AUTOSAR XML (schema 00051)
standard types defined: boolean, uint8, uint16, uint32, uint64, sint8, sint16, sint32
package /LionDriver  # Description of the existing LionDriver system in AUTOSAR terms, for OEM/Tier-1 integration. Neither the panda safety firmware (bare-metal STM32) nor openpilot (Linux processes) is an AUTOSAR stack. This file is not an AUTOSAR implementation and not a compliance claim; it carries no evidence credit.
package /LionDriver/ImplementationDataTypes
  impl type ByteBuffer: category=ARRAY  # Opaque bytes of variable length: a serialised cereal (Cap'n Proto) message, or the response of a control request. The bound is the 16-bit length field of a control request (WP-S-05 §4.2), used as an upper bound for the description only
    element byte: array-size=65535, array-size-semantics=VARIABLE-SIZE, implementation-data-type=uint8
  impl type CanPacket: category=ARRAY  # One CAN packet of the SPI stream (WP-S-05 §4.3): 6 header bytes and up to 64 payload bytes, with the 8-bit XOR checksum in byte 5
    element byte: array-size=70, array-size-semantics=VARIABLE-SIZE, implementation-data-type=uint8
package /LionDriver/Units
  unit km_per_h: display-name=km/h
  unit m_per_s2: display-name=m/s^2
  unit N: display-name=N
package /LionDriver/CompuMethods
  compu method WHEEL_SPEEDS_WHEEL_SPEED_FR: phys=raw*0.01-67.67; unit km/h  # phys = offset + factor × raw, from the DBC
  compu method WHEEL_SPEEDS_WHEEL_SPEED_FL: phys=raw*0.01-67.67; unit km/h  # phys = offset + factor × raw, from the DBC
  compu method WHEEL_SPEEDS_WHEEL_SPEED_RR: phys=raw*0.01-67.67; unit km/h  # phys = offset + factor × raw, from the DBC
  compu method WHEEL_SPEEDS_WHEEL_SPEED_RL: phys=raw*0.01-67.67; unit km/h  # phys = offset + factor × raw, from the DBC
  compu method SPEED_SPEED: phys=raw*0.01; unit km/h  # phys = offset + factor × raw, from the DBC
  compu method STEERING_LTA_ANGLE: phys=raw*0.5  # phys = offset + factor × raw, from the DBC
  compu method STEERING_LTA_STEER_ANGLE_CMD: phys=raw*0.0573  # phys = offset + factor × raw, from the DBC
  compu method PCM_CRUISE_ACCEL_NET: phys=raw/1024; unit m/s^2  # phys = offset + factor × raw, from the DBC
  compu method PCM_CRUISE_NEUTRAL_FORCE: phys=raw*2; unit N  # phys = offset + factor × raw, from the DBC
  compu method PCM_CRUISE_2_SET_SPEED: phys=raw; unit km/h  # phys = offset + factor × raw, from the DBC
  compu method STEER_TORQUE_SENSOR_STEER_ANGLE: phys=raw*0.0573  # phys = offset + factor × raw, from the DBC
  compu method PRE_COLLISION_FORCE: phys=raw*2; unit N  # phys = offset + factor × raw, from the DBC
  compu method ACC_CONTROL_ACCEL_CMD: phys=raw*0.001; unit m/s^2  # phys = offset + factor × raw, from the DBC
  compu method ACC_CONTROL_ACCEL_CMD_ALT: phys=raw*0.05; unit m/s^2  # phys = offset + factor × raw, from the DBC
  compu method PRE_COLLISION_2_DSS1GDRV: phys=raw*0.1; unit m/s^2  # phys = offset + factor × raw, from the DBC
package /LionDriver/PortInterfaces
  28 x sender receiver interface:
    If_WHEEL_SPEEDS  # The signals of CAN frame 0x0aa WHEEL_SPEEDS, one data element each (DBC opendbc_repo/opendbc/dbc/generator/toyota/_toyota_2017.dbc)
      8 x data:
        WHEEL_SPEED_FR_FAULT: type=boolean
        WHEEL_SPEED_FR: compu-method=WHEEL_SPEEDS_WHEEL_SPEED_FR, type=uint16
        WHEEL_SPEED_FL_FAULT: type=boolean
        WHEEL_SPEED_FL: compu-method=WHEEL_SPEEDS_WHEEL_SPEED_FL, type=uint16
        WHEEL_SPEED_RR_FAULT: type=boolean
        WHEEL_SPEED_RR: compu-method=WHEEL_SPEEDS_WHEEL_SPEED_RR, type=uint16
        WHEEL_SPEED_RL_FAULT: type=boolean
        WHEEL_SPEED_RL: compu-method=WHEEL_SPEEDS_WHEEL_SPEED_RL, type=uint16
    If_SPEED  # The signals of CAN frame 0x0b4 SPEED, one data element each (DBC opendbc_repo/opendbc/dbc/generator/toyota/_toyota_2017.dbc)
      data ENCODER: type=uint8
      data SPEED: compu-method=SPEED_SPEED, type=uint16
      data CHECKSUM: type=uint8
    If_STEERING_LTA  # The signals of CAN frame 0x191 STEERING_LTA, one data element each (DBC opendbc_repo/opendbc/dbc/generator/toyota/toyota_nodsu_pt.dbc)
      12 x data:
        CHECKSUM: type=uint8
        SETME_X3: type=uint8
        PERCENTAGE: type=uint8
        TORQUE_WIND_DOWN: type=uint8
        ANGLE: compu-method=STEERING_LTA_ANGLE, type=sint8
        STEER_ANGLE_CMD: compu-method=STEERING_LTA_STEER_ANGLE_CMD, type=sint16
        STEER_REQUEST_2: type=boolean
        LKA_ACTIVE: type=boolean
        CLEAR_HOLD_STEERING_ALERT: type=boolean
        COUNTER: type=uint8
        STEER_REQUEST: type=boolean
        SETME_X1: type=boolean
    If_PCM_CRUISE  # The signals of CAN frame 0x1d2 PCM_CRUISE, one data element each (DBC opendbc_repo/opendbc/dbc/generator/toyota/_toyota_adas_standard.dbc)
      8 x data:
        GAS_RELEASED: type=boolean
        CRUISE_ACTIVE: type=boolean
        ACC_BRAKING: type=boolean
        ACCEL_NET: compu-method=PCM_CRUISE_ACCEL_NET, type=sint16
        NEUTRAL_FORCE: compu-method=PCM_CRUISE_NEUTRAL_FORCE, type=sint16
        CRUISE_STATE: type=uint8
        CANCEL_REQ: type=boolean
        CHECKSUM: type=uint8
    If_PCM_CRUISE_2  # The signals of CAN frame 0x1d3 PCM_CRUISE_2, one data element each (DBC opendbc_repo/opendbc/dbc/generator/toyota/_toyota_2017.dbc)
      7 x data:
        BRAKE_PRESSED: type=boolean
        PCM_FOLLOW_DISTANCE: type=uint8
        LOW_SPEED_LOCKOUT: type=uint8
        MAIN_ON: type=boolean
        SET_SPEED: compu-method=PCM_CRUISE_2_SET_SPEED, type=uint8
        ACC_FAULTED: type=boolean
        CHECKSUM: type=uint8
    If_BRAKE_MODULE  # The signals of CAN frame 0x226 BRAKE_MODULE, one data element each (DBC opendbc_repo/opendbc/dbc/generator/toyota/toyota_nodsu_pt.dbc)
      data BRAKE_PRESSURE: type=uint16
      data BRAKE_POSITION: type=uint16
      data BRAKE_PRESSED: type=boolean
    If_STEER_TORQUE_SENSOR  # The signals of CAN frame 0x260 STEER_TORQUE_SENSOR, one data element each (DBC opendbc_repo/opendbc/dbc/generator/toyota/_toyota_2017.dbc)
      6 x data:
        STEER_TORQUE_EPS: type=sint16
        STEER_TORQUE_DRIVER: type=sint16
        STEER_ANGLE: compu-method=STEER_TORQUE_SENSOR_STEER_ANGLE, type=sint16
        STEER_ANGLE_INITIALIZING: type=boolean
        STEER_OVERRIDE: type=boolean
        CHECKSUM: type=uint8
    If_EPS_STATUS  # The signals of CAN frame 0x262 EPS_STATUS, one data element each (DBC opendbc_repo/opendbc/dbc/generator/toyota/toyota_nodsu_pt.dbc)
      5 x data:
        IPAS_STATE: type=uint8
        LKA_STATE: type=uint8
        LTA_STATE: type=uint8
        TYPE: type=boolean
        CHECKSUM: type=uint8
    If_PRE_COLLISION  # The signals of CAN frame 0x283 PRE_COLLISION, one data element each (DBC opendbc_repo/opendbc/dbc/generator/toyota/_toyota_adas_standard.dbc)
      9 x data:
        COUNTER: type=uint8
        SET_ME_X00: type=uint8
        FORCE: compu-method=PRE_COLLISION_FORCE, type=sint16
        SET_ME_X002: type=uint8
        BRAKE_STATUS: type=uint8
        STATE: type=uint8
        SET_ME_X003: type=boolean
        PRECOLLISION_ACTIVE: type=boolean
        CHECKSUM: type=uint8
    If_STEERING_LKA  # The signals of CAN frame 0x2e4 STEERING_LKA, one data element each (DBC opendbc_repo/opendbc/dbc/generator/toyota/_toyota_adas_standard.dbc)
      6 x data:
        LKA_STATE: type=uint8
        STEER_REQUEST: type=boolean
        COUNTER: type=uint8
        SET_ME_1: type=boolean
        STEER_TORQUE_CMD: type=sint16
        CHECKSUM: type=uint8
    If_ACC_CONTROL  # The signals of CAN frame 0x343 ACC_CONTROL, one data element each (DBC opendbc_repo/opendbc/dbc/generator/toyota/_toyota_2017.dbc)
      15 x data:
        ACCEL_CMD: compu-method=ACC_CONTROL_ACCEL_CMD, type=sint16
        ALLOW_LONG_PRESS: type=uint8
        ACC_MALFUNCTION: type=boolean
        RADAR_DIRTY: type=boolean
        DISTANCE: type=boolean
        MINI_CAR: type=boolean
        ACC_TYPE: type=uint8
        CANCEL_REQ: type=boolean
        ACC_CUT_IN: type=boolean
        LEAD_VEHICLE_STOPPED: type=boolean
        PERMIT_BRAKING: type=boolean
        RELEASE_STANDSTILL: type=boolean
        ITS_CONNECT_LEAD: type=uint8
        ACCEL_CMD_ALT: compu-method=ACC_CONTROL_ACCEL_CMD_ALT, type=sint8
        CHECKSUM: type=uint8
    If_PRE_COLLISION_2  # The signals of CAN frame 0x344 PRE_COLLISION_2, one data element each (DBC opendbc_repo/opendbc/dbc/generator/toyota/_toyota_adas_standard.dbc)
      7 x data:
        DSS1GDRV: compu-method=PRE_COLLISION_2_DSS1GDRV, type=sint16
        PCSALM: type=boolean
        IBTRGR: type=boolean
        PBATRGR: type=uint8
        PREFILL: type=boolean
        AVSTRGR: type=boolean
        CHECKSUM: type=uint8
    If_PCS_HUD  # The signals of CAN frame 0x411 PCS_HUD, one data element each (DBC opendbc_repo/opendbc/dbc/generator/toyota/_toyota_2017.dbc)
      11 x data:
        PCS_INDICATOR: type=uint8
        FCW: type=boolean
        SET_ME_X20: type=uint8
        PCS_DUST: type=boolean
        PCS_TEMP: type=boolean
        PCS_DUST2: type=boolean
        PCS_TEMP2: type=boolean
        SET_ME_X10: type=uint8
        PCS_OFF: type=boolean
        FRD_ADJ: type=uint8
        PCS_SENSITIVITY: type=uint8
    If_LKAS_HUD  # The signals of CAN frame 0x412 LKAS_HUD, one data element each (DBC opendbc_repo/opendbc/dbc/generator/toyota/_toyota_2017.dbc)
      25 x data:
        BARRIERS: type=uint8
        RIGHT_LINE: type=uint8
        LEFT_LINE: type=uint8
        LKAS_STATUS: type=uint8
        LDA_ALERT: type=uint8
        LDW_EXIST: type=boolean
        TWO_BEEPS: type=boolean
        ADJUSTING_CAMERA: type=boolean
        LDA_UNAVAILABLE_QUIET: type=boolean
        LDA_MALFUNCTION: type=boolean
        LDA_UNAVAILABLE: type=boolean
        LDA_SENSITIVITY: type=uint8
        LDA_SA_TOGGLE: type=uint8
        LDA_MESSAGES: type=uint8
        LDA_ON_MESSAGE: type=uint8
        REPEATED_BEEPS: type=boolean
        LANE_SWAY_TOGGLE: type=boolean
        LANE_SWAY_SENSITIVITY: type=uint8
        TAKE_CONTROL: type=boolean
        LDA_FRONT_CAMERA_BLOCKED: type=boolean
        LANE_SWAY_BUZZER: type=uint8
        LANE_SWAY_FLD: type=uint8
        LANE_SWAY_WARNING: type=uint8
        SET_ME_X01: type=boolean
        SET_ME_X02: type=uint8
    If_Cereal_can  # cereal service 'can' (msgq publish/subscribe on the SoC; Cap'n Proto schema in cereal/)
      data can: type=ByteBuffer
    If_Cereal_carControl  # cereal service 'carControl' (msgq publish/subscribe on the SoC; Cap'n Proto schema in cereal/)
      data carControl: type=ByteBuffer
    If_Cereal_carOutput  # cereal service 'carOutput' (msgq publish/subscribe on the SoC; Cap'n Proto schema in cereal/)
      data carOutput: type=ByteBuffer
    If_Cereal_carState  # cereal service 'carState' (msgq publish/subscribe on the SoC; Cap'n Proto schema in cereal/)
      data carState: type=ByteBuffer
    If_Cereal_deviceState  # cereal service 'deviceState' (msgq publish/subscribe on the SoC; Cap'n Proto schema in cereal/)
      data deviceState: type=ByteBuffer
    If_Cereal_driverMonitoringState  # cereal service 'driverMonitoringState' (msgq publish/subscribe on the SoC; Cap'n Proto schema in cereal/)
      data driverMonitoringState: type=ByteBuffer
    If_Cereal_extrinsicsCalibration_deviceMotion_vehicleParameters_lateralTorqueParameters_lateralDelay  # cereal service 'extrinsicsCalibration, deviceMotion, vehicleParameters, lateralTorqueParameters, lateralDelay' (msgq publish/subscribe on the SoC; Cap'n Proto schema in cereal/)
      data extrinsicsCalibration_deviceMotion_vehicleParameters_lateralTorqueParameters_lateralDelay: type=ByteBuffer
    If_Cereal_longitudinalPlan  # cereal service 'longitudinalPlan' (msgq publish/subscribe on the SoC; Cap'n Proto schema in cereal/)
      data longitudinalPlan: type=ByteBuffer
    If_Cereal_modelV2  # cereal service 'modelV2' (msgq publish/subscribe on the SoC; Cap'n Proto schema in cereal/)
      data modelV2: type=ByteBuffer
    If_Cereal_onroadEvents  # cereal service 'onroadEvents' (msgq publish/subscribe on the SoC; Cap'n Proto schema in cereal/)
      data onroadEvents: type=ByteBuffer
    If_Cereal_pandaStates  # cereal service 'pandaStates' (msgq publish/subscribe on the SoC; Cap'n Proto schema in cereal/)
      data pandaStates: type=ByteBuffer
    If_Cereal_radarState  # cereal service 'radarState' (msgq publish/subscribe on the SoC; Cap'n Proto schema in cereal/)
      data radarState: type=ByteBuffer
    If_Cereal_selfdriveState  # cereal service 'selfdriveState' (msgq publish/subscribe on the SoC; Cap'n Proto schema in cereal/)
      data selfdriveState: type=ByteBuffer
    If_Cereal_sendcan  # cereal service 'sendcan' (msgq publish/subscribe on the SoC; Cap'n Proto schema in cereal/)
      data sendcan: type=ByteBuffer
  client server interface If_PandaControl  # Control requests of SPI endpoint 0 (ControlPacket_t: request, param1, param2, length; handler comms_control_handler). One operation per request code of WP-S-05 §4.2
    36 x operation:
      Req_A8  # 0xa8 read microsecond timer | Effect on safety: none. Gating at the baseline: none. Required in a car mode: allow.
        arg param1: type=uint16, direction=IN
        arg param2: type=uint16, direction=IN
        arg response: type=ByteBuffer, direction=OUT
      Req_B0  # 0xb0 set IR power | Effect on safety: none (DM camera illumination: SOTIF). Gating at the baseline: none. Required in a car mode: allow.
        arg param1: type=uint16, direction=IN
        arg param2: type=uint16, direction=IN
        arg response: type=ByteBuffer, direction=OUT
      Req_B1  # 0xb1 fan power / rpm | Effect on safety: thermal. Gating at the baseline: none. Required in a car mode: allow.
        arg param1: type=uint16, direction=IN
        arg param2: type=uint16, direction=IN
        arg response: type=ByteBuffer, direction=OUT
      Req_B2  # 0xb2 fan power / rpm | Effect on safety: thermal. Gating at the baseline: none. Required in a car mode: allow.
        arg param1: type=uint16, direction=IN
        arg param2: type=uint16, direction=IN
        arg response: type=ByteBuffer, direction=OUT
      Req_B5  # 0xb5 deep sleep | Effect on safety: enters SILENT, power save. Gating at the baseline: ALLOW_DEBUG only (:92-98). Required in a car mode: absent.
        arg param1: type=uint16, direction=IN
        arg param2: type=uint16, direction=IN
        arg response: type=ByteBuffer, direction=OUT
      Req_B6  # 0xb6 read debug log | Effect on safety: none. Gating at the baseline: none. Required in a car mode: allow.
        arg param1: type=uint16, direction=IN
        arg param2: type=uint16, direction=IN
        arg response: type=ByteBuffer, direction=OUT
      Req_C0  # 0xc0 reset comms buffers | Effect on safety: may drop a partial CAN packet. Gating at the baseline: none. Required in a car mode: allow (logged).
        arg param1: type=uint16, direction=IN
        arg param2: type=uint16, direction=IN
        arg response: type=ByteBuffer, direction=OUT
      Req_C1  # 0xc1 read HW type, UID, serial, signature, version, packet versions | Effect on safety: none. Gating at the baseline: none. Required in a car mode: allow.
        arg param1: type=uint16, direction=IN
        arg param2: type=uint16, direction=IN
        arg response: type=ByteBuffer, direction=OUT
      Req_C3  # 0xc3 read HW type, UID, serial, signature, version, packet versions | Effect on safety: none. Gating at the baseline: none. Required in a car mode: allow.
        arg param1: type=uint16, direction=IN
        arg param2: type=uint16, direction=IN
        arg response: type=ByteBuffer, direction=OUT
      Req_D0  # 0xd0 read HW type, UID, serial, signature, version, packet versions | Effect on safety: none. Gating at the baseline: none. Required in a car mode: allow.
        arg param1: type=uint16, direction=IN
        arg param2: type=uint16, direction=IN
        arg response: type=ByteBuffer, direction=OUT
      Req_D3  # 0xd3 read HW type, UID, serial, signature, version, packet versions | Effect on safety: none. Gating at the baseline: none. Required in a car mode: allow.
        arg param1: type=uint16, direction=IN
        arg param2: type=uint16, direction=IN
        arg response: type=ByteBuffer, direction=OUT
      Req_D4  # 0xd4 read HW type, UID, serial, signature, version, packet versions | Effect on safety: none. Gating at the baseline: none. Required in a car mode: allow.
        arg param1: type=uint16, direction=IN
        arg param2: type=uint16, direction=IN
        arg response: type=ByteBuffer, direction=OUT
      Req_D6  # 0xd6 read HW type, UID, serial, signature, version, packet versions | Effect on safety: none. Gating at the baseline: none. Required in a car mode: allow.
        arg param1: type=uint16, direction=IN
        arg param2: type=uint16, direction=IN
        arg response: type=ByteBuffer, direction=OUT
      Req_DD  # 0xdd read HW type, UID, serial, signature, version, packet versions | Effect on safety: none. Gating at the baseline: none. Required in a car mode: allow.
        arg param1: type=uint16, direction=IN
        arg param2: type=uint16, direction=IN
        arg response: type=ByteBuffer, direction=OUT
      Req_C2  # 0xc2 CAN health | Effect on safety: none. Gating at the baseline: bounds-checked (:117). Required in a car mode: allow.
        arg param1: type=uint16, direction=IN
        arg param2: type=uint16, direction=IN
        arg response: type=ByteBuffer, direction=OUT
      Req_C4  # 0xc4 interrupt call rate | Effect on safety: none. Gating at the baseline: bounds-checked (:135). Required in a car mode: allow.
        arg param1: type=uint16, direction=IN
        arg param2: type=uint16, direction=IN
        arg response: type=ByteBuffer, direction=OUT
      Req_C5  # 0xc5 drive relay / ignition relay | Effect on safety: can release or engage relay at any time. Gating at the baseline: none (:144-147). Required in a car mode: reject.
        arg param1: type=uint16, direction=IN
        arg param2: type=uint16, direction=IN
        arg response: type=ByteBuffer, direction=OUT
      Req_C6  # 0xc6 read SoC GPIO | Effect on safety: none. Gating at the baseline: none. Required in a car mode: allow.
        arg param1: type=uint16, direction=IN
        arg param2: type=uint16, direction=IN
        arg response: type=ByteBuffer, direction=OUT
      Req_D1  # 0xd1 bootloader (param 0) / softloader (param 1) | Effect on safety: firmware replacement. Gating at the baseline: param 0 ALLOW_DEBUG; param 1 none (:164-185). Required in a car mode: reject param 1 in car mode.
        arg param1: type=uint16, direction=IN
        arg param2: type=uint16, direction=IN
        arg response: type=ByteBuffer, direction=OUT
      Req_D2  # 0xd2 health packet | Effect on safety: none (diagnostic input to SoC). Gating at the baseline: none. Required in a car mode: allow.
        arg param1: type=uint16, direction=IN
        arg param2: type=uint16, direction=IN
        arg response: type=ByteBuffer, direction=OUT
      Req_D8  # 0xd8 MCU reset | Effect on safety: → SS-S after reset. Gating at the baseline: none. Required in a car mode: allow (reset is safe if TSR-502 holds).
        arg param1: type=uint16, direction=IN
        arg param2: type=uint16, direction=IN
        arg response: type=ByteBuffer, direction=OUT
      Req_DB  # 0xdb OBD CAN multiplexing | Effect on safety: changes CAN pin routing. Gating at the baseline: none (:219-221). Required in a car mode: reject.
        arg param1: type=uint16, direction=IN
        arg param2: type=uint16, direction=IN
        arg response: type=ByteBuffer, direction=OUT
      Req_DC  # 0xdc set safety mode and parameter | Effect on safety: configures the envelope. Gating at the baseline: none (:222-225). Required in a car mode: only reference modes; de-escalation only once TOYOTA active.
        arg param1: type=uint16, direction=IN
        arg param2: type=uint16, direction=IN
        arg response: type=ByteBuffer, direction=OUT
      Req_DE  # 0xde CAN bit rate | Effect on safety: can disable a bus. Gating at the baseline: speed whitelist only (:233-240). Required in a car mode: reject.
        arg param1: type=uint16, direction=IN
        arg param2: type=uint16, direction=IN
        arg response: type=ByteBuffer, direction=OUT
      Req_DF  # 0xdf alternative experience | Effect on safety: changes safety behaviour flags. Gating at the baseline: only outside car modes (:241-247). Required in a car mode: keep; release value must be 0.
        arg param1: type=uint16, direction=IN
        arg param2: type=uint16, direction=IN
        arg response: type=ByteBuffer, direction=OUT
      Req_E5  # 0xe5 CAN loopback | Effect on safety: breaks bus communication. Gating at the baseline: none (:248-252). Required in a car mode: reject.
        arg param1: type=uint16, direction=IN
        arg param2: type=uint16, direction=IN
        arg response: type=ByteBuffer, direction=OUT
      Req_E6  # 0xe6 clock-source timer parameters | Effect on safety: timing. Gating at the baseline: none (:253-256). Required in a car mode: reject.
        arg param1: type=uint16, direction=IN
        arg param2: type=uint16, direction=IN
        arg response: type=ByteBuffer, direction=OUT
      Req_E7  # 0xe7 power save | Effect on safety: disables transceivers and CAN IRQs. Gating at the baseline: none (:257-260). Required in a car mode: reject while authority possible.
        arg param1: type=uint16, direction=IN
        arg param2: type=uint16, direction=IN
        arg response: type=ByteBuffer, direction=OUT
      Req_E8  # 0xe8 CAN-FD auto switching | Effect on safety: CAN config; param1 not bounds-checked (:261-264). Gating at the baseline: none. Required in a car mode: reject; bounds-check.
        arg param1: type=uint16, direction=IN
        arg param2: type=uint16, direction=IN
        arg response: type=ByteBuffer, direction=OUT
      Req_F1  # 0xf1 clear CAN queues | Effect on safety: can drop queued actuation/forwarded frames. Gating at the baseline: bus index checked (:265-276). Required in a car mode: reject in car mode.
        arg param1: type=uint16, direction=IN
        arg param2: type=uint16, direction=IN
        arg response: type=ByteBuffer, direction=OUT
      Req_F3  # 0xf3 heartbeat, param1 = engaged | Effect on safety: resets heartbeat counter, sets heartbeat_engaged. Gating at the baseline: none (:277-285). Required in a car mode: carry control-loop evidence.
        arg param1: type=uint16, direction=IN
        arg param2: type=uint16, direction=IN
        arg response: type=ByteBuffer, direction=OUT
      Req_F6  # 0xf6 siren enable | Effect on safety: warning. Gating at the baseline: none. Required in a car mode: allow.
        arg param1: type=uint16, direction=IN
        arg param2: type=uint16, direction=IN
        arg response: type=ByteBuffer, direction=OUT
      Req_F8  # 0xf8 disable heartbeat checks | Effect on safety: removes SoC supervision. Gating at the baseline: refused in car modes (:290-295). Required in a car mode: keep.
        arg param1: type=uint16, direction=IN
        arg param2: type=uint16, direction=IN
        arg response: type=ByteBuffer, direction=OUT
      Req_F9  # 0xf9 CAN-FD data rate / non-ISO | Effect on safety: CAN config. Gating at the baseline: bus index checked. Required in a car mode: reject.
        arg param1: type=uint16, direction=IN
        arg param2: type=uint16, direction=IN
        arg response: type=ByteBuffer, direction=OUT
      Req_FC  # 0xfc CAN-FD data rate / non-ISO | Effect on safety: CAN config. Gating at the baseline: bus index checked. Required in a car mode: reject.
        arg param1: type=uint16, direction=IN
        arg param2: type=uint16, direction=IN
        arg response: type=ByteBuffer, direction=OUT
      Req_FB  # 0xfb deep sleep (host panda.cc) | Effect on safety: —. Gating at the baseline: not handled in application (falls to default). Required in a car mode: —.
        arg param1: type=uint16, direction=IN
        arg param2: type=uint16, direction=IN
        arg response: type=ByteBuffer, direction=OUT
  sender receiver interface If_CanPacketsToMcu  # SoC → MCU, SPI endpoint 3: CAN frames to transmit; each passes the TX hook (WP-S-05 §4.3)
    data packet: type=CanPacket
  sender receiver interface If_CanPacketsToSoc  # MCU → SoC, SPI endpoint 1/0x81: received CAN frames and rejected TX frames returned with rejected = 1 (WP-S-05 §4.3)
    data packet: type=CanPacket
  client server interface If_SafetyHooks  # The safety hooks of opendbc's safety layer (opendbc/safety/safety.h), called by the panda firmware; a C function-pointer table, described here as a client-server interface
    operation RxHook  # safety_rx_hook: every received frame; RX checks (checksum, counter, timeout) and the state the envelope keeps
      arg packet: type=CanPacket, direction=IN
      arg valid: type=boolean, direction=OUT
    operation TxHook  # safety_tx_hook: every frame the SoC asks to send; allow-list, envelope limits, rate checks
      arg packet: type=CanPacket, direction=INOUT
      arg allowed: type=boolean, direction=OUT
    operation FwdHook  # safety_fwd_hook: bus-to-bus forwarding decision (bus 2 → 0 and 0 → 2); a TX message on bus 0 with check_relay is never forwarded from the camera
      arg bus: type=uint8, direction=IN
      arg address: type=uint32, direction=IN
      arg destination: type=sint32, direction=OUT
package /LionDriver/SwComponentTypes
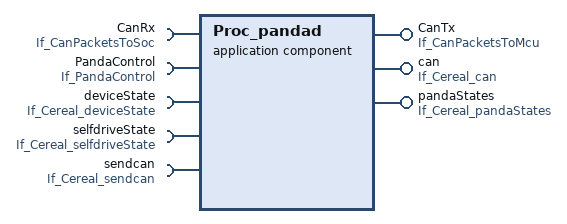
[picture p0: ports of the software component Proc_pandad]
  application sw component type Proc_pandad  # host.pandad | Firmware check and flash, SPI link, CAN in and out, heartbeat, safety-mode set. A Linux process of openpilot, not an AUTOSAR SWC.
    require port CanRx: required-interface=If_CanPacketsToSoc  # SPI endpoint 1
    provide port CanTx: provided-interface=If_CanPacketsToMcu  # SPI endpoint 3
    require port PandaControl: required-interface=If_PandaControl  # SPI endpoint 0
    provide port can: provided-interface=If_Cereal_can  # cereal 'can' at 100 Hz (WP-S-03 §9)
    require port deviceState: required-interface=If_Cereal_deviceState  # cereal 'deviceState' at 2 Hz (WP-S-03 §9)
    provide port pandaStates: provided-interface=If_Cereal_pandaStates  # cereal 'pandaStates' at 10 Hz (WP-S-03 §9)
    require port selfdriveState: required-interface=If_Cereal_selfdriveState  # cereal 'selfdriveState' at 100 Hz (WP-S-03 §9)
    require port sendcan: required-interface=If_Cereal_sendcan  # cereal 'sendcan' at 100 Hz (WP-S-03 §9)
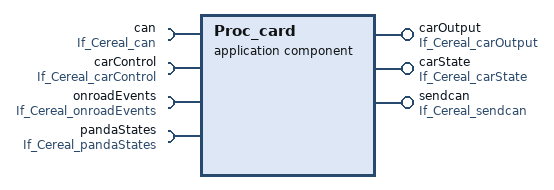
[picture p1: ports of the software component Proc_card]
  application sw component type Proc_card  # host.card | CAN parse to carState; carControl to sendcan; CarParams and fingerprint. A Linux process of openpilot, not an AUTOSAR SWC.
    require port can: required-interface=If_Cereal_can  # cereal 'can' at 100 Hz (WP-S-03 §9)
    require port carControl: required-interface=If_Cereal_carControl  # cereal 'carControl' at 100 Hz (WP-S-03 §9)
    provide port carOutput: provided-interface=If_Cereal_carOutput  # cereal 'carOutput' at 100 Hz (WP-S-03 §9)
    provide port carState: provided-interface=If_Cereal_carState  # cereal 'carState' at 100 Hz (WP-S-03 §9)
    require port onroadEvents: required-interface=If_Cereal_onroadEvents  # cereal 'onroadEvents' at 1 Hz (WP-S-03 §9)
    require port pandaStates: required-interface=If_Cereal_pandaStates  # cereal 'pandaStates' at 10 Hz (WP-S-03 §9)
    provide port sendcan: provided-interface=If_Cereal_sendcan  # cereal 'sendcan' at 100 Hz (WP-S-03 §9)
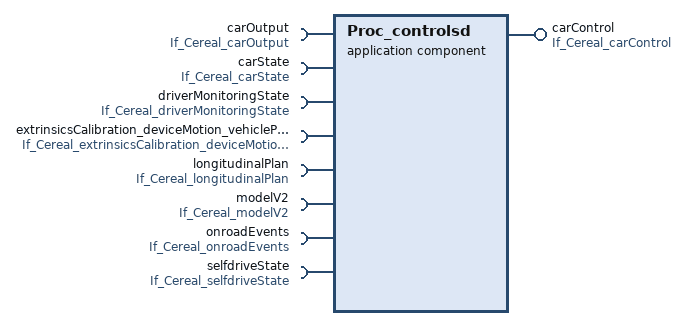
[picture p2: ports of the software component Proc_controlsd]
  application sw component type Proc_controlsd  # host.controlsd | Lateral and longitudinal control law. A Linux process of openpilot, not an AUTOSAR SWC.
    provide port carControl: provided-interface=If_Cereal_carControl  # cereal 'carControl' at 100 Hz (WP-S-03 §9)
    8 x require port:
      carOutput: required-interface=If_Cereal_carOutput  # cereal 'carOutput' at 100 Hz (WP-S-03 §9)
      carState: required-interface=If_Cereal_carState  # cereal 'carState' at 100 Hz (WP-S-03 §9)
      driverMonitoringState: required-interface=If_Cereal_driverMonitoringState  # cereal 'driverMonitoringState' at 20 Hz (WP-S-03 §9)
      extrinsicsCalibration_deviceMotion_vehicleParameters_lateralTorqueParameters_lateralDelay: required-interface=If_Cereal_extrinsicsCalibration_deviceMotion_vehicleParameters_lateralTorqueParameters_lateralDelay  # cereal 'extrinsicsCalibration, deviceMotion, vehicleParameters, lateralTorqueParameters, lateralDelay' at 20 Hz (WP-S-03 §9)
      longitudinalPlan: required-interface=If_Cereal_longitudinalPlan  # cereal 'longitudinalPlan' at 20 Hz (WP-S-03 §9)
      modelV2: required-interface=If_Cereal_modelV2  # cereal 'modelV2' at 20 Hz (WP-S-03 §9)
      onroadEvents: required-interface=If_Cereal_onroadEvents  # cereal 'onroadEvents' at 1 Hz (WP-S-03 §9)
      selfdriveState: required-interface=If_Cereal_selfdriveState  # cereal 'selfdriveState' at 100 Hz (WP-S-03 §9)
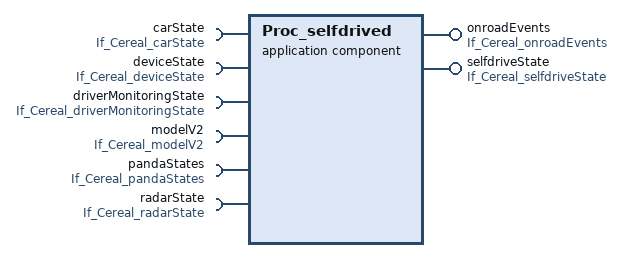
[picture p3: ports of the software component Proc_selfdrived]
  application sw component type Proc_selfdrived  # host.selfdrived | Engagement state machine, event classification, alerts. A Linux process of openpilot, not an AUTOSAR SWC.
    4 x require port:
      carState: required-interface=If_Cereal_carState  # cereal 'carState' at 100 Hz (WP-S-03 §9)
      deviceState: required-interface=If_Cereal_deviceState  # cereal 'deviceState' at 2 Hz (WP-S-03 §9)
      driverMonitoringState: required-interface=If_Cereal_driverMonitoringState  # cereal 'driverMonitoringState' at 20 Hz (WP-S-03 §9)
      modelV2: required-interface=If_Cereal_modelV2  # cereal 'modelV2' at 20 Hz (WP-S-03 §9)
    provide port onroadEvents: provided-interface=If_Cereal_onroadEvents  # cereal 'onroadEvents' at 1 Hz (WP-S-03 §9)
    require port pandaStates: required-interface=If_Cereal_pandaStates  # cereal 'pandaStates' at 10 Hz (WP-S-03 §9)
    require port radarState: required-interface=If_Cereal_radarState  # cereal 'radarState' at 20 Hz (WP-S-03 §9)
    provide port selfdriveState: provided-interface=If_Cereal_selfdriveState  # cereal 'selfdriveState' at 100 Hz (WP-S-03 §9)
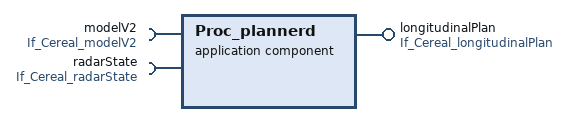
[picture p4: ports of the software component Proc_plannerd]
  application sw component type Proc_plannerd  # host.plannerd | Longitudinal plan. A Linux process of openpilot, not an AUTOSAR SWC.
    provide port longitudinalPlan: provided-interface=If_Cereal_longitudinalPlan  # cereal 'longitudinalPlan' at 20 Hz (WP-S-03 §9)
    require port modelV2: required-interface=If_Cereal_modelV2  # cereal 'modelV2' at 20 Hz (WP-S-03 §9)
    require port radarState: required-interface=If_Cereal_radarState  # cereal 'radarState' at 20 Hz (WP-S-03 §9)
  application sw component type Proc_radard  # host.radard | Lead fusion. A Linux process of openpilot, not an AUTOSAR SWC.
    provide port radarState: provided-interface=If_Cereal_radarState  # cereal 'radarState' at 20 Hz (WP-S-03 §9)
  application sw component type Proc_modeld  # host.modeld | Runs the driving model (E-02). A Linux process of openpilot, not an AUTOSAR SWC. Runs the ML model of E-02 (allocated to this process in the SysML model); E-02 is not a separate SWC.
    provide port modelV2: provided-interface=If_Cereal_modelV2  # cereal 'modelV2' at 20 Hz (WP-S-03 §9)
  application sw component type Proc_dm  # host.dm | Driver monitoring: dmonitoringmodeld runs the DM model (E-02), dmonitoringd applies the policy. A Linux process of openpilot, not an AUTOSAR SWC. Runs the ML model of E-02 (allocated to this process in the SysML model); E-02 is not a separate SWC.
    provide port driverMonitoringState: provided-interface=If_Cereal_driverMonitoringState  # cereal 'driverMonitoringState' at 20 Hz (WP-S-03 §9)
  application sw component type Proc_hmi  # host.hmi | ui and soundd: display and audible alerts. A Linux process of openpilot, not an AUTOSAR SWC.
  application sw component type Proc_manager  # host.manager | Process start and stop by run condition. A Linux process of openpilot, not an AUTOSAR SWC.
  application sw component type Proc_cereal  # host.cereal | Publish and subscribe, alive, valid and frequency checks. No authentication (GAP-20). A Linux process of openpilot, not an AUTOSAR SWC.
  application sw component type Proc_estimators  # estimators | locationd, calibrationd, paramsd, torqued, lagd, sensord, camerad: pose, calibration, vehicle parameters and sensors. A Linux process of openpilot, not an AUTOSAR SWC.
    provide port extrinsicsCalibration_deviceMotion_vehicleParameters_lateralTorqueParameters_lateralDelay: provided-interface=If_Cereal_extrinsicsCalibration_deviceMotion_vehicleParameters_lateralTorqueParameters_lateralDelay  # cereal 'extrinsicsCalibration, deviceMotion, vehicleParameters, lateralTorqueParameters, lateralDelay' at 20 Hz (WP-S-03 §9)
  application sw component type Proc_hardwared  # hardwared | Thermal and power management; deviceState.started gates onroad processes. A Linux process of openpilot, not an AUTOSAR SWC.
    provide port deviceState: provided-interface=If_Cereal_deviceState  # cereal 'deviceState' at 2 Hz (WP-S-03 §9)
  application sw component type Proc_remoteAndLogging  # remoteAndLogging | loggerd, uploader, athenad, updated, webrtcd and the other non-driving processes (F-09). Interference sources for FFI. A Linux process of openpilot, not an AUTOSAR SWC.
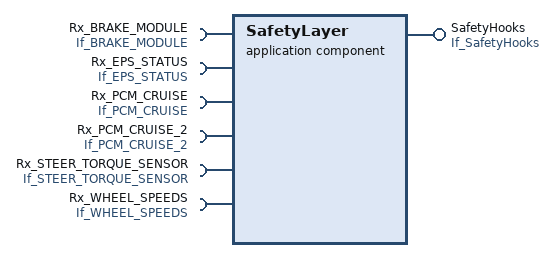
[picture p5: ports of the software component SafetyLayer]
  application sw component type SafetyLayer  # E-03a Safety layer | opendbc safety core + Toyota mode, compiled into the panda firmware Bare-metal C in the panda firmware, not an AUTOSAR SWC. Units: panda.safety.core, panda.safety.core.rx_engagement, panda.safety.core.tx_rate_check, panda.safety.lateral, panda.safety.longitudinal, panda.safety.helpers, panda.safety.toyota, panda.safety.toyota.eps_fault, panda.safety.toyota.ref_rx_set, panda.safety.toyota.cruise_main, panda.safety.toyota.tx_budgets, panda.safety.defaults, panda.safety.ignition, panda.safety.other_modes
    6 x require port:
      Rx_BRAKE_MODULE: required-interface=If_BRAKE_MODULE  # bus 0, RX check and envelope inputs
      Rx_EPS_STATUS: required-interface=If_EPS_STATUS  # bus 0, RX check and envelope inputs
      Rx_PCM_CRUISE: required-interface=If_PCM_CRUISE  # bus 0, RX check and envelope inputs
      Rx_PCM_CRUISE_2: required-interface=If_PCM_CRUISE_2  # bus 0, RX check and envelope inputs
      Rx_STEER_TORQUE_SENSOR: required-interface=If_STEER_TORQUE_SENSOR  # bus 0, RX check and envelope inputs
      Rx_WHEEL_SPEEDS: required-interface=If_WHEEL_SPEEDS  # bus 0, RX check and envelope inputs
    provide port SafetyHooks: provided-interface=If_SafetyHooks
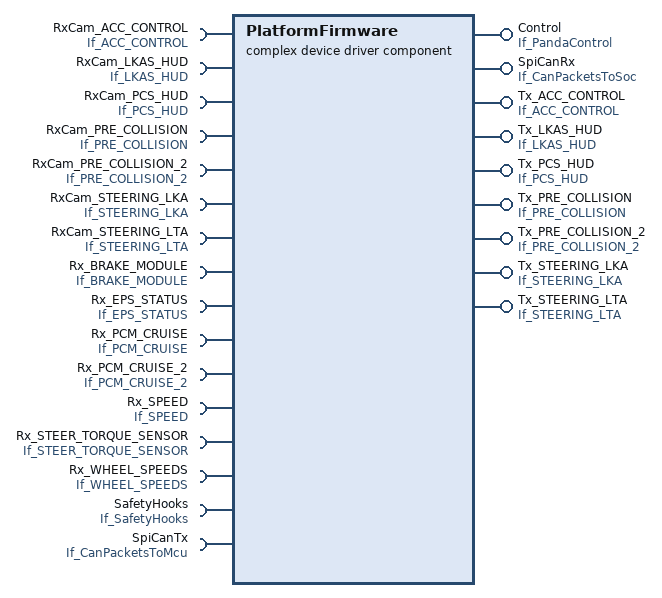
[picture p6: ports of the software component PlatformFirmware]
  complex device driver sw component type PlatformFirmware  # E-03b Panda platform firmware | main loop, tick handler, CAN/SPI drivers, comms handlers, harness/relay driver, fault handling, bootstub Bare-metal C (panda board firmware), described as a complex device driver because it owns the SPI, FDCAN, GPIO and audio hardware directly. Units: panda.main, panda.main.safety_task, panda.drivers.heartbeat_monitor, panda.drivers.heartbeat_siren, panda.drivers.eps_fault_siren, panda.drivers.hw_watchdog, panda.drivers.irq_priorities, panda.reference_lock, panda.comms, panda.drivers.spi, panda.drivers.usb, panda.drivers.fdcan, panda.drivers.harness, panda.sys.faults, panda.sys.power_saving, panda.drivers.siren, panda.platform, panda.bootstub
    provide port Control: provided-interface=If_PandaControl  # SPI endpoint 0 (comms_control_handler)
    15 x require port:
      RxCam_ACC_CONTROL: required-interface=If_ACC_CONTROL  # bus 2 (camera side); blocked: the item sends its own on bus 0
      RxCam_LKAS_HUD: required-interface=If_LKAS_HUD  # bus 2 (camera side); blocked: the item sends its own on bus 0
      RxCam_PCS_HUD: required-interface=If_PCS_HUD  # bus 2 (camera side); forwarded unchanged to bus 0
      RxCam_PRE_COLLISION: required-interface=If_PRE_COLLISION  # bus 2 (camera side); forwarded unchanged to bus 0
      RxCam_PRE_COLLISION_2: required-interface=If_PRE_COLLISION_2  # bus 2 (camera side); forwarded unchanged to bus 0
      RxCam_STEERING_LKA: required-interface=If_STEERING_LKA  # bus 2 (camera side); blocked: the item sends its own on bus 0
      RxCam_STEERING_LTA: required-interface=If_STEERING_LTA  # bus 2 (camera side); blocked: the item sends its own on bus 0
      Rx_BRAKE_MODULE: required-interface=If_BRAKE_MODULE  # bus 0, queued to the SoC
      Rx_EPS_STATUS: required-interface=If_EPS_STATUS  # bus 0, queued to the SoC
      Rx_PCM_CRUISE: required-interface=If_PCM_CRUISE  # bus 0, queued to the SoC
      Rx_PCM_CRUISE_2: required-interface=If_PCM_CRUISE_2  # bus 0, queued to the SoC
      Rx_SPEED: required-interface=If_SPEED  # bus 0, queued to the SoC
      Rx_STEER_TORQUE_SENSOR: required-interface=If_STEER_TORQUE_SENSOR  # bus 0, queued to the SoC
      Rx_WHEEL_SPEEDS: required-interface=If_WHEEL_SPEEDS  # bus 0, queued to the SoC
      SafetyHooks: required-interface=If_SafetyHooks
    provide port SpiCanRx: provided-interface=If_CanPacketsToSoc  # SPI endpoint 1
    require port SpiCanTx: required-interface=If_CanPacketsToMcu  # SPI endpoint 3
    7 x provide port:
      Tx_ACC_CONTROL: provided-interface=If_ACC_CONTROL  # bus 0
      Tx_LKAS_HUD: provided-interface=If_LKAS_HUD  # bus 0
      Tx_PCS_HUD: provided-interface=If_PCS_HUD  # bus 0
      Tx_PRE_COLLISION: provided-interface=If_PRE_COLLISION  # bus 0
      Tx_PRE_COLLISION_2: provided-interface=If_PRE_COLLISION_2  # bus 0
      Tx_STEERING_LKA: provided-interface=If_STEERING_LKA  # bus 0
      Tx_STEERING_LTA: provided-interface=If_STEERING_LTA  # bus 0
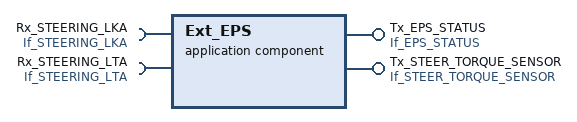
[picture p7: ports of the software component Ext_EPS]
  application sw component type Ext_EPS  # EXT-EPS (vehicle ECU) | Vehicle ECU at the item boundary, outside the item: Receives LKA torque requests; reports driver torque, EPS torque and LKA state. Only its CAN interface to the item is described.
    require port Rx_STEERING_LKA: required-interface=If_STEERING_LKA
    require port Rx_STEERING_LTA: required-interface=If_STEERING_LTA
    provide port Tx_EPS_STATUS: provided-interface=If_EPS_STATUS
    provide port Tx_STEER_TORQUE_SENSOR: provided-interface=If_STEER_TORQUE_SENSOR
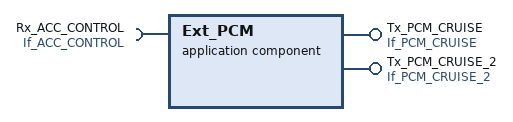
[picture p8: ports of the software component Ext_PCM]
  application sw component type Ext_PCM  # EXT-PCM (vehicle ECU) | Vehicle ECU at the item boundary, outside the item: Engine and powertrain ECU: ACC acceleration, permit-braking, cruise state. Only its CAN interface to the item is described.
    require port Rx_ACC_CONTROL: required-interface=If_ACC_CONTROL
    provide port Tx_PCM_CRUISE: provided-interface=If_PCM_CRUISE
    provide port Tx_PCM_CRUISE_2: provided-interface=If_PCM_CRUISE_2
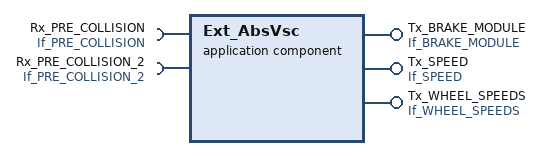
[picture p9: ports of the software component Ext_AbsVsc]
  application sw component type Ext_AbsVsc  # absVsc (vehicle ECU) | Vehicle ECU at the item boundary, outside the item: Brake actuator: wheel speeds and brake-pedal state. Only its CAN interface to the item is described.
    require port Rx_PRE_COLLISION: required-interface=If_PRE_COLLISION
    require port Rx_PRE_COLLISION_2: required-interface=If_PRE_COLLISION_2
    provide port Tx_BRAKE_MODULE: provided-interface=If_BRAKE_MODULE
    provide port Tx_SPEED: provided-interface=If_SPEED
    provide port Tx_WHEEL_SPEEDS: provided-interface=If_WHEEL_SPEEDS
  application sw component type Ext_Cluster  # EXT-CLU (vehicle ECU) | Vehicle ECU at the item boundary, outside the item: Instrument cluster and cruise stalk: cruise main, set, resume, cancel; LKA HUD. Only its CAN interface to the item is described.
    require port Rx_LKAS_HUD: required-interface=If_LKAS_HUD
    require port Rx_PCS_HUD: required-interface=If_PCS_HUD
  application sw component type Ext_ForwardCamera  # forwardCamera (vehicle ECU) | Vehicle ECU at the item boundary, outside the item: Toyota forward camera: LKA and ACC outputs intercepted, PCS outputs forwarded. Only its CAN interface to the item is described.
    7 x provide port:
      Tx_ACC_CONTROL: provided-interface=If_ACC_CONTROL
      Tx_LKAS_HUD: provided-interface=If_LKAS_HUD
      Tx_PCS_HUD: provided-interface=If_PCS_HUD
      Tx_PRE_COLLISION: provided-interface=If_PRE_COLLISION
      Tx_PRE_COLLISION_2: provided-interface=If_PRE_COLLISION_2
      Tx_STEERING_LKA: provided-interface=If_STEERING_LKA
      Tx_STEERING_LTA: provided-interface=If_STEERING_LTA
  composition sw component type SocSoftware  # E-01 SoC software | openpilot processes on AGNOS Linux (Qualcomm SoC); §8 openpilot processes on Linux; none of them is an AUTOSAR SWC.
    require port CanRx: required-interface=If_CanPacketsToSoc
    provide port CanTx: provided-interface=If_CanPacketsToMcu
    require port PandaControl: required-interface=If_PandaControl
    14 x component:
      Proc_pandad: type=Proc_pandad
      Proc_card: type=Proc_card
      Proc_controlsd: type=Proc_controlsd
      Proc_selfdrived: type=Proc_selfdrived
      Proc_plannerd: type=Proc_plannerd
      Proc_radard: type=Proc_radard
      Proc_modeld: type=Proc_modeld
      Proc_dm: type=Proc_dm
      Proc_hmi: type=Proc_hmi
      Proc_manager: type=Proc_manager
      Proc_cereal: type=Proc_cereal
      Proc_estimators: type=Proc_estimators
      Proc_hardwared: type=Proc_hardwared
      Proc_remoteAndLogging: type=Proc_remoteAndLogging
    connect Proc_pandad.can -> Proc_card.can
    connect Proc_controlsd.carControl -> Proc_card.carControl
    connect Proc_card.carOutput -> Proc_controlsd.carOutput
    connect Proc_card.carState -> Proc_controlsd.carState
    connect Proc_card.carState -> Proc_selfdrived.carState
    connect Proc_hardwared.deviceState -> Proc_pandad.deviceState
    connect Proc_hardwared.deviceState -> Proc_selfdrived.deviceState
    connect Proc_dm.driverMonitoringState -> Proc_controlsd.driverMonitoringState
    connect Proc_dm.driverMonitoringState -> Proc_selfdrived.driverMonitoringState
    connect Proc_estimators.extrinsicsCalibration_deviceMotion_vehicleParameters_lateralTorqueParameters_lateralDelay -> Proc_controlsd.extrinsicsCalibration_deviceMotion_vehicleParameters_lateralTorqueParameters_lateralDelay
    connect Proc_plannerd.longitudinalPlan -> Proc_controlsd.longitudinalPlan
    connect Proc_modeld.modelV2 -> Proc_controlsd.modelV2
    connect Proc_modeld.modelV2 -> Proc_plannerd.modelV2
    connect Proc_modeld.modelV2 -> Proc_selfdrived.modelV2
    connect Proc_selfdrived.onroadEvents -> Proc_card.onroadEvents
    connect Proc_selfdrived.onroadEvents -> Proc_controlsd.onroadEvents
    connect Proc_pandad.pandaStates -> Proc_card.pandaStates
    connect Proc_pandad.pandaStates -> Proc_selfdrived.pandaStates
    connect Proc_radard.radarState -> Proc_plannerd.radarState
    connect Proc_radard.radarState -> Proc_selfdrived.radarState
    connect Proc_selfdrived.selfdriveState -> Proc_controlsd.selfdriveState
    connect Proc_selfdrived.selfdriveState -> Proc_pandad.selfdriveState
    connect Proc_card.sendcan -> Proc_pandad.sendcan
    delegate Proc_pandad.PandaControl <-> outer port SocSoftware/PandaControl
    delegate Proc_pandad.CanTx <-> outer port SocSoftware/CanTx
    delegate Proc_pandad.CanRx <-> outer port SocSoftware/CanRx
  composition sw component type SafetyMcuFirmware  # E-03 safety MCU firmware | The panda firmware on the STM32H7 safety MCU: bare metal, no AUTOSAR stack.
    provide port Control: provided-interface=If_PandaControl
    14 x require port:
      RxCam_ACC_CONTROL: required-interface=If_ACC_CONTROL
      RxCam_LKAS_HUD: required-interface=If_LKAS_HUD
      RxCam_PCS_HUD: required-interface=If_PCS_HUD
      RxCam_PRE_COLLISION: required-interface=If_PRE_COLLISION
      RxCam_PRE_COLLISION_2: required-interface=If_PRE_COLLISION_2
      RxCam_STEERING_LKA: required-interface=If_STEERING_LKA
      RxCam_STEERING_LTA: required-interface=If_STEERING_LTA
      Rx_BRAKE_MODULE: required-interface=If_BRAKE_MODULE
      Rx_EPS_STATUS: required-interface=If_EPS_STATUS
      Rx_PCM_CRUISE: required-interface=If_PCM_CRUISE
      Rx_PCM_CRUISE_2: required-interface=If_PCM_CRUISE_2
      Rx_SPEED: required-interface=If_SPEED
      Rx_STEER_TORQUE_SENSOR: required-interface=If_STEER_TORQUE_SENSOR
      Rx_WHEEL_SPEEDS: required-interface=If_WHEEL_SPEEDS
    provide port SpiCanRx: provided-interface=If_CanPacketsToSoc
    require port SpiCanTx: required-interface=If_CanPacketsToMcu
    7 x provide port:
      Tx_ACC_CONTROL: provided-interface=If_ACC_CONTROL
      Tx_LKAS_HUD: provided-interface=If_LKAS_HUD
      Tx_PCS_HUD: provided-interface=If_PCS_HUD
      Tx_PRE_COLLISION: provided-interface=If_PRE_COLLISION
      Tx_PRE_COLLISION_2: provided-interface=If_PRE_COLLISION_2
      Tx_STEERING_LKA: provided-interface=If_STEERING_LKA
      Tx_STEERING_LTA: provided-interface=If_STEERING_LTA
    component SafetyLayer: type=SafetyLayer
    component PlatformFirmware: type=PlatformFirmware
    connect SafetyLayer.SafetyHooks -> PlatformFirmware.SafetyHooks
    delegate PlatformFirmware.Control <-> outer port SafetyMcuFirmware/Control
    delegate PlatformFirmware.SpiCanTx <-> outer port SafetyMcuFirmware/SpiCanTx
    delegate PlatformFirmware.SpiCanRx <-> outer port SafetyMcuFirmware/SpiCanRx
    delegate SafetyLayer.Rx_WHEEL_SPEEDS <-> outer port SafetyMcuFirmware/Rx_WHEEL_SPEEDS
    delegate PlatformFirmware.Rx_WHEEL_SPEEDS <-> outer port SafetyMcuFirmware/Rx_WHEEL_SPEEDS
    delegate PlatformFirmware.Rx_SPEED <-> outer port SafetyMcuFirmware/Rx_SPEED
    delegate PlatformFirmware.Tx_STEERING_LTA <-> outer port SafetyMcuFirmware/Tx_STEERING_LTA
    delegate SafetyLayer.Rx_PCM_CRUISE <-> outer port SafetyMcuFirmware/Rx_PCM_CRUISE
    delegate PlatformFirmware.Rx_PCM_CRUISE <-> outer port SafetyMcuFirmware/Rx_PCM_CRUISE
    delegate SafetyLayer.Rx_PCM_CRUISE_2 <-> outer port SafetyMcuFirmware/Rx_PCM_CRUISE_2
    delegate PlatformFirmware.Rx_PCM_CRUISE_2 <-> outer port SafetyMcuFirmware/Rx_PCM_CRUISE_2
    delegate SafetyLayer.Rx_BRAKE_MODULE <-> outer port SafetyMcuFirmware/Rx_BRAKE_MODULE
    delegate PlatformFirmware.Rx_BRAKE_MODULE <-> outer port SafetyMcuFirmware/Rx_BRAKE_MODULE
    delegate SafetyLayer.Rx_STEER_TORQUE_SENSOR <-> outer port SafetyMcuFirmware/Rx_STEER_TORQUE_SENSOR
    delegate PlatformFirmware.Rx_STEER_TORQUE_SENSOR <-> outer port SafetyMcuFirmware/Rx_STEER_TORQUE_SENSOR
    delegate SafetyLayer.Rx_EPS_STATUS <-> outer port SafetyMcuFirmware/Rx_EPS_STATUS
    delegate PlatformFirmware.Rx_EPS_STATUS <-> outer port SafetyMcuFirmware/Rx_EPS_STATUS
    delegate PlatformFirmware.Tx_PRE_COLLISION <-> outer port SafetyMcuFirmware/Tx_PRE_COLLISION
    delegate PlatformFirmware.Tx_STEERING_LKA <-> outer port SafetyMcuFirmware/Tx_STEERING_LKA
    delegate PlatformFirmware.Tx_ACC_CONTROL <-> outer port SafetyMcuFirmware/Tx_ACC_CONTROL
    delegate PlatformFirmware.Tx_PRE_COLLISION_2 <-> outer port SafetyMcuFirmware/Tx_PRE_COLLISION_2
    delegate PlatformFirmware.Tx_PCS_HUD <-> outer port SafetyMcuFirmware/Tx_PCS_HUD
    delegate PlatformFirmware.Tx_LKAS_HUD <-> outer port SafetyMcuFirmware/Tx_LKAS_HUD
    delegate PlatformFirmware.RxCam_STEERING_LTA <-> outer port SafetyMcuFirmware/RxCam_STEERING_LTA
    delegate PlatformFirmware.RxCam_PRE_COLLISION <-> outer port SafetyMcuFirmware/RxCam_PRE_COLLISION
    delegate PlatformFirmware.RxCam_STEERING_LKA <-> outer port SafetyMcuFirmware/RxCam_STEERING_LKA
    delegate PlatformFirmware.RxCam_ACC_CONTROL <-> outer port SafetyMcuFirmware/RxCam_ACC_CONTROL
    delegate PlatformFirmware.RxCam_PRE_COLLISION_2 <-> outer port SafetyMcuFirmware/RxCam_PRE_COLLISION_2
    delegate PlatformFirmware.RxCam_PCS_HUD <-> outer port SafetyMcuFirmware/RxCam_PCS_HUD
    delegate PlatformFirmware.RxCam_LKAS_HUD <-> outer port SafetyMcuFirmware/RxCam_LKAS_HUD
  composition sw component type LdSda  # LD-SDA (the item) | LD-SDA, the item: openpilot on the SoC and the panda safety firmware. E-02 runs inside modeld and dm; E-04 hardware and E-05 harness are ECU-level and physical and appear as ECU instances and buses.
    14 x require port:
      RxCam_ACC_CONTROL: required-interface=If_ACC_CONTROL
      RxCam_LKAS_HUD: required-interface=If_LKAS_HUD
      RxCam_PCS_HUD: required-interface=If_PCS_HUD
      RxCam_PRE_COLLISION: required-interface=If_PRE_COLLISION
      RxCam_PRE_COLLISION_2: required-interface=If_PRE_COLLISION_2
      RxCam_STEERING_LKA: required-interface=If_STEERING_LKA
      RxCam_STEERING_LTA: required-interface=If_STEERING_LTA
      Rx_BRAKE_MODULE: required-interface=If_BRAKE_MODULE
      Rx_EPS_STATUS: required-interface=If_EPS_STATUS
      Rx_PCM_CRUISE: required-interface=If_PCM_CRUISE
      Rx_PCM_CRUISE_2: required-interface=If_PCM_CRUISE_2
      Rx_SPEED: required-interface=If_SPEED
      Rx_STEER_TORQUE_SENSOR: required-interface=If_STEER_TORQUE_SENSOR
      Rx_WHEEL_SPEEDS: required-interface=If_WHEEL_SPEEDS
    7 x provide port:
      Tx_ACC_CONTROL: provided-interface=If_ACC_CONTROL
      Tx_LKAS_HUD: provided-interface=If_LKAS_HUD
      Tx_PCS_HUD: provided-interface=If_PCS_HUD
      Tx_PRE_COLLISION: provided-interface=If_PRE_COLLISION
      Tx_PRE_COLLISION_2: provided-interface=If_PRE_COLLISION_2
      Tx_STEERING_LKA: provided-interface=If_STEERING_LKA
      Tx_STEERING_LTA: provided-interface=If_STEERING_LTA
    component SocSoftware: type=SocSoftware
    component SafetyMcuFirmware: type=SafetyMcuFirmware
    connect SafetyMcuFirmware.Control -> SocSoftware.PandaControl
    connect SocSoftware.CanTx -> SafetyMcuFirmware.SpiCanTx
    connect SafetyMcuFirmware.SpiCanRx -> SocSoftware.CanRx
    delegate SafetyMcuFirmware.Rx_WHEEL_SPEEDS <-> outer port LdSda/Rx_WHEEL_SPEEDS
    delegate SafetyMcuFirmware.Rx_SPEED <-> outer port LdSda/Rx_SPEED
    delegate SafetyMcuFirmware.Tx_STEERING_LTA <-> outer port LdSda/Tx_STEERING_LTA
    delegate SafetyMcuFirmware.Rx_PCM_CRUISE <-> outer port LdSda/Rx_PCM_CRUISE
    delegate SafetyMcuFirmware.Rx_PCM_CRUISE_2 <-> outer port LdSda/Rx_PCM_CRUISE_2
    delegate SafetyMcuFirmware.Rx_BRAKE_MODULE <-> outer port LdSda/Rx_BRAKE_MODULE
    delegate SafetyMcuFirmware.Rx_STEER_TORQUE_SENSOR <-> outer port LdSda/Rx_STEER_TORQUE_SENSOR
    delegate SafetyMcuFirmware.Rx_EPS_STATUS <-> outer port LdSda/Rx_EPS_STATUS
    delegate SafetyMcuFirmware.Tx_PRE_COLLISION <-> outer port LdSda/Tx_PRE_COLLISION
    delegate SafetyMcuFirmware.Tx_STEERING_LKA <-> outer port LdSda/Tx_STEERING_LKA
    delegate SafetyMcuFirmware.Tx_ACC_CONTROL <-> outer port LdSda/Tx_ACC_CONTROL
    delegate SafetyMcuFirmware.Tx_PRE_COLLISION_2 <-> outer port LdSda/Tx_PRE_COLLISION_2
    delegate SafetyMcuFirmware.Tx_PCS_HUD <-> outer port LdSda/Tx_PCS_HUD
    delegate SafetyMcuFirmware.Tx_LKAS_HUD <-> outer port LdSda/Tx_LKAS_HUD
    delegate SafetyMcuFirmware.RxCam_STEERING_LTA <-> outer port LdSda/RxCam_STEERING_LTA
    delegate SafetyMcuFirmware.RxCam_PRE_COLLISION <-> outer port LdSda/RxCam_PRE_COLLISION
    delegate SafetyMcuFirmware.RxCam_STEERING_LKA <-> outer port LdSda/RxCam_STEERING_LKA
    delegate SafetyMcuFirmware.RxCam_ACC_CONTROL <-> outer port LdSda/RxCam_ACC_CONTROL
    delegate SafetyMcuFirmware.RxCam_PRE_COLLISION_2 <-> outer port LdSda/RxCam_PRE_COLLISION_2
    delegate SafetyMcuFirmware.RxCam_PCS_HUD <-> outer port LdSda/RxCam_PCS_HUD
    delegate SafetyMcuFirmware.RxCam_LKAS_HUD <-> outer port LdSda/RxCam_LKAS_HUD
  composition sw component type VehicleContext  # LD-SDA in the reference vehicle | The item in the reference vehicle CFG-001 (Corolla E210 · ZRE212 · US, Toyota Safety Sense 2.0) with the ECUs it exchanges CAN frames with.
    6 x component:
      LdSda: type=LdSda
      Ext_EPS: type=Ext_EPS
      Ext_PCM: type=Ext_PCM
      Ext_AbsVsc: type=Ext_AbsVsc
      Ext_Cluster: type=Ext_Cluster
      Ext_ForwardCamera: type=Ext_ForwardCamera
    connect Ext_AbsVsc.Tx_WHEEL_SPEEDS -> LdSda.Rx_WHEEL_SPEEDS
    connect Ext_AbsVsc.Tx_SPEED -> LdSda.Rx_SPEED
    connect LdSda.Tx_STEERING_LTA -> Ext_EPS.Rx_STEERING_LTA
    connect Ext_PCM.Tx_PCM_CRUISE -> LdSda.Rx_PCM_CRUISE
    connect Ext_PCM.Tx_PCM_CRUISE_2 -> LdSda.Rx_PCM_CRUISE_2
    connect Ext_AbsVsc.Tx_BRAKE_MODULE -> LdSda.Rx_BRAKE_MODULE
    connect Ext_EPS.Tx_STEER_TORQUE_SENSOR -> LdSda.Rx_STEER_TORQUE_SENSOR
    connect Ext_EPS.Tx_EPS_STATUS -> LdSda.Rx_EPS_STATUS
    connect LdSda.Tx_PRE_COLLISION -> Ext_AbsVsc.Rx_PRE_COLLISION
    connect LdSda.Tx_STEERING_LKA -> Ext_EPS.Rx_STEERING_LKA
    connect LdSda.Tx_ACC_CONTROL -> Ext_PCM.Rx_ACC_CONTROL
    connect LdSda.Tx_PRE_COLLISION_2 -> Ext_AbsVsc.Rx_PRE_COLLISION_2
    connect LdSda.Tx_PCS_HUD -> Ext_Cluster.Rx_PCS_HUD
    connect LdSda.Tx_LKAS_HUD -> Ext_Cluster.Rx_LKAS_HUD
    connect Ext_ForwardCamera.Tx_STEERING_LTA -> LdSda.RxCam_STEERING_LTA
    connect Ext_ForwardCamera.Tx_PRE_COLLISION -> LdSda.RxCam_PRE_COLLISION
    connect Ext_ForwardCamera.Tx_STEERING_LKA -> LdSda.RxCam_STEERING_LKA
    connect Ext_ForwardCamera.Tx_ACC_CONTROL -> LdSda.RxCam_ACC_CONTROL
    connect Ext_ForwardCamera.Tx_PRE_COLLISION_2 -> LdSda.RxCam_PRE_COLLISION_2
    connect Ext_ForwardCamera.Tx_PCS_HUD -> LdSda.RxCam_PCS_HUD
    connect Ext_ForwardCamera.Tx_LKAS_HUD -> LdSda.RxCam_LKAS_HUD
package /LionDriver/Communication
  i signal group WHEEL_SPEEDS_Group: i-signal=[WHEEL_SPEEDS_WHEEL_SPEED_FR_FAULT, WHEEL_SPEEDS_WHEEL_SPEED_FR, WHEEL_SPEEDS_WHEEL_SPEED_FL_FAULT, WHEEL_SPEEDS_WHEEL_SPEED_FL, WHEEL_SPEEDS_WHEEL_SPEED_RR_FAULT, WHEEL_SPEEDS_WHEEL_SPEED_RR, WHEEL_SPEEDS_WHEEL_SPEED_RL_FAULT, WHEEL_SPEEDS_WHEEL_SPEED_RL], system-signal-group=WHEEL_SPEEDS_Group
  i signal group SPEED_Group: i-signal=[SPEED_ENCODER, SPEED_SPEED, SPEED_CHECKSUM], system-signal-group=SPEED_Group
  i signal group STEERING_LTA_Group: i-signal=[STEERING_LTA_CHECKSUM, STEERING_LTA_SETME_X3, STEERING_LTA_PERCENTAGE, STEERING_LTA_TORQUE_WIND_DOWN, STEERING_LTA_ANGLE, STEERING_LTA_STEER_ANGLE_CMD, STEERING_LTA_STEER_REQUEST_2, STEERING_LTA_LKA_ACTIVE, STEERING_LTA_CLEAR_HOLD_STEERING_ALERT, STEERING_LTA_COUNTER, STEERING_LTA_STEER_REQUEST, STEERING_LTA_SETME_X1], system-signal-group=STEERING_LTA_Group
  i signal group PCM_CRUISE_Group: i-signal=[PCM_CRUISE_GAS_RELEASED, PCM_CRUISE_CRUISE_ACTIVE, PCM_CRUISE_ACC_BRAKING, PCM_CRUISE_ACCEL_NET, PCM_CRUISE_NEUTRAL_FORCE, PCM_CRUISE_CRUISE_STATE, PCM_CRUISE_CANCEL_REQ, PCM_CRUISE_CHECKSUM], system-signal-group=PCM_CRUISE_Group
  i signal group PCM_CRUISE_2_Group: i-signal=[PCM_CRUISE_2_BRAKE_PRESSED, PCM_CRUISE_2_PCM_FOLLOW_DISTANCE, PCM_CRUISE_2_LOW_SPEED_LOCKOUT, PCM_CRUISE_2_MAIN_ON, PCM_CRUISE_2_SET_SPEED, PCM_CRUISE_2_ACC_FAULTED, PCM_CRUISE_2_CHECKSUM], system-signal-group=PCM_CRUISE_2_Group
  i signal group BRAKE_MODULE_Group: i-signal=[BRAKE_MODULE_BRAKE_PRESSURE, BRAKE_MODULE_BRAKE_POSITION, BRAKE_MODULE_BRAKE_PRESSED], system-signal-group=BRAKE_MODULE_Group
  i signal group STEER_TORQUE_SENSOR_Group: i-signal=[STEER_TORQUE_SENSOR_STEER_TORQUE_EPS, STEER_TORQUE_SENSOR_STEER_TORQUE_DRIVER, STEER_TORQUE_SENSOR_STEER_ANGLE, STEER_TORQUE_SENSOR_STEER_ANGLE_INITIALIZING, STEER_TORQUE_SENSOR_STEER_OVERRIDE, STEER_TORQUE_SENSOR_CHECKSUM], system-signal-group=STEER_TORQUE_SENSOR_Group
  i signal group EPS_STATUS_Group: i-signal=[EPS_STATUS_IPAS_STATE, EPS_STATUS_LKA_STATE, EPS_STATUS_LTA_STATE, EPS_STATUS_TYPE, EPS_STATUS_CHECKSUM], system-signal-group=EPS_STATUS_Group
  i signal group PRE_COLLISION_Group: i-signal=[PRE_COLLISION_COUNTER, PRE_COLLISION_SET_ME_X00, PRE_COLLISION_FORCE, PRE_COLLISION_SET_ME_X002, PRE_COLLISION_BRAKE_STATUS, PRE_COLLISION_STATE, PRE_COLLISION_SET_ME_X003, PRE_COLLISION_PRECOLLISION_ACTIVE, PRE_COLLISION_CHECKSUM], system-signal-group=PRE_COLLISION_Group
  i signal group STEERING_LKA_Group: i-signal=[STEERING_LKA_LKA_STATE, STEERING_LKA_STEER_REQUEST, STEERING_LKA_COUNTER, STEERING_LKA_SET_ME_1, STEERING_LKA_STEER_TORQUE_CMD, STEERING_LKA_CHECKSUM], system-signal-group=STEERING_LKA_Group
  i signal group ACC_CONTROL_Group: i-signal=[ACC_CONTROL_ACCEL_CMD, ACC_CONTROL_ALLOW_LONG_PRESS, ACC_CONTROL_ACC_MALFUNCTION, ACC_CONTROL_RADAR_DIRTY, ACC_CONTROL_DISTANCE, ACC_CONTROL_MINI_CAR, ACC_CONTROL_ACC_TYPE, ACC_CONTROL_CANCEL_REQ, ACC_CONTROL_ACC_CUT_IN, ACC_CONTROL_LEAD_VEHICLE_STOPPED, ACC_CONTROL_PERMIT_BRAKING, ACC_CONTROL_RELEASE_STANDSTILL, ACC_CONTROL_ITS_CONNECT_LEAD, ACC_CONTROL_ACCEL_CMD_ALT, ACC_CONTROL_CHECKSUM], system-signal-group=ACC_CONTROL_Group
  i signal group PRE_COLLISION_2_Group: i-signal=[PRE_COLLISION_2_DSS1GDRV, PRE_COLLISION_2_PCSALM, PRE_COLLISION_2_IBTRGR, PRE_COLLISION_2_PBATRGR, PRE_COLLISION_2_PREFILL, PRE_COLLISION_2_AVSTRGR, PRE_COLLISION_2_CHECKSUM], system-signal-group=PRE_COLLISION_2_Group
  i signal group PCS_HUD_Group: i-signal=[PCS_HUD_PCS_INDICATOR, PCS_HUD_FCW, PCS_HUD_SET_ME_X20, PCS_HUD_PCS_DUST, PCS_HUD_PCS_TEMP, PCS_HUD_PCS_DUST2, PCS_HUD_PCS_TEMP2, PCS_HUD_SET_ME_X10, PCS_HUD_PCS_OFF, PCS_HUD_FRD_ADJ, PCS_HUD_PCS_SENSITIVITY], system-signal-group=PCS_HUD_Group
  i signal group LKAS_HUD_Group: i-signal=[LKAS_HUD_BARRIERS, LKAS_HUD_RIGHT_LINE, LKAS_HUD_LEFT_LINE, LKAS_HUD_LKAS_STATUS, LKAS_HUD_LDA_ALERT, LKAS_HUD_LDW_EXIST, LKAS_HUD_TWO_BEEPS, LKAS_HUD_ADJUSTING_CAMERA, LKAS_HUD_LDA_UNAVAILABLE_QUIET, LKAS_HUD_LDA_MALFUNCTION, LKAS_HUD_LDA_UNAVAILABLE, LKAS_HUD_LDA_SENSITIVITY, LKAS_HUD_LDA_SA_TOGGLE, LKAS_HUD_LDA_MESSAGES, LKAS_HUD_LDA_ON_MESSAGE, LKAS_HUD_REPEATED_BEEPS, LKAS_HUD_LANE_SWAY_TOGGLE, LKAS_HUD_LANE_SWAY_SENSITIVITY, LKAS_HUD_TAKE_CONTROL, LKAS_HUD_LDA_FRONT_CAMERA_BLOCKED, LKAS_HUD_LANE_SWAY_BUZZER, LKAS_HUD_LANE_SWAY_FLD, LKAS_HUD_LANE_SWAY_WARNING, LKAS_HUD_SET_ME_X01, LKAS_HUD_SET_ME_X02], system-signal-group=LKAS_HUD_Group
  end to end protection set ReferenceCar_ChecksumCounter  # The checksum and counter protection of the reference car's frames, written in AUTOSAR's end-to-end vocabulary. None of it is an AUTOSAR E2E profile (category LIONDRIVER_TOYOTA_CHECKSUM8 is not a standard category). WP-S-05 §12.3: on the reference car end-to-end protection in the usual sense (checksum, counter and timeout together) exists only on the camera's PCS frames. For comparison, WP-S-05 §12.5: Volkswagen MQB uses CRC-8H2F with a data ID per counter value, the AUTOSAR E2E profile 2 pattern; no such vehicle is configured
    10 x end to end protection:
      SPEED: end-to-end-profile={category=LIONDRIVER_TOYOTA_CHECKSUM8, data-ids=180, data-length=64, crc-offset=56}, end-to-end-protection-i-signal-i-pdu{data-offset=0, i-signal-group=SPEED_Group, i-signal-i-pdu=SPEED_IPdu}  # Not an AUTOSAR E2E profile. Toyota 8-bit additive checksum: the low byte of the sum of the identifier bytes, the length and the data bytes (toyota.h toyota_compute_checksum), in the last byte; the identifier enters the sum like an AUTOSAR data ID. No counter. Checked by: not checked by the item.
      STEERING_LTA: end-to-end-profile={category=LIONDRIVER_TOYOTA_CHECKSUM8, data-ids=401, data-length=64, crc-offset=56, counter-offset=1}, end-to-end-protection-i-signal-i-pdu{data-offset=0, i-signal-group=STEERING_LTA_Group, i-signal-i-pdu=STEERING_LTA_IPdu}  # Not an AUTOSAR E2E profile. Toyota 8-bit additive checksum: the low byte of the sum of the identifier bytes, the length and the data bytes (toyota.h toyota_compute_checksum), in the last byte; the identifier enters the sum like an AUTOSAR data ID. 6-bit counter COUNTER. Checked by: written by openpilot on the SoC; not checked by the panda (WP-S-05 §12.3 H2); the EPS, assumed (WP-S-05 OI-9).
      PCM_CRUISE: end-to-end-profile={category=LIONDRIVER_TOYOTA_CHECKSUM8, data-ids=466, data-length=64, crc-offset=56}, end-to-end-protection-i-signal-i-pdu{data-offset=0, i-signal-group=PCM_CRUISE_Group, i-signal-i-pdu=PCM_CRUISE_IPdu}  # Not an AUTOSAR E2E profile. Toyota 8-bit additive checksum: the low byte of the sum of the identifier bytes, the length and the data bytes (toyota.h toyota_compute_checksum), in the last byte; the identifier enters the sum like an AUTOSAR data ID. No counter. Checked by: panda RX check. Reception supervised by the panda: absence for 5 periods of 33 Hz revokes authority (TSR-401).
      PCM_CRUISE_2: end-to-end-profile={category=LIONDRIVER_TOYOTA_CHECKSUM8, data-ids=467, data-length=64, crc-offset=56}, end-to-end-protection-i-signal-i-pdu{data-offset=0, i-signal-group=PCM_CRUISE_2_Group, i-signal-i-pdu=PCM_CRUISE_2_IPdu}  # Not an AUTOSAR E2E profile. Toyota 8-bit additive checksum: the low byte of the sum of the identifier bytes, the length and the data bytes (toyota.h toyota_compute_checksum), in the last byte; the identifier enters the sum like an AUTOSAR data ID. No counter. Checked by: panda RX check. Reception supervised by the panda: absence for 5 periods of 33 Hz revokes authority (TSR-401).
      STEER_TORQUE_SENSOR: end-to-end-profile={category=LIONDRIVER_TOYOTA_CHECKSUM8, data-ids=608, data-length=64, crc-offset=56}, end-to-end-protection-i-signal-i-pdu{data-offset=0, i-signal-group=STEER_TORQUE_SENSOR_Group, i-signal-i-pdu=STEER_TORQUE_SENSOR_IPdu}  # Not an AUTOSAR E2E profile. Toyota 8-bit additive checksum: the low byte of the sum of the identifier bytes, the length and the data bytes (toyota.h toyota_compute_checksum), in the last byte; the identifier enters the sum like an AUTOSAR data ID. No counter. Checked by: panda RX check. Reception supervised by the panda: absence for 5 periods of 50 Hz revokes authority (TSR-401).
      EPS_STATUS: end-to-end-profile={category=LIONDRIVER_TOYOTA_CHECKSUM8, data-ids=610, data-length=64, crc-offset=56}, end-to-end-protection-i-signal-i-pdu{data-offset=0, i-signal-group=EPS_STATUS_Group, i-signal-i-pdu=EPS_STATUS_IPdu}  # Not an AUTOSAR E2E profile. Toyota 8-bit additive checksum: the low byte of the sum of the identifier bytes, the length and the data bytes (toyota.h toyota_compute_checksum), in the last byte; the identifier enters the sum like an AUTOSAR data ID. No counter. Checked by: panda RX check. Reception supervised by the panda: absence for 5 periods of 25 Hz revokes authority (TSR-401).
      PRE_COLLISION: end-to-end-profile={category=LIONDRIVER_TOYOTA_CHECKSUM8, data-ids=643, data-length=56, crc-offset=48, counter-offset=0}, end-to-end-protection-i-signal-i-pdu{data-offset=0, i-signal-group=PRE_COLLISION_Group, i-signal-i-pdu=PRE_COLLISION_IPdu}  # Not an AUTOSAR E2E profile. Toyota 8-bit additive checksum: the low byte of the sum of the identifier bytes, the length and the data bytes (toyota.h toyota_compute_checksum), in the last byte; the identifier enters the sum like an AUTOSAR data ID. 8-bit counter _COUNTER. Checked by: forwarded byte for byte, checked by the receiving ECU (WP-S-05 §12.3 H4).
      STEERING_LKA: end-to-end-profile={category=LIONDRIVER_TOYOTA_CHECKSUM8, data-ids=740, data-length=40, crc-offset=32, counter-offset=1}, end-to-end-protection-i-signal-i-pdu{data-offset=0, i-signal-group=STEERING_LKA_Group, i-signal-i-pdu=STEERING_LKA_IPdu}  # Not an AUTOSAR E2E profile. Toyota 8-bit additive checksum: the low byte of the sum of the identifier bytes, the length and the data bytes (toyota.h toyota_compute_checksum), in the last byte; the identifier enters the sum like an AUTOSAR data ID. 6-bit counter COUNTER. Checked by: written by openpilot on the SoC; not checked by the panda (WP-S-05 §12.3 H2); the EPS, assumed (WP-S-05 OI-9).
      ACC_CONTROL: end-to-end-profile={category=LIONDRIVER_TOYOTA_CHECKSUM8, data-ids=835, data-length=64, crc-offset=56}, end-to-end-protection-i-signal-i-pdu{data-offset=0, i-signal-group=ACC_CONTROL_Group, i-signal-i-pdu=ACC_CONTROL_IPdu}  # Not an AUTOSAR E2E profile. Toyota 8-bit additive checksum: the low byte of the sum of the identifier bytes, the length and the data bytes (toyota.h toyota_compute_checksum), in the last byte; the identifier enters the sum like an AUTOSAR data ID. No counter. Checked by: written by openpilot on the SoC; not checked by the panda (WP-S-05 §12.3 H2).
      PRE_COLLISION_2: end-to-end-profile={category=LIONDRIVER_TOYOTA_CHECKSUM8, data-ids=836, data-length=64, crc-offset=56}, end-to-end-protection-i-signal-i-pdu{data-offset=0, i-signal-group=PRE_COLLISION_2_Group, i-signal-i-pdu=PRE_COLLISION_2_IPdu}  # Not an AUTOSAR E2E profile. Toyota 8-bit additive checksum: the low byte of the sum of the identifier bytes, the length and the data bytes (toyota.h toyota_compute_checksum), in the last byte; the identifier enters the sum like an AUTOSAR data ID. No counter. Checked by: forwarded byte for byte, checked by the receiving ECU (WP-S-05 §12.3 H4).
  can cluster VehicleCan_Bus0: baudrate=500000, protocol-name=CAN, protocol-version=ISO 11898-1 classical CAN  # Vehicle side of the harness (panda bus 0, FDCAN1 or FDCAN3 when flipped): actuation TX and the envelope's RX set (WP-S-05 §5). 500 kbit/s (WP-S-05 §3, §12.1)
    can physical channel Channel: comm-connectors=[Ext_AbsVsc/Bus0, Ext_Cluster/Bus0, Ext_EPS/Bus0, Ext_PCM/Bus0, LD_SafetyMcu/Bus0]
      frame WHEEL_SPEEDS: id 0xAA, from Ext_AbsVsc, to LD_SafetyMcu, frame-length=8, can-addressing-mode=STANDARD, can-fd-frame-support=false  # 0x0aa WHEEL_SPEEDS
        pdu WHEEL_SPEEDS_IPdu: length=8, transmission-mode-true-timing=cyclic-timing=time-period=0.012048, unused-bit-pattern=0
          signal WHEEL_SPEEDS_WHEEL_SPEED_FR_FAULT: start 7, 1 bit, big-endian, base-type=boolean, transfer-property=PENDING, to LD_SafetyMcu(timeout 0.060241 s)
          signal WHEEL_SPEEDS_WHEEL_SPEED_FR: start 8, 15 bit, big-endian, base-type=uint16, compu-method=WHEEL_SPEEDS_WHEEL_SPEED_FR, transfer-property=PENDING, to LD_SafetyMcu(timeout 0.060241 s)
          signal WHEEL_SPEEDS_WHEEL_SPEED_FL_FAULT: start 23, 1 bit, big-endian, base-type=boolean, transfer-property=PENDING, to LD_SafetyMcu(timeout 0.060241 s)
          signal WHEEL_SPEEDS_WHEEL_SPEED_FL: start 24, 15 bit, big-endian, base-type=uint16, compu-method=WHEEL_SPEEDS_WHEEL_SPEED_FL, transfer-property=PENDING, to LD_SafetyMcu(timeout 0.060241 s)
          signal WHEEL_SPEEDS_WHEEL_SPEED_RR_FAULT: start 39, 1 bit, big-endian, base-type=boolean, transfer-property=PENDING, to LD_SafetyMcu(timeout 0.060241 s)
          signal WHEEL_SPEEDS_WHEEL_SPEED_RR: start 40, 15 bit, big-endian, base-type=uint16, compu-method=WHEEL_SPEEDS_WHEEL_SPEED_RR, transfer-property=PENDING, to LD_SafetyMcu(timeout 0.060241 s)
          signal WHEEL_SPEEDS_WHEEL_SPEED_RL_FAULT: start 55, 1 bit, big-endian, base-type=boolean, transfer-property=PENDING, to LD_SafetyMcu(timeout 0.060241 s)
          signal WHEEL_SPEEDS_WHEEL_SPEED_RL: start 56, 15 bit, big-endian, base-type=uint16, compu-method=WHEEL_SPEEDS_WHEEL_SPEED_RL, transfer-property=PENDING, to LD_SafetyMcu(timeout 0.060241 s)
          mapping Group: i-signal-group=WHEEL_SPEEDS_Group
      frame SPEED: id 0xB4, from Ext_AbsVsc, to LD_SafetyMcu, frame-length=8, can-addressing-mode=STANDARD, can-fd-frame-support=false  # 0x0b4 SPEED
        pdu SPEED_IPdu: length=8, unused-bit-pattern=0
          signal SPEED_ENCODER: start 32, 8 bit, big-endian, base-type=uint8, transfer-property=PENDING, to LD_SafetyMcu
          signal SPEED_SPEED: start 48, 16 bit, big-endian, base-type=uint16, compu-method=SPEED_SPEED, transfer-property=PENDING, to LD_SafetyMcu
          signal SPEED_CHECKSUM: start 56, 8 bit, big-endian, base-type=uint8, transfer-property=PENDING, to LD_SafetyMcu
          mapping Group: i-signal-group=SPEED_Group
      frame STEERING_LTA: id 0x191, from LD_SafetyMcu, to Ext_EPS, frame-length=8, can-addressing-mode=STANDARD, can-fd-frame-support=false  # 0x191 STEERING_LTA
        pdu STEERING_LTA_IPdu: length=8, transmission-mode-true-timing=cyclic-timing=time-period=0.02, unused-bit-pattern=0
          signal STEERING_LTA_CHECKSUM: start 56, 8 bit, big-endian, base-type=uint8, transfer-property=PENDING, to Ext_EPS LD_SafetyMcu
          signal STEERING_LTA_SETME_X3: start 28, 2 bit, big-endian, base-type=uint8, transfer-property=PENDING, to Ext_EPS LD_SafetyMcu
          signal STEERING_LTA_PERCENTAGE: start 32, 8 bit, big-endian, base-type=uint8, transfer-property=PENDING, to Ext_EPS LD_SafetyMcu
          signal STEERING_LTA_TORQUE_WIND_DOWN: start 40, 8 bit, big-endian, base-type=uint8, transfer-property=PENDING, to Ext_EPS LD_SafetyMcu
          signal STEERING_LTA_ANGLE: start 48, 8 bit, big-endian, base-type=sint8, compu-method=STEERING_LTA_ANGLE, transfer-property=PENDING, to Ext_EPS LD_SafetyMcu
          signal STEERING_LTA_STEER_ANGLE_CMD: start 16, 16 bit, big-endian, base-type=sint16, compu-method=STEERING_LTA_STEER_ANGLE_CMD, transfer-property=PENDING, to Ext_EPS LD_SafetyMcu
          signal STEERING_LTA_STEER_REQUEST_2: start 25, 1 bit, big-endian, base-type=boolean, transfer-property=PENDING, to Ext_EPS LD_SafetyMcu
          signal STEERING_LTA_LKA_ACTIVE: start 26, 1 bit, big-endian, base-type=boolean, transfer-property=PENDING, to Ext_EPS LD_SafetyMcu
          signal STEERING_LTA_CLEAR_HOLD_STEERING_ALERT: start 30, 1 bit, big-endian, base-type=boolean, transfer-property=PENDING, to Ext_EPS LD_SafetyMcu
          signal STEERING_LTA_COUNTER: start 1, 6 bit, big-endian, base-type=uint8, transfer-property=PENDING, to Ext_EPS LD_SafetyMcu
          signal STEERING_LTA_STEER_REQUEST: start 0, 1 bit, big-endian, base-type=boolean, transfer-property=PENDING, to Ext_EPS LD_SafetyMcu
          signal STEERING_LTA_SETME_X1: start 7, 1 bit, big-endian, base-type=boolean, transfer-property=PENDING, to Ext_EPS LD_SafetyMcu
          mapping Group: i-signal-group=STEERING_LTA_Group
      frame PCM_CRUISE: id 0x1D2, from Ext_PCM, to LD_SafetyMcu, frame-length=8, can-addressing-mode=STANDARD, can-fd-frame-support=false  # 0x1d2 PCM_CRUISE
        pdu PCM_CRUISE_IPdu: length=8, transmission-mode-true-timing=cyclic-timing=time-period=0.030303, unused-bit-pattern=0
          signal PCM_CRUISE_GAS_RELEASED: start 4, 1 bit, big-endian, base-type=boolean, transfer-property=PENDING, to LD_SafetyMcu(timeout 0.151515 s)
          signal PCM_CRUISE_CRUISE_ACTIVE: start 5, 1 bit, big-endian, base-type=boolean, transfer-property=PENDING, to LD_SafetyMcu(timeout 0.151515 s)
          signal PCM_CRUISE_ACC_BRAKING: start 12, 1 bit, big-endian, base-type=boolean, transfer-property=PENDING, to LD_SafetyMcu(timeout 0.151515 s)
          signal PCM_CRUISE_ACCEL_NET: start 24, 16 bit, big-endian, base-type=sint16, compu-method=PCM_CRUISE_ACCEL_NET, transfer-property=PENDING, to LD_SafetyMcu(timeout 0.151515 s)
          signal PCM_CRUISE_NEUTRAL_FORCE: start 40, 16 bit, big-endian, base-type=sint16, compu-method=PCM_CRUISE_NEUTRAL_FORCE, transfer-property=PENDING, to LD_SafetyMcu(timeout 0.151515 s)
          signal PCM_CRUISE_CRUISE_STATE: start 52, 4 bit, big-endian, base-type=uint8, transfer-property=PENDING, to LD_SafetyMcu(timeout 0.151515 s)
          signal PCM_CRUISE_CANCEL_REQ: start 49, 1 bit, little-endian, base-type=boolean, transfer-property=PENDING, to LD_SafetyMcu(timeout 0.151515 s)
          signal PCM_CRUISE_CHECKSUM: start 56, 8 bit, big-endian, base-type=uint8, transfer-property=PENDING, to LD_SafetyMcu(timeout 0.151515 s)
          mapping Group: i-signal-group=PCM_CRUISE_Group
      frame PCM_CRUISE_2: id 0x1D3, from Ext_PCM, to LD_SafetyMcu, frame-length=8, can-addressing-mode=STANDARD, can-fd-frame-support=false  # 0x1d3 PCM_CRUISE_2
        pdu PCM_CRUISE_2_IPdu: length=8, transmission-mode-true-timing=cyclic-timing=time-period=0.030303, unused-bit-pattern=0
          signal PCM_CRUISE_2_BRAKE_PRESSED: start 3, 1 bit, big-endian, base-type=boolean, transfer-property=PENDING, to LD_SafetyMcu(timeout 0.151515 s)
          signal PCM_CRUISE_2_PCM_FOLLOW_DISTANCE: start 11, 2 bit, big-endian, base-type=uint8, transfer-property=PENDING, to LD_SafetyMcu(timeout 0.151515 s)
          signal PCM_CRUISE_2_LOW_SPEED_LOCKOUT: start 13, 2 bit, big-endian, base-type=uint8, transfer-property=PENDING, to LD_SafetyMcu(timeout 0.151515 s)
          signal PCM_CRUISE_2_MAIN_ON: start 15, 1 bit, big-endian, base-type=boolean, transfer-property=PENDING, to LD_SafetyMcu(timeout 0.151515 s)
          signal PCM_CRUISE_2_SET_SPEED: start 16, 8 bit, big-endian, base-type=uint8, compu-method=PCM_CRUISE_2_SET_SPEED, transfer-property=PENDING, to LD_SafetyMcu(timeout 0.151515 s)
          signal PCM_CRUISE_2_ACC_FAULTED: start 47, 1 bit, big-endian, base-type=boolean, transfer-property=PENDING, to LD_SafetyMcu(timeout 0.151515 s)
          signal PCM_CRUISE_2_CHECKSUM: start 56, 8 bit, big-endian, base-type=uint8, transfer-property=PENDING, to LD_SafetyMcu(timeout 0.151515 s)
          mapping Group: i-signal-group=PCM_CRUISE_2_Group
      frame BRAKE_MODULE: id 0x226, from Ext_AbsVsc, to LD_SafetyMcu, frame-length=8, can-addressing-mode=STANDARD, can-fd-frame-support=false  # 0x226 BRAKE_MODULE
        pdu BRAKE_MODULE_IPdu: length=8, transmission-mode-true-timing=cyclic-timing=time-period=0.025, unused-bit-pattern=0
          signal BRAKE_MODULE_BRAKE_PRESSURE: start 8, 9 bit, big-endian, base-type=uint16, transfer-property=PENDING, to LD_SafetyMcu(timeout 0.125 s)
          signal BRAKE_MODULE_BRAKE_POSITION: start 24, 9 bit, big-endian, base-type=uint16, transfer-property=PENDING, to LD_SafetyMcu(timeout 0.125 s)
          signal BRAKE_MODULE_BRAKE_PRESSED: start 37, 1 bit, big-endian, base-type=boolean, transfer-property=PENDING, to LD_SafetyMcu(timeout 0.125 s)
          mapping Group: i-signal-group=BRAKE_MODULE_Group
      frame STEER_TORQUE_SENSOR: id 0x260, from Ext_EPS, to LD_SafetyMcu, frame-length=8, can-addressing-mode=STANDARD, can-fd-frame-support=false  # 0x260 STEER_TORQUE_SENSOR
        pdu STEER_TORQUE_SENSOR_IPdu: length=8, transmission-mode-true-timing=cyclic-timing=time-period=0.02, unused-bit-pattern=0
          signal STEER_TORQUE_SENSOR_STEER_TORQUE_EPS: start 48, 16 bit, big-endian, base-type=sint16, transfer-property=PENDING, to LD_SafetyMcu(timeout 0.1 s)
          signal STEER_TORQUE_SENSOR_STEER_TORQUE_DRIVER: start 16, 16 bit, big-endian, base-type=sint16, transfer-property=PENDING, to LD_SafetyMcu(timeout 0.1 s)
          signal STEER_TORQUE_SENSOR_STEER_ANGLE: start 32, 16 bit, big-endian, base-type=sint16, compu-method=STEER_TORQUE_SENSOR_STEER_ANGLE, transfer-property=PENDING, to LD_SafetyMcu(timeout 0.1 s)
          signal STEER_TORQUE_SENSOR_STEER_ANGLE_INITIALIZING: start 3, 1 bit, big-endian, base-type=boolean, transfer-property=PENDING, to LD_SafetyMcu(timeout 0.1 s)
          signal STEER_TORQUE_SENSOR_STEER_OVERRIDE: start 0, 1 bit, big-endian, base-type=boolean, transfer-property=PENDING, to LD_SafetyMcu(timeout 0.1 s)
          signal STEER_TORQUE_SENSOR_CHECKSUM: start 56, 8 bit, big-endian, base-type=uint8, transfer-property=PENDING, to LD_SafetyMcu(timeout 0.1 s)
          mapping Group: i-signal-group=STEER_TORQUE_SENSOR_Group
      frame EPS_STATUS: id 0x262, from Ext_EPS, to LD_SafetyMcu, frame-length=8, can-addressing-mode=STANDARD, can-fd-frame-support=false  # 0x262 EPS_STATUS
        pdu EPS_STATUS_IPdu: length=8, transmission-mode-true-timing=cyclic-timing=time-period=0.04, unused-bit-pattern=0
          signal EPS_STATUS_IPAS_STATE: start 0, 4 bit, big-endian, base-type=uint8, transfer-property=PENDING, to LD_SafetyMcu(timeout 0.2 s)
          signal EPS_STATUS_LKA_STATE: start 25, 7 bit, big-endian, base-type=uint8, transfer-property=PENDING, to LD_SafetyMcu(timeout 0.2 s)
          signal EPS_STATUS_LTA_STATE: start 11, 5 bit, big-endian, base-type=uint8, transfer-property=PENDING, to LD_SafetyMcu(timeout 0.2 s)
          signal EPS_STATUS_TYPE: start 24, 1 bit, big-endian, base-type=boolean, transfer-property=PENDING, to LD_SafetyMcu(timeout 0.2 s)
          signal EPS_STATUS_CHECKSUM: start 56, 8 bit, big-endian, base-type=uint8, transfer-property=PENDING, to LD_SafetyMcu(timeout 0.2 s)
          mapping Group: i-signal-group=EPS_STATUS_Group
      frame PRE_COLLISION: id 0x283, from LD_SafetyMcu, to Ext_AbsVsc, frame-length=7, can-addressing-mode=STANDARD, can-fd-frame-support=false  # 0x283 PRE_COLLISION
        pdu PRE_COLLISION_IPdu: length=7, unused-bit-pattern=0
          signal PRE_COLLISION_COUNTER: start 0, 8 bit, big-endian, base-type=uint8, transfer-property=PENDING, to Ext_AbsVsc LD_SafetyMcu
          signal PRE_COLLISION_SET_ME_X00: start 8, 8 bit, big-endian, base-type=uint8, transfer-property=PENDING, to Ext_AbsVsc LD_SafetyMcu
          signal PRE_COLLISION_FORCE: start 24, 16 bit, big-endian, base-type=sint16, compu-method=PRE_COLLISION_FORCE, transfer-property=PENDING, to Ext_AbsVsc LD_SafetyMcu
          signal PRE_COLLISION_SET_ME_X002: start 42, 8 bit, big-endian, base-type=uint8, transfer-property=PENDING, to Ext_AbsVsc LD_SafetyMcu
          signal PRE_COLLISION_BRAKE_STATUS: start 37, 3 bit, big-endian, base-type=uint8, transfer-property=PENDING, to Ext_AbsVsc LD_SafetyMcu
          signal PRE_COLLISION_STATE: start 34, 3 bit, big-endian, base-type=uint8, transfer-property=PENDING, to Ext_AbsVsc LD_SafetyMcu
          signal PRE_COLLISION_SET_ME_X003: start 40, 1 bit, big-endian, base-type=boolean, transfer-property=PENDING, to Ext_AbsVsc LD_SafetyMcu
          signal PRE_COLLISION_PRECOLLISION_ACTIVE: start 41, 1 bit, big-endian, base-type=boolean, transfer-property=PENDING, to Ext_AbsVsc LD_SafetyMcu
          signal PRE_COLLISION_CHECKSUM: start 48, 8 bit, big-endian, base-type=uint8, transfer-property=PENDING, to Ext_AbsVsc LD_SafetyMcu
          mapping Group: i-signal-group=PRE_COLLISION_Group
      frame STEERING_LKA: id 0x2E4, from LD_SafetyMcu, to Ext_EPS, frame-length=5, can-addressing-mode=STANDARD, can-fd-frame-support=false  # 0x2e4 STEERING_LKA
        pdu STEERING_LKA_IPdu: length=5, transmission-mode-true-timing=cyclic-timing=time-period=0.01, unused-bit-pattern=0
          signal STEERING_LKA_LKA_STATE: start 24, 8 bit, big-endian, base-type=uint8, transfer-property=PENDING, to Ext_EPS LD_SafetyMcu
          signal STEERING_LKA_STEER_REQUEST: start 0, 1 bit, big-endian, base-type=boolean, transfer-property=PENDING, to Ext_EPS LD_SafetyMcu
          signal STEERING_LKA_COUNTER: start 1, 6 bit, big-endian, base-type=uint8, transfer-property=PENDING, to Ext_EPS LD_SafetyMcu
          signal STEERING_LKA_SET_ME_1: start 7, 1 bit, big-endian, base-type=boolean, transfer-property=PENDING, to Ext_EPS LD_SafetyMcu
          signal STEERING_LKA_STEER_TORQUE_CMD: start 16, 16 bit, big-endian, base-type=sint16, transfer-property=PENDING, to Ext_EPS LD_SafetyMcu
          signal STEERING_LKA_CHECKSUM: start 32, 8 bit, big-endian, base-type=uint8, transfer-property=PENDING, to Ext_EPS LD_SafetyMcu
          mapping Group: i-signal-group=STEERING_LKA_Group
      frame ACC_CONTROL: id 0x343, from LD_SafetyMcu, to Ext_PCM, frame-length=8, can-addressing-mode=STANDARD, can-fd-frame-support=false  # 0x343 ACC_CONTROL
        pdu ACC_CONTROL_IPdu: length=8, transmission-mode-true-timing=cyclic-timing=time-period=0.030303, unused-bit-pattern=0
          signal ACC_CONTROL_ACCEL_CMD: start 8, 16 bit, big-endian, base-type=sint16, compu-method=ACC_CONTROL_ACCEL_CMD, transfer-property=PENDING, to Ext_PCM LD_SafetyMcu
          signal ACC_CONTROL_ALLOW_LONG_PRESS: start 16, 2 bit, big-endian, base-type=uint8, transfer-property=PENDING, to Ext_PCM LD_SafetyMcu
          signal ACC_CONTROL_ACC_MALFUNCTION: start 18, 1 bit, big-endian, base-type=boolean, transfer-property=PENDING, to Ext_PCM LD_SafetyMcu
          signal ACC_CONTROL_RADAR_DIRTY: start 19, 1 bit, big-endian, base-type=boolean, transfer-property=PENDING, to Ext_PCM LD_SafetyMcu
          signal ACC_CONTROL_DISTANCE: start 20, 1 bit, big-endian, base-type=boolean, transfer-property=PENDING, to Ext_PCM LD_SafetyMcu
          signal ACC_CONTROL_MINI_CAR: start 21, 1 bit, big-endian, base-type=boolean, transfer-property=PENDING, to Ext_PCM LD_SafetyMcu
          signal ACC_CONTROL_ACC_TYPE: start 22, 2 bit, big-endian, base-type=uint8, transfer-property=PENDING, to Ext_PCM LD_SafetyMcu
          signal ACC_CONTROL_CANCEL_REQ: start 24, 1 bit, big-endian, base-type=boolean, transfer-property=PENDING, to Ext_PCM LD_SafetyMcu
          signal ACC_CONTROL_ACC_CUT_IN: start 25, 1 bit, big-endian, base-type=boolean, transfer-property=PENDING, to Ext_PCM LD_SafetyMcu
          signal ACC_CONTROL_LEAD_VEHICLE_STOPPED: start 29, 1 bit, big-endian, base-type=boolean, transfer-property=PENDING, to Ext_PCM LD_SafetyMcu
          signal ACC_CONTROL_PERMIT_BRAKING: start 30, 1 bit, big-endian, base-type=boolean, transfer-property=PENDING, to Ext_PCM LD_SafetyMcu
          signal ACC_CONTROL_RELEASE_STANDSTILL: start 31, 1 bit, big-endian, base-type=boolean, transfer-property=PENDING, to Ext_PCM LD_SafetyMcu
          signal ACC_CONTROL_ITS_CONNECT_LEAD: start 32, 8 bit, big-endian, base-type=uint8, transfer-property=PENDING, to Ext_PCM LD_SafetyMcu
          signal ACC_CONTROL_ACCEL_CMD_ALT: start 40, 8 bit, big-endian, base-type=sint8, compu-method=ACC_CONTROL_ACCEL_CMD_ALT, transfer-property=PENDING, to Ext_PCM LD_SafetyMcu
          signal ACC_CONTROL_CHECKSUM: start 56, 8 bit, big-endian, base-type=uint8, transfer-property=PENDING, to Ext_PCM LD_SafetyMcu
          mapping Group: i-signal-group=ACC_CONTROL_Group
      frame PRE_COLLISION_2: id 0x344, from LD_SafetyMcu, to Ext_AbsVsc, frame-length=8, can-addressing-mode=STANDARD, can-fd-frame-support=false  # 0x344 PRE_COLLISION_2
        pdu PRE_COLLISION_2_IPdu: length=8, unused-bit-pattern=0
          signal PRE_COLLISION_2_DSS1GDRV: start 14, 10 bit, big-endian, base-type=sint16, compu-method=PRE_COLLISION_2_DSS1GDRV, transfer-property=PENDING, to Ext_AbsVsc LD_SafetyMcu
          signal PRE_COLLISION_2_PCSALM: start 17, 1 bit, big-endian, base-type=boolean, transfer-property=PENDING, to Ext_AbsVsc LD_SafetyMcu
          signal PRE_COLLISION_2_IBTRGR: start 27, 1 bit, big-endian, base-type=boolean, transfer-property=PENDING, to Ext_AbsVsc LD_SafetyMcu
          signal PRE_COLLISION_2_PBATRGR: start 29, 2 bit, big-endian, base-type=uint8, transfer-property=PENDING, to Ext_AbsVsc LD_SafetyMcu
          signal PRE_COLLISION_2_PREFILL: start 33, 1 bit, big-endian, base-type=boolean, transfer-property=PENDING, to Ext_AbsVsc LD_SafetyMcu
          signal PRE_COLLISION_2_AVSTRGR: start 36, 1 bit, big-endian, base-type=boolean, transfer-property=PENDING, to Ext_AbsVsc LD_SafetyMcu
          signal PRE_COLLISION_2_CHECKSUM: start 56, 8 bit, big-endian, base-type=uint8, transfer-property=PENDING, to Ext_AbsVsc LD_SafetyMcu
          mapping Group: i-signal-group=PRE_COLLISION_2_Group
      frame PCS_HUD: id 0x411, from LD_SafetyMcu, to Ext_Cluster, frame-length=8, can-addressing-mode=STANDARD, can-fd-frame-support=false  # 0x411 PCS_HUD
        pdu PCS_HUD_IPdu: length=8, unused-bit-pattern=0
          signal PCS_HUD_PCS_INDICATOR: start 6, 2 bit, big-endian, base-type=uint8, transfer-property=PENDING, to Ext_Cluster LD_SafetyMcu
          signal PCS_HUD_FCW: start 4, 1 bit, big-endian, base-type=boolean, transfer-property=PENDING, to Ext_Cluster LD_SafetyMcu
          signal PCS_HUD_SET_ME_X20: start 8, 8 bit, big-endian, base-type=uint8, transfer-property=PENDING, to Ext_Cluster LD_SafetyMcu
          signal PCS_HUD_PCS_DUST: start 34, 1 bit, big-endian, base-type=boolean, transfer-property=PENDING, to Ext_Cluster LD_SafetyMcu
          signal PCS_HUD_PCS_TEMP: start 35, 1 bit, big-endian, base-type=boolean, transfer-property=PENDING, to Ext_Cluster LD_SafetyMcu
          signal PCS_HUD_PCS_DUST2: start 41, 1 bit, big-endian, base-type=boolean, transfer-property=PENDING, to Ext_Cluster LD_SafetyMcu
          signal PCS_HUD_PCS_TEMP2: start 42, 1 bit, big-endian, base-type=boolean, transfer-property=PENDING, to Ext_Cluster LD_SafetyMcu
          signal PCS_HUD_SET_ME_X10: start 32, 8 bit, big-endian, base-type=uint8, transfer-property=PENDING, to Ext_Cluster LD_SafetyMcu
          signal PCS_HUD_PCS_OFF: start 40, 1 bit, big-endian, base-type=boolean, transfer-property=PENDING, to Ext_Cluster LD_SafetyMcu
          signal PCS_HUD_FRD_ADJ: start 51, 3 bit, big-endian, base-type=uint8, transfer-property=PENDING, to Ext_Cluster LD_SafetyMcu
          signal PCS_HUD_PCS_SENSITIVITY: start 48, 8 bit, big-endian, base-type=uint8, transfer-property=PENDING, to Ext_Cluster LD_SafetyMcu
          mapping Group: i-signal-group=PCS_HUD_Group
      frame LKAS_HUD: id 0x412, from LD_SafetyMcu, to Ext_Cluster, frame-length=8, can-addressing-mode=STANDARD, can-fd-frame-support=false  # 0x412 LKAS_HUD
        pdu LKAS_HUD_IPdu: length=8, transmission-mode-true-timing=cyclic-timing=time-period=0.2, unused-bit-pattern=0
          signal LKAS_HUD_BARRIERS: start 0, 2 bit, big-endian, base-type=uint8, transfer-property=PENDING, to Ext_Cluster LD_SafetyMcu
          signal LKAS_HUD_RIGHT_LINE: start 2, 2 bit, big-endian, base-type=uint8, transfer-property=PENDING, to Ext_Cluster LD_SafetyMcu
          signal LKAS_HUD_LEFT_LINE: start 4, 2 bit, big-endian, base-type=uint8, transfer-property=PENDING, to Ext_Cluster LD_SafetyMcu
          signal LKAS_HUD_LKAS_STATUS: start 6, 2 bit, big-endian, base-type=uint8, transfer-property=PENDING, to Ext_Cluster LD_SafetyMcu
          signal LKAS_HUD_LDA_ALERT: start 8, 2 bit, big-endian, base-type=uint8, transfer-property=PENDING, to Ext_Cluster LD_SafetyMcu
          signal LKAS_HUD_LDW_EXIST: start 10, 1 bit, big-endian, base-type=boolean, transfer-property=PENDING, to Ext_Cluster LD_SafetyMcu
          signal LKAS_HUD_TWO_BEEPS: start 12, 1 bit, big-endian, base-type=boolean, transfer-property=PENDING, to Ext_Cluster LD_SafetyMcu
          signal LKAS_HUD_ADJUSTING_CAMERA: start 13, 1 bit, big-endian, base-type=boolean, transfer-property=PENDING, to Ext_Cluster LD_SafetyMcu
          signal LKAS_HUD_LDA_UNAVAILABLE_QUIET: start 14, 1 bit, big-endian, base-type=boolean, transfer-property=PENDING, to Ext_Cluster LD_SafetyMcu
          signal LKAS_HUD_LDA_MALFUNCTION: start 15, 1 bit, big-endian, base-type=boolean, transfer-property=PENDING, to Ext_Cluster LD_SafetyMcu
          signal LKAS_HUD_LDA_UNAVAILABLE: start 16, 1 bit, big-endian, base-type=boolean, transfer-property=PENDING, to Ext_Cluster LD_SafetyMcu
          signal LKAS_HUD_LDA_SENSITIVITY: start 17, 2 bit, big-endian, base-type=uint8, transfer-property=PENDING, to Ext_Cluster LD_SafetyMcu
          signal LKAS_HUD_LDA_SA_TOGGLE: start 19, 2 bit, big-endian, base-type=uint8, transfer-property=PENDING, to Ext_Cluster LD_SafetyMcu
          signal LKAS_HUD_LDA_MESSAGES: start 21, 3 bit, big-endian, base-type=uint8, transfer-property=PENDING, to Ext_Cluster LD_SafetyMcu
          signal LKAS_HUD_LDA_ON_MESSAGE: start 30, 2 bit, big-endian, base-type=uint8, transfer-property=PENDING, to Ext_Cluster LD_SafetyMcu
          signal LKAS_HUD_REPEATED_BEEPS: start 32, 1 bit, big-endian, base-type=boolean, transfer-property=PENDING, to Ext_Cluster LD_SafetyMcu
          signal LKAS_HUD_LANE_SWAY_TOGGLE: start 43, 1 bit, big-endian, base-type=boolean, transfer-property=PENDING, to Ext_Cluster LD_SafetyMcu
          signal LKAS_HUD_LANE_SWAY_SENSITIVITY: start 44, 2 bit, big-endian, base-type=uint8, transfer-property=PENDING, to Ext_Cluster LD_SafetyMcu
          signal LKAS_HUD_TAKE_CONTROL: start 46, 1 bit, big-endian, base-type=boolean, transfer-property=PENDING, to Ext_Cluster LD_SafetyMcu
          signal LKAS_HUD_LDA_FRONT_CAMERA_BLOCKED: start 47, 1 bit, big-endian, base-type=boolean, transfer-property=PENDING, to Ext_Cluster LD_SafetyMcu
          signal LKAS_HUD_LANE_SWAY_BUZZER: start 49, 2 bit, big-endian, base-type=uint8, transfer-property=PENDING, to Ext_Cluster LD_SafetyMcu
          signal LKAS_HUD_LANE_SWAY_FLD: start 51, 3 bit, big-endian, base-type=uint8, transfer-property=PENDING, to Ext_Cluster LD_SafetyMcu
          signal LKAS_HUD_LANE_SWAY_WARNING: start 54, 2 bit, big-endian, base-type=uint8, transfer-property=PENDING, to Ext_Cluster LD_SafetyMcu
          signal LKAS_HUD_SET_ME_X01: start 42, 1 bit, big-endian, base-type=boolean, transfer-property=PENDING, to Ext_Cluster LD_SafetyMcu
          signal LKAS_HUD_SET_ME_X02: start 56, 8 bit, big-endian, base-type=uint8, transfer-property=PENDING, to Ext_Cluster LD_SafetyMcu
          mapping Group: i-signal-group=LKAS_HUD_Group
  can cluster CameraCan_Bus2: baudrate=500000, protocol-name=CAN, protocol-version=ISO 11898-1 classical CAN  # Camera side of the harness (panda bus 2): the forward camera's frames, forwarded to bus 0 except those the item replaces (WP-S-05 §5). 500 kbit/s (WP-S-05 §3, §12.1)
    can physical channel Channel: comm-connectors=[Ext_ForwardCamera/Bus2, LD_SafetyMcu/Bus2]
      frame STEERING_LTA: id 0x191, from Ext_ForwardCamera, to LD_SafetyMcu, frame-length=8, can-addressing-mode=STANDARD, can-fd-frame-support=false  # 0x191 STEERING_LTA
        carries pdu STEERING_LTA_IPdu: packing-byte-order=little-endian, start-position=0
      frame PRE_COLLISION: id 0x283, from Ext_ForwardCamera, to LD_SafetyMcu, frame-length=7, can-addressing-mode=STANDARD, can-fd-frame-support=false  # 0x283 PRE_COLLISION
        carries pdu PRE_COLLISION_IPdu: packing-byte-order=little-endian, start-position=0
      frame STEERING_LKA: id 0x2E4, from Ext_ForwardCamera, to LD_SafetyMcu, frame-length=5, can-addressing-mode=STANDARD, can-fd-frame-support=false  # 0x2e4 STEERING_LKA
        carries pdu STEERING_LKA_IPdu: packing-byte-order=little-endian, start-position=0
      frame ACC_CONTROL: id 0x343, from Ext_ForwardCamera, to LD_SafetyMcu, frame-length=8, can-addressing-mode=STANDARD, can-fd-frame-support=false  # 0x343 ACC_CONTROL
        carries pdu ACC_CONTROL_IPdu: packing-byte-order=little-endian, start-position=0
      frame PRE_COLLISION_2: id 0x344, from Ext_ForwardCamera, to LD_SafetyMcu, frame-length=8, can-addressing-mode=STANDARD, can-fd-frame-support=false  # 0x344 PRE_COLLISION_2
        carries pdu PRE_COLLISION_2_IPdu: packing-byte-order=little-endian, start-position=0
      frame PCS_HUD: id 0x411, from Ext_ForwardCamera, to LD_SafetyMcu, frame-length=8, can-addressing-mode=STANDARD, can-fd-frame-support=false  # 0x411 PCS_HUD
        carries pdu PCS_HUD_IPdu: packing-byte-order=little-endian, start-position=0
      frame LKAS_HUD: id 0x412, from Ext_ForwardCamera, to LD_SafetyMcu, frame-length=8, can-addressing-mode=STANDARD, can-fd-frame-support=false  # 0x412 LKAS_HUD
        carries pdu LKAS_HUD_IPdu: packing-byte-order=little-endian, start-position=0
  gateway Panda_CameraForwarding: ecu=LD_SafetyMcu  # safety_fwd_hook copies every camera-bus frame to bus 0 unchanged except the TX messages with check_relay, which the item replaces (0x191, 0x2e4, 0x343, 0x412). Only the described frames are listed; every other camera frame is forwarded the same way.
    i-pdu-mappings:
      source-i-pdu=Channel/PRE_COLLISION_IPdu, target-i-pdu=Channel/PRE_COLLISION_IPdu
      source-i-pdu=Channel/PRE_COLLISION_2_IPdu, target-i-pdu=Channel/PRE_COLLISION_2_IPdu
      source-i-pdu=Channel/PCS_HUD_IPdu, target-i-pdu=Channel/PCS_HUD_IPdu
package /LionDriver/EcuInstances
  7 x ecu instance:
    Ext_AbsVsc  # absVsc (vehicle ECU) | Vehicle ECU at the item boundary, outside the item: Brake actuator: wheel speeds and brake-pedal state. Only its CAN interface to the item is described.
      can communication connector Bus0
    Ext_Cluster  # EXT-CLU (vehicle ECU) | Vehicle ECU at the item boundary, outside the item: Instrument cluster and cruise stalk: cruise main, set, resume, cancel; LKA HUD. Only its CAN interface to the item is described.
      can communication connector Bus0
    Ext_EPS  # EXT-EPS (vehicle ECU) | Vehicle ECU at the item boundary, outside the item: Receives LKA torque requests; reports driver torque, EPS torque and LKA state. Only its CAN interface to the item is described.
      can communication connector Bus0
    Ext_ForwardCamera  # forwardCamera (vehicle ECU) | Vehicle ECU at the item boundary, outside the item: Toyota forward camera: LKA and ACC outputs intercepted, PCS outputs forwarded. Only its CAN interface to the item is described.
      can communication connector Bus2
    Ext_PCM  # EXT-PCM (vehicle ECU) | Vehicle ECU at the item boundary, outside the item: Engine and powertrain ECU: ACC acceleration, permit-braking, cruise state. Only its CAN interface to the item is described.
      can communication connector Bus0
    LD_SafetyMcu  # E-04a safety MCU (panda, STM32H7) | The safety MCU running the panda firmware (E-03), bare metal. Not an AUTOSAR ECU. Its CAN controllers sit behind the harness (E-05).
      can communication connector Bus0
      can communication connector Bus2
    LD_SoC  # E-04b comma device SoC | Qualcomm SoC running AGNOS Linux: the openpilot processes (E-01, E-02). Not an AUTOSAR ECU. Its link to the safety MCU is SPI (HSI-01), which AUTOSAR's system template has no bus type for; the link is described by the client-server and sender-receiver interfaces between the two compositions.
package /LionDriver/System
  system LionDriver_ReferenceCar: category=SYSTEM_DESCRIPTION, system-version=0.1.0;opendbc_f23b4fa1df4b  # LD-SDA on CFG-001 Corolla E210 · ZRE212 · US | Reference configuration CFG-001 (TOYOTA_COROLLA_TSS2, safety mode toyota, DBC toyota_nodsu_pt_generated). SYSTEM-VERSION is the description version and the opendbc commit.
    system mapping Mapping
      data-mappings:
        data-element=Ext_AbsVsc.VehicleContext.Rx_PRE_COLLISION.COUNTER, system-signal=PRE_COLLISION_COUNTER
        data-element=Ext_AbsVsc.VehicleContext.Rx_PRE_COLLISION.SET_ME_X00, system-signal=PRE_COLLISION_SET_ME_X00
        data-element=Ext_AbsVsc.VehicleContext.Rx_PRE_COLLISION.FORCE, system-signal=PRE_COLLISION_FORCE
        data-element=Ext_AbsVsc.VehicleContext.Rx_PRE_COLLISION.SET_ME_X002, system-signal=PRE_COLLISION_SET_ME_X002
        data-element=Ext_AbsVsc.VehicleContext.Rx_PRE_COLLISION.BRAKE_STATUS, system-signal=PRE_COLLISION_BRAKE_STATUS
        data-element=Ext_AbsVsc.VehicleContext.Rx_PRE_COLLISION.STATE, system-signal=PRE_COLLISION_STATE
        data-element=Ext_AbsVsc.VehicleContext.Rx_PRE_COLLISION.SET_ME_X003, system-signal=PRE_COLLISION_SET_ME_X003
        data-element=Ext_AbsVsc.VehicleContext.Rx_PRE_COLLISION.PRECOLLISION_ACTIVE, system-signal=PRE_COLLISION_PRECOLLISION_ACTIVE
        data-element=Ext_AbsVsc.VehicleContext.Rx_PRE_COLLISION.CHECKSUM, system-signal=PRE_COLLISION_CHECKSUM
        data-element=Ext_AbsVsc.VehicleContext.Rx_PRE_COLLISION_2.DSS1GDRV, system-signal=PRE_COLLISION_2_DSS1GDRV
        data-element=Ext_AbsVsc.VehicleContext.Rx_PRE_COLLISION_2.PCSALM, system-signal=PRE_COLLISION_2_PCSALM
        data-element=Ext_AbsVsc.VehicleContext.Rx_PRE_COLLISION_2.IBTRGR, system-signal=PRE_COLLISION_2_IBTRGR
        data-element=Ext_AbsVsc.VehicleContext.Rx_PRE_COLLISION_2.PBATRGR, system-signal=PRE_COLLISION_2_PBATRGR
        data-element=Ext_AbsVsc.VehicleContext.Rx_PRE_COLLISION_2.PREFILL, system-signal=PRE_COLLISION_2_PREFILL
        data-element=Ext_AbsVsc.VehicleContext.Rx_PRE_COLLISION_2.AVSTRGR, system-signal=PRE_COLLISION_2_AVSTRGR
        data-element=Ext_AbsVsc.VehicleContext.Rx_PRE_COLLISION_2.CHECKSUM, system-signal=PRE_COLLISION_2_CHECKSUM
        data-element=Ext_AbsVsc.VehicleContext.Tx_BRAKE_MODULE.BRAKE_PRESSURE, system-signal=BRAKE_MODULE_BRAKE_PRESSURE
        data-element=Ext_AbsVsc.VehicleContext.Tx_BRAKE_MODULE.BRAKE_POSITION, system-signal=BRAKE_MODULE_BRAKE_POSITION
        data-element=Ext_AbsVsc.VehicleContext.Tx_BRAKE_MODULE.BRAKE_PRESSED, system-signal=BRAKE_MODULE_BRAKE_PRESSED
        data-element=Ext_AbsVsc.VehicleContext.Tx_SPEED.ENCODER, system-signal=SPEED_ENCODER
        data-element=Ext_AbsVsc.VehicleContext.Tx_SPEED.SPEED, system-signal=SPEED_SPEED
        data-element=Ext_AbsVsc.VehicleContext.Tx_SPEED.CHECKSUM, system-signal=SPEED_CHECKSUM
        data-element=Ext_AbsVsc.VehicleContext.Tx_WHEEL_SPEEDS.WHEEL_SPEED_FR_FAULT, system-signal=WHEEL_SPEEDS_WHEEL_SPEED_FR_FAULT
        data-element=Ext_AbsVsc.VehicleContext.Tx_WHEEL_SPEEDS.WHEEL_SPEED_FR, system-signal=WHEEL_SPEEDS_WHEEL_SPEED_FR
        data-element=Ext_AbsVsc.VehicleContext.Tx_WHEEL_SPEEDS.WHEEL_SPEED_FL_FAULT, system-signal=WHEEL_SPEEDS_WHEEL_SPEED_FL_FAULT
        data-element=Ext_AbsVsc.VehicleContext.Tx_WHEEL_SPEEDS.WHEEL_SPEED_FL, system-signal=WHEEL_SPEEDS_WHEEL_SPEED_FL
        data-element=Ext_AbsVsc.VehicleContext.Tx_WHEEL_SPEEDS.WHEEL_SPEED_RR_FAULT, system-signal=WHEEL_SPEEDS_WHEEL_SPEED_RR_FAULT
        data-element=Ext_AbsVsc.VehicleContext.Tx_WHEEL_SPEEDS.WHEEL_SPEED_RR, system-signal=WHEEL_SPEEDS_WHEEL_SPEED_RR
        data-element=Ext_AbsVsc.VehicleContext.Tx_WHEEL_SPEEDS.WHEEL_SPEED_RL_FAULT, system-signal=WHEEL_SPEEDS_WHEEL_SPEED_RL_FAULT
        data-element=Ext_AbsVsc.VehicleContext.Tx_WHEEL_SPEEDS.WHEEL_SPEED_RL, system-signal=WHEEL_SPEEDS_WHEEL_SPEED_RL
        data-element=Ext_Cluster.VehicleContext.Rx_LKAS_HUD.BARRIERS, system-signal=LKAS_HUD_BARRIERS
        data-element=Ext_Cluster.VehicleContext.Rx_LKAS_HUD.RIGHT_LINE, system-signal=LKAS_HUD_RIGHT_LINE
        data-element=Ext_Cluster.VehicleContext.Rx_LKAS_HUD.LEFT_LINE, system-signal=LKAS_HUD_LEFT_LINE
        data-element=Ext_Cluster.VehicleContext.Rx_LKAS_HUD.LKAS_STATUS, system-signal=LKAS_HUD_LKAS_STATUS
        data-element=Ext_Cluster.VehicleContext.Rx_LKAS_HUD.LDA_ALERT, system-signal=LKAS_HUD_LDA_ALERT
        data-element=Ext_Cluster.VehicleContext.Rx_LKAS_HUD.LDW_EXIST, system-signal=LKAS_HUD_LDW_EXIST
        data-element=Ext_Cluster.VehicleContext.Rx_LKAS_HUD.TWO_BEEPS, system-signal=LKAS_HUD_TWO_BEEPS
        data-element=Ext_Cluster.VehicleContext.Rx_LKAS_HUD.ADJUSTING_CAMERA, system-signal=LKAS_HUD_ADJUSTING_CAMERA
        data-element=Ext_Cluster.VehicleContext.Rx_LKAS_HUD.LDA_UNAVAILABLE_QUIET, system-signal=LKAS_HUD_LDA_UNAVAILABLE_QUIET
        data-element=Ext_Cluster.VehicleContext.Rx_LKAS_HUD.LDA_MALFUNCTION, system-signal=LKAS_HUD_LDA_MALFUNCTION
        data-element=Ext_Cluster.VehicleContext.Rx_LKAS_HUD.LDA_UNAVAILABLE, system-signal=LKAS_HUD_LDA_UNAVAILABLE
        data-element=Ext_Cluster.VehicleContext.Rx_LKAS_HUD.LDA_SENSITIVITY, system-signal=LKAS_HUD_LDA_SENSITIVITY
        data-element=Ext_Cluster.VehicleContext.Rx_LKAS_HUD.LDA_SA_TOGGLE, system-signal=LKAS_HUD_LDA_SA_TOGGLE
        data-element=Ext_Cluster.VehicleContext.Rx_LKAS_HUD.LDA_MESSAGES, system-signal=LKAS_HUD_LDA_MESSAGES
        data-element=Ext_Cluster.VehicleContext.Rx_LKAS_HUD.LDA_ON_MESSAGE, system-signal=LKAS_HUD_LDA_ON_MESSAGE
        data-element=Ext_Cluster.VehicleContext.Rx_LKAS_HUD.REPEATED_BEEPS, system-signal=LKAS_HUD_REPEATED_BEEPS
        data-element=Ext_Cluster.VehicleContext.Rx_LKAS_HUD.LANE_SWAY_TOGGLE, system-signal=LKAS_HUD_LANE_SWAY_TOGGLE
        data-element=Ext_Cluster.VehicleContext.Rx_LKAS_HUD.LANE_SWAY_SENSITIVITY, system-signal=LKAS_HUD_LANE_SWAY_SENSITIVITY
        data-element=Ext_Cluster.VehicleContext.Rx_LKAS_HUD.TAKE_CONTROL, system-signal=LKAS_HUD_TAKE_CONTROL
        data-element=Ext_Cluster.VehicleContext.Rx_LKAS_HUD.LDA_FRONT_CAMERA_BLOCKED, system-signal=LKAS_HUD_LDA_FRONT_CAMERA_BLOCKED
        data-element=Ext_Cluster.VehicleContext.Rx_LKAS_HUD.LANE_SWAY_BUZZER, system-signal=LKAS_HUD_LANE_SWAY_BUZZER
        data-element=Ext_Cluster.VehicleContext.Rx_LKAS_HUD.LANE_SWAY_FLD, system-signal=LKAS_HUD_LANE_SWAY_FLD
        data-element=Ext_Cluster.VehicleContext.Rx_LKAS_HUD.LANE_SWAY_WARNING, system-signal=LKAS_HUD_LANE_SWAY_WARNING
        data-element=Ext_Cluster.VehicleContext.Rx_LKAS_HUD.SET_ME_X01, system-signal=LKAS_HUD_SET_ME_X01
        data-element=Ext_Cluster.VehicleContext.Rx_LKAS_HUD.SET_ME_X02, system-signal=LKAS_HUD_SET_ME_X02
        data-element=Ext_Cluster.VehicleContext.Rx_PCS_HUD.PCS_INDICATOR, system-signal=PCS_HUD_PCS_INDICATOR
        data-element=Ext_Cluster.VehicleContext.Rx_PCS_HUD.FCW, system-signal=PCS_HUD_FCW
        data-element=Ext_Cluster.VehicleContext.Rx_PCS_HUD.SET_ME_X20, system-signal=PCS_HUD_SET_ME_X20
        data-element=Ext_Cluster.VehicleContext.Rx_PCS_HUD.PCS_DUST, system-signal=PCS_HUD_PCS_DUST
        data-element=Ext_Cluster.VehicleContext.Rx_PCS_HUD.PCS_TEMP, system-signal=PCS_HUD_PCS_TEMP
        data-element=Ext_Cluster.VehicleContext.Rx_PCS_HUD.PCS_DUST2, system-signal=PCS_HUD_PCS_DUST2
        data-element=Ext_Cluster.VehicleContext.Rx_PCS_HUD.PCS_TEMP2, system-signal=PCS_HUD_PCS_TEMP2
        data-element=Ext_Cluster.VehicleContext.Rx_PCS_HUD.SET_ME_X10, system-signal=PCS_HUD_SET_ME_X10
        data-element=Ext_Cluster.VehicleContext.Rx_PCS_HUD.PCS_OFF, system-signal=PCS_HUD_PCS_OFF
        data-element=Ext_Cluster.VehicleContext.Rx_PCS_HUD.FRD_ADJ, system-signal=PCS_HUD_FRD_ADJ
        data-element=Ext_Cluster.VehicleContext.Rx_PCS_HUD.PCS_SENSITIVITY, system-signal=PCS_HUD_PCS_SENSITIVITY
        data-element=Ext_EPS.VehicleContext.Rx_STEERING_LKA.LKA_STATE, system-signal=STEERING_LKA_LKA_STATE
        data-element=Ext_EPS.VehicleContext.Rx_STEERING_LKA.STEER_REQUEST, system-signal=STEERING_LKA_STEER_REQUEST
        data-element=Ext_EPS.VehicleContext.Rx_STEERING_LKA.COUNTER, system-signal=STEERING_LKA_COUNTER
        data-element=Ext_EPS.VehicleContext.Rx_STEERING_LKA.SET_ME_1, system-signal=STEERING_LKA_SET_ME_1
        data-element=Ext_EPS.VehicleContext.Rx_STEERING_LKA.STEER_TORQUE_CMD, system-signal=STEERING_LKA_STEER_TORQUE_CMD
        data-element=Ext_EPS.VehicleContext.Rx_STEERING_LKA.CHECKSUM, system-signal=STEERING_LKA_CHECKSUM
        data-element=Ext_EPS.VehicleContext.Rx_STEERING_LTA.CHECKSUM, system-signal=STEERING_LTA_CHECKSUM
        data-element=Ext_EPS.VehicleContext.Rx_STEERING_LTA.SETME_X3, system-signal=STEERING_LTA_SETME_X3
        data-element=Ext_EPS.VehicleContext.Rx_STEERING_LTA.PERCENTAGE, system-signal=STEERING_LTA_PERCENTAGE
        data-element=Ext_EPS.VehicleContext.Rx_STEERING_LTA.TORQUE_WIND_DOWN, system-signal=STEERING_LTA_TORQUE_WIND_DOWN
        data-element=Ext_EPS.VehicleContext.Rx_STEERING_LTA.ANGLE, system-signal=STEERING_LTA_ANGLE
        data-element=Ext_EPS.VehicleContext.Rx_STEERING_LTA.STEER_ANGLE_CMD, system-signal=STEERING_LTA_STEER_ANGLE_CMD
        data-element=Ext_EPS.VehicleContext.Rx_STEERING_LTA.STEER_REQUEST_2, system-signal=STEERING_LTA_STEER_REQUEST_2
        data-element=Ext_EPS.VehicleContext.Rx_STEERING_LTA.LKA_ACTIVE, system-signal=STEERING_LTA_LKA_ACTIVE
        data-element=Ext_EPS.VehicleContext.Rx_STEERING_LTA.CLEAR_HOLD_STEERING_ALERT, system-signal=STEERING_LTA_CLEAR_HOLD_STEERING_ALERT
        data-element=Ext_EPS.VehicleContext.Rx_STEERING_LTA.COUNTER, system-signal=STEERING_LTA_COUNTER
        data-element=Ext_EPS.VehicleContext.Rx_STEERING_LTA.STEER_REQUEST, system-signal=STEERING_LTA_STEER_REQUEST
        data-element=Ext_EPS.VehicleContext.Rx_STEERING_LTA.SETME_X1, system-signal=STEERING_LTA_SETME_X1
        data-element=Ext_EPS.VehicleContext.Tx_EPS_STATUS.IPAS_STATE, system-signal=EPS_STATUS_IPAS_STATE
        data-element=Ext_EPS.VehicleContext.Tx_EPS_STATUS.LKA_STATE, system-signal=EPS_STATUS_LKA_STATE
        data-element=Ext_EPS.VehicleContext.Tx_EPS_STATUS.LTA_STATE, system-signal=EPS_STATUS_LTA_STATE
        data-element=Ext_EPS.VehicleContext.Tx_EPS_STATUS.TYPE, system-signal=EPS_STATUS_TYPE
        data-element=Ext_EPS.VehicleContext.Tx_EPS_STATUS.CHECKSUM, system-signal=EPS_STATUS_CHECKSUM
        data-element=Ext_EPS.VehicleContext.Tx_STEER_TORQUE_SENSOR.STEER_TORQUE_EPS, system-signal=STEER_TORQUE_SENSOR_STEER_TORQUE_EPS
        data-element=Ext_EPS.VehicleContext.Tx_STEER_TORQUE_SENSOR.STEER_TORQUE_DRIVER, system-signal=STEER_TORQUE_SENSOR_STEER_TORQUE_DRIVER
        data-element=Ext_EPS.VehicleContext.Tx_STEER_TORQUE_SENSOR.STEER_ANGLE, system-signal=STEER_TORQUE_SENSOR_STEER_ANGLE
        data-element=Ext_EPS.VehicleContext.Tx_STEER_TORQUE_SENSOR.STEER_ANGLE_INITIALIZING, system-signal=STEER_TORQUE_SENSOR_STEER_ANGLE_INITIALIZING
        data-element=Ext_EPS.VehicleContext.Tx_STEER_TORQUE_SENSOR.STEER_OVERRIDE, system-signal=STEER_TORQUE_SENSOR_STEER_OVERRIDE
        data-element=Ext_EPS.VehicleContext.Tx_STEER_TORQUE_SENSOR.CHECKSUM, system-signal=STEER_TORQUE_SENSOR_CHECKSUM
        data-element=Ext_ForwardCamera.VehicleContext.Tx_ACC_CONTROL.ACCEL_CMD, system-signal=ACC_CONTROL_ACCEL_CMD
        data-element=Ext_ForwardCamera.VehicleContext.Tx_ACC_CONTROL.ALLOW_LONG_PRESS, system-signal=ACC_CONTROL_ALLOW_LONG_PRESS
        data-element=Ext_ForwardCamera.VehicleContext.Tx_ACC_CONTROL.ACC_MALFUNCTION, system-signal=ACC_CONTROL_ACC_MALFUNCTION
        data-element=Ext_ForwardCamera.VehicleContext.Tx_ACC_CONTROL.RADAR_DIRTY, system-signal=ACC_CONTROL_RADAR_DIRTY
        data-element=Ext_ForwardCamera.VehicleContext.Tx_ACC_CONTROL.DISTANCE, system-signal=ACC_CONTROL_DISTANCE
        data-element=Ext_ForwardCamera.VehicleContext.Tx_ACC_CONTROL.MINI_CAR, system-signal=ACC_CONTROL_MINI_CAR
        data-element=Ext_ForwardCamera.VehicleContext.Tx_ACC_CONTROL.ACC_TYPE, system-signal=ACC_CONTROL_ACC_TYPE
        data-element=Ext_ForwardCamera.VehicleContext.Tx_ACC_CONTROL.CANCEL_REQ, system-signal=ACC_CONTROL_CANCEL_REQ
        data-element=Ext_ForwardCamera.VehicleContext.Tx_ACC_CONTROL.ACC_CUT_IN, system-signal=ACC_CONTROL_ACC_CUT_IN
        data-element=Ext_ForwardCamera.VehicleContext.Tx_ACC_CONTROL.LEAD_VEHICLE_STOPPED, system-signal=ACC_CONTROL_LEAD_VEHICLE_STOPPED
        data-element=Ext_ForwardCamera.VehicleContext.Tx_ACC_CONTROL.PERMIT_BRAKING, system-signal=ACC_CONTROL_PERMIT_BRAKING
        data-element=Ext_ForwardCamera.VehicleContext.Tx_ACC_CONTROL.RELEASE_STANDSTILL, system-signal=ACC_CONTROL_RELEASE_STANDSTILL
        data-element=Ext_ForwardCamera.VehicleContext.Tx_ACC_CONTROL.ITS_CONNECT_LEAD, system-signal=ACC_CONTROL_ITS_CONNECT_LEAD
        data-element=Ext_ForwardCamera.VehicleContext.Tx_ACC_CONTROL.ACCEL_CMD_ALT, system-signal=ACC_CONTROL_ACCEL_CMD_ALT
        data-element=Ext_ForwardCamera.VehicleContext.Tx_ACC_CONTROL.CHECKSUM, system-signal=ACC_CONTROL_CHECKSUM
        data-element=Ext_ForwardCamera.VehicleContext.Tx_LKAS_HUD.BARRIERS, system-signal=LKAS_HUD_BARRIERS
        data-element=Ext_ForwardCamera.VehicleContext.Tx_LKAS_HUD.RIGHT_LINE, system-signal=LKAS_HUD_RIGHT_LINE
        data-element=Ext_ForwardCamera.VehicleContext.Tx_LKAS_HUD.LEFT_LINE, system-signal=LKAS_HUD_LEFT_LINE
        data-element=Ext_ForwardCamera.VehicleContext.Tx_LKAS_HUD.LKAS_STATUS, system-signal=LKAS_HUD_LKAS_STATUS
        data-element=Ext_ForwardCamera.VehicleContext.Tx_LKAS_HUD.LDA_ALERT, system-signal=LKAS_HUD_LDA_ALERT
        data-element=Ext_ForwardCamera.VehicleContext.Tx_LKAS_HUD.LDW_EXIST, system-signal=LKAS_HUD_LDW_EXIST
        data-element=Ext_ForwardCamera.VehicleContext.Tx_LKAS_HUD.TWO_BEEPS, system-signal=LKAS_HUD_TWO_BEEPS
        data-element=Ext_ForwardCamera.VehicleContext.Tx_LKAS_HUD.ADJUSTING_CAMERA, system-signal=LKAS_HUD_ADJUSTING_CAMERA
        data-element=Ext_ForwardCamera.VehicleContext.Tx_LKAS_HUD.LDA_UNAVAILABLE_QUIET, system-signal=LKAS_HUD_LDA_UNAVAILABLE_QUIET
        data-element=Ext_ForwardCamera.VehicleContext.Tx_LKAS_HUD.LDA_MALFUNCTION, system-signal=LKAS_HUD_LDA_MALFUNCTION
        data-element=Ext_ForwardCamera.VehicleContext.Tx_LKAS_HUD.LDA_UNAVAILABLE, system-signal=LKAS_HUD_LDA_UNAVAILABLE
        data-element=Ext_ForwardCamera.VehicleContext.Tx_LKAS_HUD.LDA_SENSITIVITY, system-signal=LKAS_HUD_LDA_SENSITIVITY
        data-element=Ext_ForwardCamera.VehicleContext.Tx_LKAS_HUD.LDA_SA_TOGGLE, system-signal=LKAS_HUD_LDA_SA_TOGGLE
        data-element=Ext_ForwardCamera.VehicleContext.Tx_LKAS_HUD.LDA_MESSAGES, system-signal=LKAS_HUD_LDA_MESSAGES
        data-element=Ext_ForwardCamera.VehicleContext.Tx_LKAS_HUD.LDA_ON_MESSAGE, system-signal=LKAS_HUD_LDA_ON_MESSAGE
        data-element=Ext_ForwardCamera.VehicleContext.Tx_LKAS_HUD.REPEATED_BEEPS, system-signal=LKAS_HUD_REPEATED_BEEPS
        data-element=Ext_ForwardCamera.VehicleContext.Tx_LKAS_HUD.LANE_SWAY_TOGGLE, system-signal=LKAS_HUD_LANE_SWAY_TOGGLE
        data-element=Ext_ForwardCamera.VehicleContext.Tx_LKAS_HUD.LANE_SWAY_SENSITIVITY, system-signal=LKAS_HUD_LANE_SWAY_SENSITIVITY
        data-element=Ext_ForwardCamera.VehicleContext.Tx_LKAS_HUD.TAKE_CONTROL, system-signal=LKAS_HUD_TAKE_CONTROL
        data-element=Ext_ForwardCamera.VehicleContext.Tx_LKAS_HUD.LDA_FRONT_CAMERA_BLOCKED, system-signal=LKAS_HUD_LDA_FRONT_CAMERA_BLOCKED
        data-element=Ext_ForwardCamera.VehicleContext.Tx_LKAS_HUD.LANE_SWAY_BUZZER, system-signal=LKAS_HUD_LANE_SWAY_BUZZER
        data-element=Ext_ForwardCamera.VehicleContext.Tx_LKAS_HUD.LANE_SWAY_FLD, system-signal=LKAS_HUD_LANE_SWAY_FLD
        data-element=Ext_ForwardCamera.VehicleContext.Tx_LKAS_HUD.LANE_SWAY_WARNING, system-signal=LKAS_HUD_LANE_SWAY_WARNING
        data-element=Ext_ForwardCamera.VehicleContext.Tx_LKAS_HUD.SET_ME_X01, system-signal=LKAS_HUD_SET_ME_X01
        data-element=Ext_ForwardCamera.VehicleContext.Tx_LKAS_HUD.SET_ME_X02, system-signal=LKAS_HUD_SET_ME_X02
        data-element=Ext_ForwardCamera.VehicleContext.Tx_PCS_HUD.PCS_INDICATOR, system-signal=PCS_HUD_PCS_INDICATOR
        data-element=Ext_ForwardCamera.VehicleContext.Tx_PCS_HUD.FCW, system-signal=PCS_HUD_FCW
        data-element=Ext_ForwardCamera.VehicleContext.Tx_PCS_HUD.SET_ME_X20, system-signal=PCS_HUD_SET_ME_X20
        data-element=Ext_ForwardCamera.VehicleContext.Tx_PCS_HUD.PCS_DUST, system-signal=PCS_HUD_PCS_DUST
        data-element=Ext_ForwardCamera.VehicleContext.Tx_PCS_HUD.PCS_TEMP, system-signal=PCS_HUD_PCS_TEMP
        data-element=Ext_ForwardCamera.VehicleContext.Tx_PCS_HUD.PCS_DUST2, system-signal=PCS_HUD_PCS_DUST2
        data-element=Ext_ForwardCamera.VehicleContext.Tx_PCS_HUD.PCS_TEMP2, system-signal=PCS_HUD_PCS_TEMP2
        data-element=Ext_ForwardCamera.VehicleContext.Tx_PCS_HUD.SET_ME_X10, system-signal=PCS_HUD_SET_ME_X10
        data-element=Ext_ForwardCamera.VehicleContext.Tx_PCS_HUD.PCS_OFF, system-signal=PCS_HUD_PCS_OFF
        data-element=Ext_ForwardCamera.VehicleContext.Tx_PCS_HUD.FRD_ADJ, system-signal=PCS_HUD_FRD_ADJ
        data-element=Ext_ForwardCamera.VehicleContext.Tx_PCS_HUD.PCS_SENSITIVITY, system-signal=PCS_HUD_PCS_SENSITIVITY
        data-element=Ext_ForwardCamera.VehicleContext.Tx_PRE_COLLISION.COUNTER, system-signal=PRE_COLLISION_COUNTER
        data-element=Ext_ForwardCamera.VehicleContext.Tx_PRE_COLLISION.SET_ME_X00, system-signal=PRE_COLLISION_SET_ME_X00
        data-element=Ext_ForwardCamera.VehicleContext.Tx_PRE_COLLISION.FORCE, system-signal=PRE_COLLISION_FORCE
        data-element=Ext_ForwardCamera.VehicleContext.Tx_PRE_COLLISION.SET_ME_X002, system-signal=PRE_COLLISION_SET_ME_X002
        data-element=Ext_ForwardCamera.VehicleContext.Tx_PRE_COLLISION.BRAKE_STATUS, system-signal=PRE_COLLISION_BRAKE_STATUS
        data-element=Ext_ForwardCamera.VehicleContext.Tx_PRE_COLLISION.STATE, system-signal=PRE_COLLISION_STATE
        data-element=Ext_ForwardCamera.VehicleContext.Tx_PRE_COLLISION.SET_ME_X003, system-signal=PRE_COLLISION_SET_ME_X003
        data-element=Ext_ForwardCamera.VehicleContext.Tx_PRE_COLLISION.PRECOLLISION_ACTIVE, system-signal=PRE_COLLISION_PRECOLLISION_ACTIVE
        data-element=Ext_ForwardCamera.VehicleContext.Tx_PRE_COLLISION.CHECKSUM, system-signal=PRE_COLLISION_CHECKSUM
        data-element=Ext_ForwardCamera.VehicleContext.Tx_PRE_COLLISION_2.DSS1GDRV, system-signal=PRE_COLLISION_2_DSS1GDRV
        data-element=Ext_ForwardCamera.VehicleContext.Tx_PRE_COLLISION_2.PCSALM, system-signal=PRE_COLLISION_2_PCSALM
        data-element=Ext_ForwardCamera.VehicleContext.Tx_PRE_COLLISION_2.IBTRGR, system-signal=PRE_COLLISION_2_IBTRGR
        data-element=Ext_ForwardCamera.VehicleContext.Tx_PRE_COLLISION_2.PBATRGR, system-signal=PRE_COLLISION_2_PBATRGR
        data-element=Ext_ForwardCamera.VehicleContext.Tx_PRE_COLLISION_2.PREFILL, system-signal=PRE_COLLISION_2_PREFILL
        data-element=Ext_ForwardCamera.VehicleContext.Tx_PRE_COLLISION_2.AVSTRGR, system-signal=PRE_COLLISION_2_AVSTRGR
        data-element=Ext_ForwardCamera.VehicleContext.Tx_PRE_COLLISION_2.CHECKSUM, system-signal=PRE_COLLISION_2_CHECKSUM
        data-element=Ext_ForwardCamera.VehicleContext.Tx_STEERING_LKA.LKA_STATE, system-signal=STEERING_LKA_LKA_STATE
        data-element=Ext_ForwardCamera.VehicleContext.Tx_STEERING_LKA.STEER_REQUEST, system-signal=STEERING_LKA_STEER_REQUEST
        data-element=Ext_ForwardCamera.VehicleContext.Tx_STEERING_LKA.COUNTER, system-signal=STEERING_LKA_COUNTER
        data-element=Ext_ForwardCamera.VehicleContext.Tx_STEERING_LKA.SET_ME_1, system-signal=STEERING_LKA_SET_ME_1
        data-element=Ext_ForwardCamera.VehicleContext.Tx_STEERING_LKA.STEER_TORQUE_CMD, system-signal=STEERING_LKA_STEER_TORQUE_CMD
        data-element=Ext_ForwardCamera.VehicleContext.Tx_STEERING_LKA.CHECKSUM, system-signal=STEERING_LKA_CHECKSUM
        data-element=Ext_ForwardCamera.VehicleContext.Tx_STEERING_LTA.CHECKSUM, system-signal=STEERING_LTA_CHECKSUM
        data-element=Ext_ForwardCamera.VehicleContext.Tx_STEERING_LTA.SETME_X3, system-signal=STEERING_LTA_SETME_X3
        data-element=Ext_ForwardCamera.VehicleContext.Tx_STEERING_LTA.PERCENTAGE, system-signal=STEERING_LTA_PERCENTAGE
        data-element=Ext_ForwardCamera.VehicleContext.Tx_STEERING_LTA.TORQUE_WIND_DOWN, system-signal=STEERING_LTA_TORQUE_WIND_DOWN
        data-element=Ext_ForwardCamera.VehicleContext.Tx_STEERING_LTA.ANGLE, system-signal=STEERING_LTA_ANGLE
        data-element=Ext_ForwardCamera.VehicleContext.Tx_STEERING_LTA.STEER_ANGLE_CMD, system-signal=STEERING_LTA_STEER_ANGLE_CMD
        data-element=Ext_ForwardCamera.VehicleContext.Tx_STEERING_LTA.STEER_REQUEST_2, system-signal=STEERING_LTA_STEER_REQUEST_2
        data-element=Ext_ForwardCamera.VehicleContext.Tx_STEERING_LTA.LKA_ACTIVE, system-signal=STEERING_LTA_LKA_ACTIVE
        data-element=Ext_ForwardCamera.VehicleContext.Tx_STEERING_LTA.CLEAR_HOLD_STEERING_ALERT, system-signal=STEERING_LTA_CLEAR_HOLD_STEERING_ALERT
        data-element=Ext_ForwardCamera.VehicleContext.Tx_STEERING_LTA.COUNTER, system-signal=STEERING_LTA_COUNTER
        data-element=Ext_ForwardCamera.VehicleContext.Tx_STEERING_LTA.STEER_REQUEST, system-signal=STEERING_LTA_STEER_REQUEST
        data-element=Ext_ForwardCamera.VehicleContext.Tx_STEERING_LTA.SETME_X1, system-signal=STEERING_LTA_SETME_X1
        data-element=Ext_PCM.VehicleContext.Rx_ACC_CONTROL.ACCEL_CMD, system-signal=ACC_CONTROL_ACCEL_CMD
        data-element=Ext_PCM.VehicleContext.Rx_ACC_CONTROL.ALLOW_LONG_PRESS, system-signal=ACC_CONTROL_ALLOW_LONG_PRESS
        data-element=Ext_PCM.VehicleContext.Rx_ACC_CONTROL.ACC_MALFUNCTION, system-signal=ACC_CONTROL_ACC_MALFUNCTION
        data-element=Ext_PCM.VehicleContext.Rx_ACC_CONTROL.RADAR_DIRTY, system-signal=ACC_CONTROL_RADAR_DIRTY
        data-element=Ext_PCM.VehicleContext.Rx_ACC_CONTROL.DISTANCE, system-signal=ACC_CONTROL_DISTANCE
        data-element=Ext_PCM.VehicleContext.Rx_ACC_CONTROL.MINI_CAR, system-signal=ACC_CONTROL_MINI_CAR
        data-element=Ext_PCM.VehicleContext.Rx_ACC_CONTROL.ACC_TYPE, system-signal=ACC_CONTROL_ACC_TYPE
        data-element=Ext_PCM.VehicleContext.Rx_ACC_CONTROL.CANCEL_REQ, system-signal=ACC_CONTROL_CANCEL_REQ
        data-element=Ext_PCM.VehicleContext.Rx_ACC_CONTROL.ACC_CUT_IN, system-signal=ACC_CONTROL_ACC_CUT_IN
        data-element=Ext_PCM.VehicleContext.Rx_ACC_CONTROL.LEAD_VEHICLE_STOPPED, system-signal=ACC_CONTROL_LEAD_VEHICLE_STOPPED
        data-element=Ext_PCM.VehicleContext.Rx_ACC_CONTROL.PERMIT_BRAKING, system-signal=ACC_CONTROL_PERMIT_BRAKING
        data-element=Ext_PCM.VehicleContext.Rx_ACC_CONTROL.RELEASE_STANDSTILL, system-signal=ACC_CONTROL_RELEASE_STANDSTILL
        data-element=Ext_PCM.VehicleContext.Rx_ACC_CONTROL.ITS_CONNECT_LEAD, system-signal=ACC_CONTROL_ITS_CONNECT_LEAD
        data-element=Ext_PCM.VehicleContext.Rx_ACC_CONTROL.ACCEL_CMD_ALT, system-signal=ACC_CONTROL_ACCEL_CMD_ALT
        data-element=Ext_PCM.VehicleContext.Rx_ACC_CONTROL.CHECKSUM, system-signal=ACC_CONTROL_CHECKSUM
        data-element=Ext_PCM.VehicleContext.Tx_PCM_CRUISE.GAS_RELEASED, system-signal=PCM_CRUISE_GAS_RELEASED
        data-element=Ext_PCM.VehicleContext.Tx_PCM_CRUISE.CRUISE_ACTIVE, system-signal=PCM_CRUISE_CRUISE_ACTIVE
        data-element=Ext_PCM.VehicleContext.Tx_PCM_CRUISE.ACC_BRAKING, system-signal=PCM_CRUISE_ACC_BRAKING
        data-element=Ext_PCM.VehicleContext.Tx_PCM_CRUISE.ACCEL_NET, system-signal=PCM_CRUISE_ACCEL_NET
        data-element=Ext_PCM.VehicleContext.Tx_PCM_CRUISE.NEUTRAL_FORCE, system-signal=PCM_CRUISE_NEUTRAL_FORCE
        data-element=Ext_PCM.VehicleContext.Tx_PCM_CRUISE.CRUISE_STATE, system-signal=PCM_CRUISE_CRUISE_STATE
        data-element=Ext_PCM.VehicleContext.Tx_PCM_CRUISE.CANCEL_REQ, system-signal=PCM_CRUISE_CANCEL_REQ
        data-element=Ext_PCM.VehicleContext.Tx_PCM_CRUISE.CHECKSUM, system-signal=PCM_CRUISE_CHECKSUM
        data-element=Ext_PCM.VehicleContext.Tx_PCM_CRUISE_2.BRAKE_PRESSED, system-signal=PCM_CRUISE_2_BRAKE_PRESSED
        data-element=Ext_PCM.VehicleContext.Tx_PCM_CRUISE_2.PCM_FOLLOW_DISTANCE, system-signal=PCM_CRUISE_2_PCM_FOLLOW_DISTANCE
        data-element=Ext_PCM.VehicleContext.Tx_PCM_CRUISE_2.LOW_SPEED_LOCKOUT, system-signal=PCM_CRUISE_2_LOW_SPEED_LOCKOUT
        data-element=Ext_PCM.VehicleContext.Tx_PCM_CRUISE_2.MAIN_ON, system-signal=PCM_CRUISE_2_MAIN_ON
        data-element=Ext_PCM.VehicleContext.Tx_PCM_CRUISE_2.SET_SPEED, system-signal=PCM_CRUISE_2_SET_SPEED
        data-element=Ext_PCM.VehicleContext.Tx_PCM_CRUISE_2.ACC_FAULTED, system-signal=PCM_CRUISE_2_ACC_FAULTED
        data-element=Ext_PCM.VehicleContext.Tx_PCM_CRUISE_2.CHECKSUM, system-signal=PCM_CRUISE_2_CHECKSUM
        data-element=LdSda.SafetyMcuFirmware.PlatformFirmware.VehicleContext.RxCam_ACC_CONTROL.ACCEL_CMD, system-signal=ACC_CONTROL_ACCEL_CMD
        data-element=LdSda.SafetyMcuFirmware.PlatformFirmware.VehicleContext.RxCam_ACC_CONTROL.ALLOW_LONG_PRESS, system-signal=ACC_CONTROL_ALLOW_LONG_PRESS
        data-element=LdSda.SafetyMcuFirmware.PlatformFirmware.VehicleContext.RxCam_ACC_CONTROL.ACC_MALFUNCTION, system-signal=ACC_CONTROL_ACC_MALFUNCTION
        data-element=LdSda.SafetyMcuFirmware.PlatformFirmware.VehicleContext.RxCam_ACC_CONTROL.RADAR_DIRTY, system-signal=ACC_CONTROL_RADAR_DIRTY
        data-element=LdSda.SafetyMcuFirmware.PlatformFirmware.VehicleContext.RxCam_ACC_CONTROL.DISTANCE, system-signal=ACC_CONTROL_DISTANCE
        data-element=LdSda.SafetyMcuFirmware.PlatformFirmware.VehicleContext.RxCam_ACC_CONTROL.MINI_CAR, system-signal=ACC_CONTROL_MINI_CAR
        data-element=LdSda.SafetyMcuFirmware.PlatformFirmware.VehicleContext.RxCam_ACC_CONTROL.ACC_TYPE, system-signal=ACC_CONTROL_ACC_TYPE
        data-element=LdSda.SafetyMcuFirmware.PlatformFirmware.VehicleContext.RxCam_ACC_CONTROL.CANCEL_REQ, system-signal=ACC_CONTROL_CANCEL_REQ
        data-element=LdSda.SafetyMcuFirmware.PlatformFirmware.VehicleContext.RxCam_ACC_CONTROL.ACC_CUT_IN, system-signal=ACC_CONTROL_ACC_CUT_IN
        data-element=LdSda.SafetyMcuFirmware.PlatformFirmware.VehicleContext.RxCam_ACC_CONTROL.LEAD_VEHICLE_STOPPED, system-signal=ACC_CONTROL_LEAD_VEHICLE_STOPPED
        data-element=LdSda.SafetyMcuFirmware.PlatformFirmware.VehicleContext.RxCam_ACC_CONTROL.PERMIT_BRAKING, system-signal=ACC_CONTROL_PERMIT_BRAKING
        data-element=LdSda.SafetyMcuFirmware.PlatformFirmware.VehicleContext.RxCam_ACC_CONTROL.RELEASE_STANDSTILL, system-signal=ACC_CONTROL_RELEASE_STANDSTILL
        data-element=LdSda.SafetyMcuFirmware.PlatformFirmware.VehicleContext.RxCam_ACC_CONTROL.ITS_CONNECT_LEAD, system-signal=ACC_CONTROL_ITS_CONNECT_LEAD
        data-element=LdSda.SafetyMcuFirmware.PlatformFirmware.VehicleContext.RxCam_ACC_CONTROL.ACCEL_CMD_ALT, system-signal=ACC_CONTROL_ACCEL_CMD_ALT
        data-element=LdSda.SafetyMcuFirmware.PlatformFirmware.VehicleContext.RxCam_ACC_CONTROL.CHECKSUM, system-signal=ACC_CONTROL_CHECKSUM
        data-element=LdSda.SafetyMcuFirmware.PlatformFirmware.VehicleContext.RxCam_LKAS_HUD.BARRIERS, system-signal=LKAS_HUD_BARRIERS
        data-element=LdSda.SafetyMcuFirmware.PlatformFirmware.VehicleContext.RxCam_LKAS_HUD.RIGHT_LINE, system-signal=LKAS_HUD_RIGHT_LINE
        data-element=LdSda.SafetyMcuFirmware.PlatformFirmware.VehicleContext.RxCam_LKAS_HUD.LEFT_LINE, system-signal=LKAS_HUD_LEFT_LINE
        data-element=LdSda.SafetyMcuFirmware.PlatformFirmware.VehicleContext.RxCam_LKAS_HUD.LKAS_STATUS, system-signal=LKAS_HUD_LKAS_STATUS
        data-element=LdSda.SafetyMcuFirmware.PlatformFirmware.VehicleContext.RxCam_LKAS_HUD.LDA_ALERT, system-signal=LKAS_HUD_LDA_ALERT
        data-element=LdSda.SafetyMcuFirmware.PlatformFirmware.VehicleContext.RxCam_LKAS_HUD.LDW_EXIST, system-signal=LKAS_HUD_LDW_EXIST
        data-element=LdSda.SafetyMcuFirmware.PlatformFirmware.VehicleContext.RxCam_LKAS_HUD.TWO_BEEPS, system-signal=LKAS_HUD_TWO_BEEPS
        data-element=LdSda.SafetyMcuFirmware.PlatformFirmware.VehicleContext.RxCam_LKAS_HUD.ADJUSTING_CAMERA, system-signal=LKAS_HUD_ADJUSTING_CAMERA
        data-element=LdSda.SafetyMcuFirmware.PlatformFirmware.VehicleContext.RxCam_LKAS_HUD.LDA_UNAVAILABLE_QUIET, system-signal=LKAS_HUD_LDA_UNAVAILABLE_QUIET
        data-element=LdSda.SafetyMcuFirmware.PlatformFirmware.VehicleContext.RxCam_LKAS_HUD.LDA_MALFUNCTION, system-signal=LKAS_HUD_LDA_MALFUNCTION
        data-element=LdSda.SafetyMcuFirmware.PlatformFirmware.VehicleContext.RxCam_LKAS_HUD.LDA_UNAVAILABLE, system-signal=LKAS_HUD_LDA_UNAVAILABLE
        data-element=LdSda.SafetyMcuFirmware.PlatformFirmware.VehicleContext.RxCam_LKAS_HUD.LDA_SENSITIVITY, system-signal=LKAS_HUD_LDA_SENSITIVITY
        data-element=LdSda.SafetyMcuFirmware.PlatformFirmware.VehicleContext.RxCam_LKAS_HUD.LDA_SA_TOGGLE, system-signal=LKAS_HUD_LDA_SA_TOGGLE
        data-element=LdSda.SafetyMcuFirmware.PlatformFirmware.VehicleContext.RxCam_LKAS_HUD.LDA_MESSAGES, system-signal=LKAS_HUD_LDA_MESSAGES
        data-element=LdSda.SafetyMcuFirmware.PlatformFirmware.VehicleContext.RxCam_LKAS_HUD.LDA_ON_MESSAGE, system-signal=LKAS_HUD_LDA_ON_MESSAGE
        data-element=LdSda.SafetyMcuFirmware.PlatformFirmware.VehicleContext.RxCam_LKAS_HUD.REPEATED_BEEPS, system-signal=LKAS_HUD_REPEATED_BEEPS
        data-element=LdSda.SafetyMcuFirmware.PlatformFirmware.VehicleContext.RxCam_LKAS_HUD.LANE_SWAY_TOGGLE, system-signal=LKAS_HUD_LANE_SWAY_TOGGLE
        data-element=LdSda.SafetyMcuFirmware.PlatformFirmware.VehicleContext.RxCam_LKAS_HUD.LANE_SWAY_SENSITIVITY, system-signal=LKAS_HUD_LANE_SWAY_SENSITIVITY
        data-element=LdSda.SafetyMcuFirmware.PlatformFirmware.VehicleContext.RxCam_LKAS_HUD.TAKE_CONTROL, system-signal=LKAS_HUD_TAKE_CONTROL
        data-element=LdSda.SafetyMcuFirmware.PlatformFirmware.VehicleContext.RxCam_LKAS_HUD.LDA_FRONT_CAMERA_BLOCKED, system-signal=LKAS_HUD_LDA_FRONT_CAMERA_BLOCKED
        data-element=LdSda.SafetyMcuFirmware.PlatformFirmware.VehicleContext.RxCam_LKAS_HUD.LANE_SWAY_BUZZER, system-signal=LKAS_HUD_LANE_SWAY_BUZZER
        data-element=LdSda.SafetyMcuFirmware.PlatformFirmware.VehicleContext.RxCam_LKAS_HUD.LANE_SWAY_FLD, system-signal=LKAS_HUD_LANE_SWAY_FLD
        data-element=LdSda.SafetyMcuFirmware.PlatformFirmware.VehicleContext.RxCam_LKAS_HUD.LANE_SWAY_WARNING, system-signal=LKAS_HUD_LANE_SWAY_WARNING
        data-element=LdSda.SafetyMcuFirmware.PlatformFirmware.VehicleContext.RxCam_LKAS_HUD.SET_ME_X01, system-signal=LKAS_HUD_SET_ME_X01
        data-element=LdSda.SafetyMcuFirmware.PlatformFirmware.VehicleContext.RxCam_LKAS_HUD.SET_ME_X02, system-signal=LKAS_HUD_SET_ME_X02
        data-element=LdSda.SafetyMcuFirmware.PlatformFirmware.VehicleContext.RxCam_PCS_HUD.PCS_INDICATOR, system-signal=PCS_HUD_PCS_INDICATOR
        data-element=LdSda.SafetyMcuFirmware.PlatformFirmware.VehicleContext.RxCam_PCS_HUD.FCW, system-signal=PCS_HUD_FCW
        data-element=LdSda.SafetyMcuFirmware.PlatformFirmware.VehicleContext.RxCam_PCS_HUD.SET_ME_X20, system-signal=PCS_HUD_SET_ME_X20
        data-element=LdSda.SafetyMcuFirmware.PlatformFirmware.VehicleContext.RxCam_PCS_HUD.PCS_DUST, system-signal=PCS_HUD_PCS_DUST
        data-element=LdSda.SafetyMcuFirmware.PlatformFirmware.VehicleContext.RxCam_PCS_HUD.PCS_TEMP, system-signal=PCS_HUD_PCS_TEMP
        data-element=LdSda.SafetyMcuFirmware.PlatformFirmware.VehicleContext.RxCam_PCS_HUD.PCS_DUST2, system-signal=PCS_HUD_PCS_DUST2
        data-element=LdSda.SafetyMcuFirmware.PlatformFirmware.VehicleContext.RxCam_PCS_HUD.PCS_TEMP2, system-signal=PCS_HUD_PCS_TEMP2
        data-element=LdSda.SafetyMcuFirmware.PlatformFirmware.VehicleContext.RxCam_PCS_HUD.SET_ME_X10, system-signal=PCS_HUD_SET_ME_X10
        data-element=LdSda.SafetyMcuFirmware.PlatformFirmware.VehicleContext.RxCam_PCS_HUD.PCS_OFF, system-signal=PCS_HUD_PCS_OFF
        data-element=LdSda.SafetyMcuFirmware.PlatformFirmware.VehicleContext.RxCam_PCS_HUD.FRD_ADJ, system-signal=PCS_HUD_FRD_ADJ
        data-element=LdSda.SafetyMcuFirmware.PlatformFirmware.VehicleContext.RxCam_PCS_HUD.PCS_SENSITIVITY, system-signal=PCS_HUD_PCS_SENSITIVITY
        data-element=LdSda.SafetyMcuFirmware.PlatformFirmware.VehicleContext.RxCam_PRE_COLLISION.COUNTER, system-signal=PRE_COLLISION_COUNTER
        data-element=LdSda.SafetyMcuFirmware.PlatformFirmware.VehicleContext.RxCam_PRE_COLLISION.SET_ME_X00, system-signal=PRE_COLLISION_SET_ME_X00
        data-element=LdSda.SafetyMcuFirmware.PlatformFirmware.VehicleContext.RxCam_PRE_COLLISION.FORCE, system-signal=PRE_COLLISION_FORCE
        data-element=LdSda.SafetyMcuFirmware.PlatformFirmware.VehicleContext.RxCam_PRE_COLLISION.SET_ME_X002, system-signal=PRE_COLLISION_SET_ME_X002
        data-element=LdSda.SafetyMcuFirmware.PlatformFirmware.VehicleContext.RxCam_PRE_COLLISION.BRAKE_STATUS, system-signal=PRE_COLLISION_BRAKE_STATUS
        data-element=LdSda.SafetyMcuFirmware.PlatformFirmware.VehicleContext.RxCam_PRE_COLLISION.STATE, system-signal=PRE_COLLISION_STATE
        data-element=LdSda.SafetyMcuFirmware.PlatformFirmware.VehicleContext.RxCam_PRE_COLLISION.SET_ME_X003, system-signal=PRE_COLLISION_SET_ME_X003
        data-element=LdSda.SafetyMcuFirmware.PlatformFirmware.VehicleContext.RxCam_PRE_COLLISION.PRECOLLISION_ACTIVE, system-signal=PRE_COLLISION_PRECOLLISION_ACTIVE
        data-element=LdSda.SafetyMcuFirmware.PlatformFirmware.VehicleContext.RxCam_PRE_COLLISION.CHECKSUM, system-signal=PRE_COLLISION_CHECKSUM
        data-element=LdSda.SafetyMcuFirmware.PlatformFirmware.VehicleContext.RxCam_PRE_COLLISION_2.DSS1GDRV, system-signal=PRE_COLLISION_2_DSS1GDRV
        data-element=LdSda.SafetyMcuFirmware.PlatformFirmware.VehicleContext.RxCam_PRE_COLLISION_2.PCSALM, system-signal=PRE_COLLISION_2_PCSALM
        data-element=LdSda.SafetyMcuFirmware.PlatformFirmware.VehicleContext.RxCam_PRE_COLLISION_2.IBTRGR, system-signal=PRE_COLLISION_2_IBTRGR
        data-element=LdSda.SafetyMcuFirmware.PlatformFirmware.VehicleContext.RxCam_PRE_COLLISION_2.PBATRGR, system-signal=PRE_COLLISION_2_PBATRGR
        data-element=LdSda.SafetyMcuFirmware.PlatformFirmware.VehicleContext.RxCam_PRE_COLLISION_2.PREFILL, system-signal=PRE_COLLISION_2_PREFILL
        data-element=LdSda.SafetyMcuFirmware.PlatformFirmware.VehicleContext.RxCam_PRE_COLLISION_2.AVSTRGR, system-signal=PRE_COLLISION_2_AVSTRGR
        data-element=LdSda.SafetyMcuFirmware.PlatformFirmware.VehicleContext.RxCam_PRE_COLLISION_2.CHECKSUM, system-signal=PRE_COLLISION_2_CHECKSUM
        data-element=LdSda.SafetyMcuFirmware.PlatformFirmware.VehicleContext.RxCam_STEERING_LKA.LKA_STATE, system-signal=STEERING_LKA_LKA_STATE
        data-element=LdSda.SafetyMcuFirmware.PlatformFirmware.VehicleContext.RxCam_STEERING_LKA.STEER_REQUEST, system-signal=STEERING_LKA_STEER_REQUEST
        data-element=LdSda.SafetyMcuFirmware.PlatformFirmware.VehicleContext.RxCam_STEERING_LKA.COUNTER, system-signal=STEERING_LKA_COUNTER
        data-element=LdSda.SafetyMcuFirmware.PlatformFirmware.VehicleContext.RxCam_STEERING_LKA.SET_ME_1, system-signal=STEERING_LKA_SET_ME_1
        data-element=LdSda.SafetyMcuFirmware.PlatformFirmware.VehicleContext.RxCam_STEERING_LKA.STEER_TORQUE_CMD, system-signal=STEERING_LKA_STEER_TORQUE_CMD
        data-element=LdSda.SafetyMcuFirmware.PlatformFirmware.VehicleContext.RxCam_STEERING_LKA.CHECKSUM, system-signal=STEERING_LKA_CHECKSUM
        data-element=LdSda.SafetyMcuFirmware.PlatformFirmware.VehicleContext.RxCam_STEERING_LTA.CHECKSUM, system-signal=STEERING_LTA_CHECKSUM
        data-element=LdSda.SafetyMcuFirmware.PlatformFirmware.VehicleContext.RxCam_STEERING_LTA.SETME_X3, system-signal=STEERING_LTA_SETME_X3
        data-element=LdSda.SafetyMcuFirmware.PlatformFirmware.VehicleContext.RxCam_STEERING_LTA.PERCENTAGE, system-signal=STEERING_LTA_PERCENTAGE
        data-element=LdSda.SafetyMcuFirmware.PlatformFirmware.VehicleContext.RxCam_STEERING_LTA.TORQUE_WIND_DOWN, system-signal=STEERING_LTA_TORQUE_WIND_DOWN
        data-element=LdSda.SafetyMcuFirmware.PlatformFirmware.VehicleContext.RxCam_STEERING_LTA.ANGLE, system-signal=STEERING_LTA_ANGLE
        data-element=LdSda.SafetyMcuFirmware.PlatformFirmware.VehicleContext.RxCam_STEERING_LTA.STEER_ANGLE_CMD, system-signal=STEERING_LTA_STEER_ANGLE_CMD
        data-element=LdSda.SafetyMcuFirmware.PlatformFirmware.VehicleContext.RxCam_STEERING_LTA.STEER_REQUEST_2, system-signal=STEERING_LTA_STEER_REQUEST_2
        data-element=LdSda.SafetyMcuFirmware.PlatformFirmware.VehicleContext.RxCam_STEERING_LTA.LKA_ACTIVE, system-signal=STEERING_LTA_LKA_ACTIVE
        data-element=LdSda.SafetyMcuFirmware.PlatformFirmware.VehicleContext.RxCam_STEERING_LTA.CLEAR_HOLD_STEERING_ALERT, system-signal=STEERING_LTA_CLEAR_HOLD_STEERING_ALERT
        data-element=LdSda.SafetyMcuFirmware.PlatformFirmware.VehicleContext.RxCam_STEERING_LTA.COUNTER, system-signal=STEERING_LTA_COUNTER
        data-element=LdSda.SafetyMcuFirmware.PlatformFirmware.VehicleContext.RxCam_STEERING_LTA.STEER_REQUEST, system-signal=STEERING_LTA_STEER_REQUEST
        data-element=LdSda.SafetyMcuFirmware.PlatformFirmware.VehicleContext.RxCam_STEERING_LTA.SETME_X1, system-signal=STEERING_LTA_SETME_X1
        data-element=LdSda.SafetyMcuFirmware.PlatformFirmware.VehicleContext.Rx_BRAKE_MODULE.BRAKE_PRESSURE, system-signal=BRAKE_MODULE_BRAKE_PRESSURE
        data-element=LdSda.SafetyMcuFirmware.PlatformFirmware.VehicleContext.Rx_BRAKE_MODULE.BRAKE_POSITION, system-signal=BRAKE_MODULE_BRAKE_POSITION
        data-element=LdSda.SafetyMcuFirmware.PlatformFirmware.VehicleContext.Rx_BRAKE_MODULE.BRAKE_PRESSED, system-signal=BRAKE_MODULE_BRAKE_PRESSED
        data-element=LdSda.SafetyMcuFirmware.PlatformFirmware.VehicleContext.Rx_EPS_STATUS.IPAS_STATE, system-signal=EPS_STATUS_IPAS_STATE
        data-element=LdSda.SafetyMcuFirmware.PlatformFirmware.VehicleContext.Rx_EPS_STATUS.LKA_STATE, system-signal=EPS_STATUS_LKA_STATE
        data-element=LdSda.SafetyMcuFirmware.PlatformFirmware.VehicleContext.Rx_EPS_STATUS.LTA_STATE, system-signal=EPS_STATUS_LTA_STATE
        data-element=LdSda.SafetyMcuFirmware.PlatformFirmware.VehicleContext.Rx_EPS_STATUS.TYPE, system-signal=EPS_STATUS_TYPE
        data-element=LdSda.SafetyMcuFirmware.PlatformFirmware.VehicleContext.Rx_EPS_STATUS.CHECKSUM, system-signal=EPS_STATUS_CHECKSUM
        data-element=LdSda.SafetyMcuFirmware.PlatformFirmware.VehicleContext.Rx_PCM_CRUISE.GAS_RELEASED, system-signal=PCM_CRUISE_GAS_RELEASED
        data-element=LdSda.SafetyMcuFirmware.PlatformFirmware.VehicleContext.Rx_PCM_CRUISE.CRUISE_ACTIVE, system-signal=PCM_CRUISE_CRUISE_ACTIVE
        data-element=LdSda.SafetyMcuFirmware.PlatformFirmware.VehicleContext.Rx_PCM_CRUISE.ACC_BRAKING, system-signal=PCM_CRUISE_ACC_BRAKING
        data-element=LdSda.SafetyMcuFirmware.PlatformFirmware.VehicleContext.Rx_PCM_CRUISE.ACCEL_NET, system-signal=PCM_CRUISE_ACCEL_NET
        data-element=LdSda.SafetyMcuFirmware.PlatformFirmware.VehicleContext.Rx_PCM_CRUISE.NEUTRAL_FORCE, system-signal=PCM_CRUISE_NEUTRAL_FORCE
        data-element=LdSda.SafetyMcuFirmware.PlatformFirmware.VehicleContext.Rx_PCM_CRUISE.CRUISE_STATE, system-signal=PCM_CRUISE_CRUISE_STATE
        data-element=LdSda.SafetyMcuFirmware.PlatformFirmware.VehicleContext.Rx_PCM_CRUISE.CANCEL_REQ, system-signal=PCM_CRUISE_CANCEL_REQ
        data-element=LdSda.SafetyMcuFirmware.PlatformFirmware.VehicleContext.Rx_PCM_CRUISE.CHECKSUM, system-signal=PCM_CRUISE_CHECKSUM
        data-element=LdSda.SafetyMcuFirmware.PlatformFirmware.VehicleContext.Rx_PCM_CRUISE_2.BRAKE_PRESSED, system-signal=PCM_CRUISE_2_BRAKE_PRESSED
        data-element=LdSda.SafetyMcuFirmware.PlatformFirmware.VehicleContext.Rx_PCM_CRUISE_2.PCM_FOLLOW_DISTANCE, system-signal=PCM_CRUISE_2_PCM_FOLLOW_DISTANCE
        data-element=LdSda.SafetyMcuFirmware.PlatformFirmware.VehicleContext.Rx_PCM_CRUISE_2.LOW_SPEED_LOCKOUT, system-signal=PCM_CRUISE_2_LOW_SPEED_LOCKOUT
        data-element=LdSda.SafetyMcuFirmware.PlatformFirmware.VehicleContext.Rx_PCM_CRUISE_2.MAIN_ON, system-signal=PCM_CRUISE_2_MAIN_ON
        data-element=LdSda.SafetyMcuFirmware.PlatformFirmware.VehicleContext.Rx_PCM_CRUISE_2.SET_SPEED, system-signal=PCM_CRUISE_2_SET_SPEED
        data-element=LdSda.SafetyMcuFirmware.PlatformFirmware.VehicleContext.Rx_PCM_CRUISE_2.ACC_FAULTED, system-signal=PCM_CRUISE_2_ACC_FAULTED
        data-element=LdSda.SafetyMcuFirmware.PlatformFirmware.VehicleContext.Rx_PCM_CRUISE_2.CHECKSUM, system-signal=PCM_CRUISE_2_CHECKSUM
        data-element=LdSda.SafetyMcuFirmware.PlatformFirmware.VehicleContext.Rx_SPEED.ENCODER, system-signal=SPEED_ENCODER
        data-element=LdSda.SafetyMcuFirmware.PlatformFirmware.VehicleContext.Rx_SPEED.SPEED, system-signal=SPEED_SPEED
        data-element=LdSda.SafetyMcuFirmware.PlatformFirmware.VehicleContext.Rx_SPEED.CHECKSUM, system-signal=SPEED_CHECKSUM
        data-element=LdSda.SafetyMcuFirmware.PlatformFirmware.VehicleContext.Rx_STEER_TORQUE_SENSOR.STEER_TORQUE_EPS, system-signal=STEER_TORQUE_SENSOR_STEER_TORQUE_EPS
        data-element=LdSda.SafetyMcuFirmware.PlatformFirmware.VehicleContext.Rx_STEER_TORQUE_SENSOR.STEER_TORQUE_DRIVER, system-signal=STEER_TORQUE_SENSOR_STEER_TORQUE_DRIVER
        data-element=LdSda.SafetyMcuFirmware.PlatformFirmware.VehicleContext.Rx_STEER_TORQUE_SENSOR.STEER_ANGLE, system-signal=STEER_TORQUE_SENSOR_STEER_ANGLE
        data-element=LdSda.SafetyMcuFirmware.PlatformFirmware.VehicleContext.Rx_STEER_TORQUE_SENSOR.STEER_ANGLE_INITIALIZING, system-signal=STEER_TORQUE_SENSOR_STEER_ANGLE_INITIALIZING
        data-element=LdSda.SafetyMcuFirmware.PlatformFirmware.VehicleContext.Rx_STEER_TORQUE_SENSOR.STEER_OVERRIDE, system-signal=STEER_TORQUE_SENSOR_STEER_OVERRIDE
        data-element=LdSda.SafetyMcuFirmware.PlatformFirmware.VehicleContext.Rx_STEER_TORQUE_SENSOR.CHECKSUM, system-signal=STEER_TORQUE_SENSOR_CHECKSUM
        data-element=LdSda.SafetyMcuFirmware.PlatformFirmware.VehicleContext.Rx_WHEEL_SPEEDS.WHEEL_SPEED_FR_FAULT, system-signal=WHEEL_SPEEDS_WHEEL_SPEED_FR_FAULT
        data-element=LdSda.SafetyMcuFirmware.PlatformFirmware.VehicleContext.Rx_WHEEL_SPEEDS.WHEEL_SPEED_FR, system-signal=WHEEL_SPEEDS_WHEEL_SPEED_FR
        data-element=LdSda.SafetyMcuFirmware.PlatformFirmware.VehicleContext.Rx_WHEEL_SPEEDS.WHEEL_SPEED_FL_FAULT, system-signal=WHEEL_SPEEDS_WHEEL_SPEED_FL_FAULT
        data-element=LdSda.SafetyMcuFirmware.PlatformFirmware.VehicleContext.Rx_WHEEL_SPEEDS.WHEEL_SPEED_FL, system-signal=WHEEL_SPEEDS_WHEEL_SPEED_FL
        data-element=LdSda.SafetyMcuFirmware.PlatformFirmware.VehicleContext.Rx_WHEEL_SPEEDS.WHEEL_SPEED_RR_FAULT, system-signal=WHEEL_SPEEDS_WHEEL_SPEED_RR_FAULT
        data-element=LdSda.SafetyMcuFirmware.PlatformFirmware.VehicleContext.Rx_WHEEL_SPEEDS.WHEEL_SPEED_RR, system-signal=WHEEL_SPEEDS_WHEEL_SPEED_RR
        data-element=LdSda.SafetyMcuFirmware.PlatformFirmware.VehicleContext.Rx_WHEEL_SPEEDS.WHEEL_SPEED_RL_FAULT, system-signal=WHEEL_SPEEDS_WHEEL_SPEED_RL_FAULT
        data-element=LdSda.SafetyMcuFirmware.PlatformFirmware.VehicleContext.Rx_WHEEL_SPEEDS.WHEEL_SPEED_RL, system-signal=WHEEL_SPEEDS_WHEEL_SPEED_RL
        data-element=LdSda.SafetyMcuFirmware.PlatformFirmware.VehicleContext.Tx_ACC_CONTROL.ACCEL_CMD, system-signal=ACC_CONTROL_ACCEL_CMD
        data-element=LdSda.SafetyMcuFirmware.PlatformFirmware.VehicleContext.Tx_ACC_CONTROL.ALLOW_LONG_PRESS, system-signal=ACC_CONTROL_ALLOW_LONG_PRESS
        data-element=LdSda.SafetyMcuFirmware.PlatformFirmware.VehicleContext.Tx_ACC_CONTROL.ACC_MALFUNCTION, system-signal=ACC_CONTROL_ACC_MALFUNCTION
        data-element=LdSda.SafetyMcuFirmware.PlatformFirmware.VehicleContext.Tx_ACC_CONTROL.RADAR_DIRTY, system-signal=ACC_CONTROL_RADAR_DIRTY
        data-element=LdSda.SafetyMcuFirmware.PlatformFirmware.VehicleContext.Tx_ACC_CONTROL.DISTANCE, system-signal=ACC_CONTROL_DISTANCE
        data-element=LdSda.SafetyMcuFirmware.PlatformFirmware.VehicleContext.Tx_ACC_CONTROL.MINI_CAR, system-signal=ACC_CONTROL_MINI_CAR
        data-element=LdSda.SafetyMcuFirmware.PlatformFirmware.VehicleContext.Tx_ACC_CONTROL.ACC_TYPE, system-signal=ACC_CONTROL_ACC_TYPE
        data-element=LdSda.SafetyMcuFirmware.PlatformFirmware.VehicleContext.Tx_ACC_CONTROL.CANCEL_REQ, system-signal=ACC_CONTROL_CANCEL_REQ
        data-element=LdSda.SafetyMcuFirmware.PlatformFirmware.VehicleContext.Tx_ACC_CONTROL.ACC_CUT_IN, system-signal=ACC_CONTROL_ACC_CUT_IN
        data-element=LdSda.SafetyMcuFirmware.PlatformFirmware.VehicleContext.Tx_ACC_CONTROL.LEAD_VEHICLE_STOPPED, system-signal=ACC_CONTROL_LEAD_VEHICLE_STOPPED
        data-element=LdSda.SafetyMcuFirmware.PlatformFirmware.VehicleContext.Tx_ACC_CONTROL.PERMIT_BRAKING, system-signal=ACC_CONTROL_PERMIT_BRAKING
        data-element=LdSda.SafetyMcuFirmware.PlatformFirmware.VehicleContext.Tx_ACC_CONTROL.RELEASE_STANDSTILL, system-signal=ACC_CONTROL_RELEASE_STANDSTILL
        data-element=LdSda.SafetyMcuFirmware.PlatformFirmware.VehicleContext.Tx_ACC_CONTROL.ITS_CONNECT_LEAD, system-signal=ACC_CONTROL_ITS_CONNECT_LEAD
        data-element=LdSda.SafetyMcuFirmware.PlatformFirmware.VehicleContext.Tx_ACC_CONTROL.ACCEL_CMD_ALT, system-signal=ACC_CONTROL_ACCEL_CMD_ALT
        data-element=LdSda.SafetyMcuFirmware.PlatformFirmware.VehicleContext.Tx_ACC_CONTROL.CHECKSUM, system-signal=ACC_CONTROL_CHECKSUM
        data-element=LdSda.SafetyMcuFirmware.PlatformFirmware.VehicleContext.Tx_LKAS_HUD.BARRIERS, system-signal=LKAS_HUD_BARRIERS
        data-element=LdSda.SafetyMcuFirmware.PlatformFirmware.VehicleContext.Tx_LKAS_HUD.RIGHT_LINE, system-signal=LKAS_HUD_RIGHT_LINE
        data-element=LdSda.SafetyMcuFirmware.PlatformFirmware.VehicleContext.Tx_LKAS_HUD.LEFT_LINE, system-signal=LKAS_HUD_LEFT_LINE
        data-element=LdSda.SafetyMcuFirmware.PlatformFirmware.VehicleContext.Tx_LKAS_HUD.LKAS_STATUS, system-signal=LKAS_HUD_LKAS_STATUS
        data-element=LdSda.SafetyMcuFirmware.PlatformFirmware.VehicleContext.Tx_LKAS_HUD.LDA_ALERT, system-signal=LKAS_HUD_LDA_ALERT
        data-element=LdSda.SafetyMcuFirmware.PlatformFirmware.VehicleContext.Tx_LKAS_HUD.LDW_EXIST, system-signal=LKAS_HUD_LDW_EXIST
        data-element=LdSda.SafetyMcuFirmware.PlatformFirmware.VehicleContext.Tx_LKAS_HUD.TWO_BEEPS, system-signal=LKAS_HUD_TWO_BEEPS
        data-element=LdSda.SafetyMcuFirmware.PlatformFirmware.VehicleContext.Tx_LKAS_HUD.ADJUSTING_CAMERA, system-signal=LKAS_HUD_ADJUSTING_CAMERA
        data-element=LdSda.SafetyMcuFirmware.PlatformFirmware.VehicleContext.Tx_LKAS_HUD.LDA_UNAVAILABLE_QUIET, system-signal=LKAS_HUD_LDA_UNAVAILABLE_QUIET
        data-element=LdSda.SafetyMcuFirmware.PlatformFirmware.VehicleContext.Tx_LKAS_HUD.LDA_MALFUNCTION, system-signal=LKAS_HUD_LDA_MALFUNCTION
        data-element=LdSda.SafetyMcuFirmware.PlatformFirmware.VehicleContext.Tx_LKAS_HUD.LDA_UNAVAILABLE, system-signal=LKAS_HUD_LDA_UNAVAILABLE
        data-element=LdSda.SafetyMcuFirmware.PlatformFirmware.VehicleContext.Tx_LKAS_HUD.LDA_SENSITIVITY, system-signal=LKAS_HUD_LDA_SENSITIVITY
        data-element=LdSda.SafetyMcuFirmware.PlatformFirmware.VehicleContext.Tx_LKAS_HUD.LDA_SA_TOGGLE, system-signal=LKAS_HUD_LDA_SA_TOGGLE
        data-element=LdSda.SafetyMcuFirmware.PlatformFirmware.VehicleContext.Tx_LKAS_HUD.LDA_MESSAGES, system-signal=LKAS_HUD_LDA_MESSAGES
        data-element=LdSda.SafetyMcuFirmware.PlatformFirmware.VehicleContext.Tx_LKAS_HUD.LDA_ON_MESSAGE, system-signal=LKAS_HUD_LDA_ON_MESSAGE
        data-element=LdSda.SafetyMcuFirmware.PlatformFirmware.VehicleContext.Tx_LKAS_HUD.REPEATED_BEEPS, system-signal=LKAS_HUD_REPEATED_BEEPS
        data-element=LdSda.SafetyMcuFirmware.PlatformFirmware.VehicleContext.Tx_LKAS_HUD.LANE_SWAY_TOGGLE, system-signal=LKAS_HUD_LANE_SWAY_TOGGLE
        data-element=LdSda.SafetyMcuFirmware.PlatformFirmware.VehicleContext.Tx_LKAS_HUD.LANE_SWAY_SENSITIVITY, system-signal=LKAS_HUD_LANE_SWAY_SENSITIVITY
        data-element=LdSda.SafetyMcuFirmware.PlatformFirmware.VehicleContext.Tx_LKAS_HUD.TAKE_CONTROL, system-signal=LKAS_HUD_TAKE_CONTROL
        data-element=LdSda.SafetyMcuFirmware.PlatformFirmware.VehicleContext.Tx_LKAS_HUD.LDA_FRONT_CAMERA_BLOCKED, system-signal=LKAS_HUD_LDA_FRONT_CAMERA_BLOCKED
        data-element=LdSda.SafetyMcuFirmware.PlatformFirmware.VehicleContext.Tx_LKAS_HUD.LANE_SWAY_BUZZER, system-signal=LKAS_HUD_LANE_SWAY_BUZZER
        data-element=LdSda.SafetyMcuFirmware.PlatformFirmware.VehicleContext.Tx_LKAS_HUD.LANE_SWAY_FLD, system-signal=LKAS_HUD_LANE_SWAY_FLD
        data-element=LdSda.SafetyMcuFirmware.PlatformFirmware.VehicleContext.Tx_LKAS_HUD.LANE_SWAY_WARNING, system-signal=LKAS_HUD_LANE_SWAY_WARNING
        data-element=LdSda.SafetyMcuFirmware.PlatformFirmware.VehicleContext.Tx_LKAS_HUD.SET_ME_X01, system-signal=LKAS_HUD_SET_ME_X01
        data-element=LdSda.SafetyMcuFirmware.PlatformFirmware.VehicleContext.Tx_LKAS_HUD.SET_ME_X02, system-signal=LKAS_HUD_SET_ME_X02
        data-element=LdSda.SafetyMcuFirmware.PlatformFirmware.VehicleContext.Tx_PCS_HUD.PCS_INDICATOR, system-signal=PCS_HUD_PCS_INDICATOR
        data-element=LdSda.SafetyMcuFirmware.PlatformFirmware.VehicleContext.Tx_PCS_HUD.FCW, system-signal=PCS_HUD_FCW
        data-element=LdSda.SafetyMcuFirmware.PlatformFirmware.VehicleContext.Tx_PCS_HUD.SET_ME_X20, system-signal=PCS_HUD_SET_ME_X20
        data-element=LdSda.SafetyMcuFirmware.PlatformFirmware.VehicleContext.Tx_PCS_HUD.PCS_DUST, system-signal=PCS_HUD_PCS_DUST
        data-element=LdSda.SafetyMcuFirmware.PlatformFirmware.VehicleContext.Tx_PCS_HUD.PCS_TEMP, system-signal=PCS_HUD_PCS_TEMP
        data-element=LdSda.SafetyMcuFirmware.PlatformFirmware.VehicleContext.Tx_PCS_HUD.PCS_DUST2, system-signal=PCS_HUD_PCS_DUST2
        data-element=LdSda.SafetyMcuFirmware.PlatformFirmware.VehicleContext.Tx_PCS_HUD.PCS_TEMP2, system-signal=PCS_HUD_PCS_TEMP2
        data-element=LdSda.SafetyMcuFirmware.PlatformFirmware.VehicleContext.Tx_PCS_HUD.SET_ME_X10, system-signal=PCS_HUD_SET_ME_X10
        data-element=LdSda.SafetyMcuFirmware.PlatformFirmware.VehicleContext.Tx_PCS_HUD.PCS_OFF, system-signal=PCS_HUD_PCS_OFF
        data-element=LdSda.SafetyMcuFirmware.PlatformFirmware.VehicleContext.Tx_PCS_HUD.FRD_ADJ, system-signal=PCS_HUD_FRD_ADJ
        data-element=LdSda.SafetyMcuFirmware.PlatformFirmware.VehicleContext.Tx_PCS_HUD.PCS_SENSITIVITY, system-signal=PCS_HUD_PCS_SENSITIVITY
        data-element=LdSda.SafetyMcuFirmware.PlatformFirmware.VehicleContext.Tx_PRE_COLLISION.COUNTER, system-signal=PRE_COLLISION_COUNTER
        data-element=LdSda.SafetyMcuFirmware.PlatformFirmware.VehicleContext.Tx_PRE_COLLISION.SET_ME_X00, system-signal=PRE_COLLISION_SET_ME_X00
        data-element=LdSda.SafetyMcuFirmware.PlatformFirmware.VehicleContext.Tx_PRE_COLLISION.FORCE, system-signal=PRE_COLLISION_FORCE
        data-element=LdSda.SafetyMcuFirmware.PlatformFirmware.VehicleContext.Tx_PRE_COLLISION.SET_ME_X002, system-signal=PRE_COLLISION_SET_ME_X002
        data-element=LdSda.SafetyMcuFirmware.PlatformFirmware.VehicleContext.Tx_PRE_COLLISION.BRAKE_STATUS, system-signal=PRE_COLLISION_BRAKE_STATUS
        data-element=LdSda.SafetyMcuFirmware.PlatformFirmware.VehicleContext.Tx_PRE_COLLISION.STATE, system-signal=PRE_COLLISION_STATE
        data-element=LdSda.SafetyMcuFirmware.PlatformFirmware.VehicleContext.Tx_PRE_COLLISION.SET_ME_X003, system-signal=PRE_COLLISION_SET_ME_X003
        data-element=LdSda.SafetyMcuFirmware.PlatformFirmware.VehicleContext.Tx_PRE_COLLISION.PRECOLLISION_ACTIVE, system-signal=PRE_COLLISION_PRECOLLISION_ACTIVE
        data-element=LdSda.SafetyMcuFirmware.PlatformFirmware.VehicleContext.Tx_PRE_COLLISION.CHECKSUM, system-signal=PRE_COLLISION_CHECKSUM
        data-element=LdSda.SafetyMcuFirmware.PlatformFirmware.VehicleContext.Tx_PRE_COLLISION_2.DSS1GDRV, system-signal=PRE_COLLISION_2_DSS1GDRV
        data-element=LdSda.SafetyMcuFirmware.PlatformFirmware.VehicleContext.Tx_PRE_COLLISION_2.PCSALM, system-signal=PRE_COLLISION_2_PCSALM
        data-element=LdSda.SafetyMcuFirmware.PlatformFirmware.VehicleContext.Tx_PRE_COLLISION_2.IBTRGR, system-signal=PRE_COLLISION_2_IBTRGR
        data-element=LdSda.SafetyMcuFirmware.PlatformFirmware.VehicleContext.Tx_PRE_COLLISION_2.PBATRGR, system-signal=PRE_COLLISION_2_PBATRGR
        data-element=LdSda.SafetyMcuFirmware.PlatformFirmware.VehicleContext.Tx_PRE_COLLISION_2.PREFILL, system-signal=PRE_COLLISION_2_PREFILL
        data-element=LdSda.SafetyMcuFirmware.PlatformFirmware.VehicleContext.Tx_PRE_COLLISION_2.AVSTRGR, system-signal=PRE_COLLISION_2_AVSTRGR
        data-element=LdSda.SafetyMcuFirmware.PlatformFirmware.VehicleContext.Tx_PRE_COLLISION_2.CHECKSUM, system-signal=PRE_COLLISION_2_CHECKSUM
        data-element=LdSda.SafetyMcuFirmware.PlatformFirmware.VehicleContext.Tx_STEERING_LKA.LKA_STATE, system-signal=STEERING_LKA_LKA_STATE
        data-element=LdSda.SafetyMcuFirmware.PlatformFirmware.VehicleContext.Tx_STEERING_LKA.STEER_REQUEST, system-signal=STEERING_LKA_STEER_REQUEST
        data-element=LdSda.SafetyMcuFirmware.PlatformFirmware.VehicleContext.Tx_STEERING_LKA.COUNTER, system-signal=STEERING_LKA_COUNTER
        data-element=LdSda.SafetyMcuFirmware.PlatformFirmware.VehicleContext.Tx_STEERING_LKA.SET_ME_1, system-signal=STEERING_LKA_SET_ME_1
        data-element=LdSda.SafetyMcuFirmware.PlatformFirmware.VehicleContext.Tx_STEERING_LKA.STEER_TORQUE_CMD, system-signal=STEERING_LKA_STEER_TORQUE_CMD
        data-element=LdSda.SafetyMcuFirmware.PlatformFirmware.VehicleContext.Tx_STEERING_LKA.CHECKSUM, system-signal=STEERING_LKA_CHECKSUM
        data-element=LdSda.SafetyMcuFirmware.PlatformFirmware.VehicleContext.Tx_STEERING_LTA.CHECKSUM, system-signal=STEERING_LTA_CHECKSUM
        data-element=LdSda.SafetyMcuFirmware.PlatformFirmware.VehicleContext.Tx_STEERING_LTA.SETME_X3, system-signal=STEERING_LTA_SETME_X3
        data-element=LdSda.SafetyMcuFirmware.PlatformFirmware.VehicleContext.Tx_STEERING_LTA.PERCENTAGE, system-signal=STEERING_LTA_PERCENTAGE
        data-element=LdSda.SafetyMcuFirmware.PlatformFirmware.VehicleContext.Tx_STEERING_LTA.TORQUE_WIND_DOWN, system-signal=STEERING_LTA_TORQUE_WIND_DOWN
        data-element=LdSda.SafetyMcuFirmware.PlatformFirmware.VehicleContext.Tx_STEERING_LTA.ANGLE, system-signal=STEERING_LTA_ANGLE
        data-element=LdSda.SafetyMcuFirmware.PlatformFirmware.VehicleContext.Tx_STEERING_LTA.STEER_ANGLE_CMD, system-signal=STEERING_LTA_STEER_ANGLE_CMD
        data-element=LdSda.SafetyMcuFirmware.PlatformFirmware.VehicleContext.Tx_STEERING_LTA.STEER_REQUEST_2, system-signal=STEERING_LTA_STEER_REQUEST_2
        data-element=LdSda.SafetyMcuFirmware.PlatformFirmware.VehicleContext.Tx_STEERING_LTA.LKA_ACTIVE, system-signal=STEERING_LTA_LKA_ACTIVE
        data-element=LdSda.SafetyMcuFirmware.PlatformFirmware.VehicleContext.Tx_STEERING_LTA.CLEAR_HOLD_STEERING_ALERT, system-signal=STEERING_LTA_CLEAR_HOLD_STEERING_ALERT
        data-element=LdSda.SafetyMcuFirmware.PlatformFirmware.VehicleContext.Tx_STEERING_LTA.COUNTER, system-signal=STEERING_LTA_COUNTER
        data-element=LdSda.SafetyMcuFirmware.PlatformFirmware.VehicleContext.Tx_STEERING_LTA.STEER_REQUEST, system-signal=STEERING_LTA_STEER_REQUEST
        data-element=LdSda.SafetyMcuFirmware.PlatformFirmware.VehicleContext.Tx_STEERING_LTA.SETME_X1, system-signal=STEERING_LTA_SETME_X1
        data-element=LdSda.SafetyMcuFirmware.SafetyLayer.VehicleContext.Rx_BRAKE_MODULE.BRAKE_PRESSURE, system-signal=BRAKE_MODULE_BRAKE_PRESSURE
        data-element=LdSda.SafetyMcuFirmware.SafetyLayer.VehicleContext.Rx_BRAKE_MODULE.BRAKE_POSITION, system-signal=BRAKE_MODULE_BRAKE_POSITION
        data-element=LdSda.SafetyMcuFirmware.SafetyLayer.VehicleContext.Rx_BRAKE_MODULE.BRAKE_PRESSED, system-signal=BRAKE_MODULE_BRAKE_PRESSED
        data-element=LdSda.SafetyMcuFirmware.SafetyLayer.VehicleContext.Rx_EPS_STATUS.IPAS_STATE, system-signal=EPS_STATUS_IPAS_STATE
        data-element=LdSda.SafetyMcuFirmware.SafetyLayer.VehicleContext.Rx_EPS_STATUS.LKA_STATE, system-signal=EPS_STATUS_LKA_STATE
        data-element=LdSda.SafetyMcuFirmware.SafetyLayer.VehicleContext.Rx_EPS_STATUS.LTA_STATE, system-signal=EPS_STATUS_LTA_STATE
        data-element=LdSda.SafetyMcuFirmware.SafetyLayer.VehicleContext.Rx_EPS_STATUS.TYPE, system-signal=EPS_STATUS_TYPE
        data-element=LdSda.SafetyMcuFirmware.SafetyLayer.VehicleContext.Rx_EPS_STATUS.CHECKSUM, system-signal=EPS_STATUS_CHECKSUM
        data-element=LdSda.SafetyMcuFirmware.SafetyLayer.VehicleContext.Rx_PCM_CRUISE.GAS_RELEASED, system-signal=PCM_CRUISE_GAS_RELEASED
        data-element=LdSda.SafetyMcuFirmware.SafetyLayer.VehicleContext.Rx_PCM_CRUISE.CRUISE_ACTIVE, system-signal=PCM_CRUISE_CRUISE_ACTIVE
        data-element=LdSda.SafetyMcuFirmware.SafetyLayer.VehicleContext.Rx_PCM_CRUISE.ACC_BRAKING, system-signal=PCM_CRUISE_ACC_BRAKING
        data-element=LdSda.SafetyMcuFirmware.SafetyLayer.VehicleContext.Rx_PCM_CRUISE.ACCEL_NET, system-signal=PCM_CRUISE_ACCEL_NET
        data-element=LdSda.SafetyMcuFirmware.SafetyLayer.VehicleContext.Rx_PCM_CRUISE.NEUTRAL_FORCE, system-signal=PCM_CRUISE_NEUTRAL_FORCE
        data-element=LdSda.SafetyMcuFirmware.SafetyLayer.VehicleContext.Rx_PCM_CRUISE.CRUISE_STATE, system-signal=PCM_CRUISE_CRUISE_STATE
        data-element=LdSda.SafetyMcuFirmware.SafetyLayer.VehicleContext.Rx_PCM_CRUISE.CANCEL_REQ, system-signal=PCM_CRUISE_CANCEL_REQ
        data-element=LdSda.SafetyMcuFirmware.SafetyLayer.VehicleContext.Rx_PCM_CRUISE.CHECKSUM, system-signal=PCM_CRUISE_CHECKSUM
        data-element=LdSda.SafetyMcuFirmware.SafetyLayer.VehicleContext.Rx_PCM_CRUISE_2.BRAKE_PRESSED, system-signal=PCM_CRUISE_2_BRAKE_PRESSED
        data-element=LdSda.SafetyMcuFirmware.SafetyLayer.VehicleContext.Rx_PCM_CRUISE_2.PCM_FOLLOW_DISTANCE, system-signal=PCM_CRUISE_2_PCM_FOLLOW_DISTANCE
        data-element=LdSda.SafetyMcuFirmware.SafetyLayer.VehicleContext.Rx_PCM_CRUISE_2.LOW_SPEED_LOCKOUT, system-signal=PCM_CRUISE_2_LOW_SPEED_LOCKOUT
        data-element=LdSda.SafetyMcuFirmware.SafetyLayer.VehicleContext.Rx_PCM_CRUISE_2.MAIN_ON, system-signal=PCM_CRUISE_2_MAIN_ON
        data-element=LdSda.SafetyMcuFirmware.SafetyLayer.VehicleContext.Rx_PCM_CRUISE_2.SET_SPEED, system-signal=PCM_CRUISE_2_SET_SPEED
        data-element=LdSda.SafetyMcuFirmware.SafetyLayer.VehicleContext.Rx_PCM_CRUISE_2.ACC_FAULTED, system-signal=PCM_CRUISE_2_ACC_FAULTED
        data-element=LdSda.SafetyMcuFirmware.SafetyLayer.VehicleContext.Rx_PCM_CRUISE_2.CHECKSUM, system-signal=PCM_CRUISE_2_CHECKSUM
        data-element=LdSda.SafetyMcuFirmware.SafetyLayer.VehicleContext.Rx_STEER_TORQUE_SENSOR.STEER_TORQUE_EPS, system-signal=STEER_TORQUE_SENSOR_STEER_TORQUE_EPS
        data-element=LdSda.SafetyMcuFirmware.SafetyLayer.VehicleContext.Rx_STEER_TORQUE_SENSOR.STEER_TORQUE_DRIVER, system-signal=STEER_TORQUE_SENSOR_STEER_TORQUE_DRIVER
        data-element=LdSda.SafetyMcuFirmware.SafetyLayer.VehicleContext.Rx_STEER_TORQUE_SENSOR.STEER_ANGLE, system-signal=STEER_TORQUE_SENSOR_STEER_ANGLE
        data-element=LdSda.SafetyMcuFirmware.SafetyLayer.VehicleContext.Rx_STEER_TORQUE_SENSOR.STEER_ANGLE_INITIALIZING, system-signal=STEER_TORQUE_SENSOR_STEER_ANGLE_INITIALIZING
        data-element=LdSda.SafetyMcuFirmware.SafetyLayer.VehicleContext.Rx_STEER_TORQUE_SENSOR.STEER_OVERRIDE, system-signal=STEER_TORQUE_SENSOR_STEER_OVERRIDE
        data-element=LdSda.SafetyMcuFirmware.SafetyLayer.VehicleContext.Rx_STEER_TORQUE_SENSOR.CHECKSUM, system-signal=STEER_TORQUE_SENSOR_CHECKSUM
        data-element=LdSda.SafetyMcuFirmware.SafetyLayer.VehicleContext.Rx_WHEEL_SPEEDS.WHEEL_SPEED_FR_FAULT, system-signal=WHEEL_SPEEDS_WHEEL_SPEED_FR_FAULT
        data-element=LdSda.SafetyMcuFirmware.SafetyLayer.VehicleContext.Rx_WHEEL_SPEEDS.WHEEL_SPEED_FR, system-signal=WHEEL_SPEEDS_WHEEL_SPEED_FR
        data-element=LdSda.SafetyMcuFirmware.SafetyLayer.VehicleContext.Rx_WHEEL_SPEEDS.WHEEL_SPEED_FL_FAULT, system-signal=WHEEL_SPEEDS_WHEEL_SPEED_FL_FAULT
        data-element=LdSda.SafetyMcuFirmware.SafetyLayer.VehicleContext.Rx_WHEEL_SPEEDS.WHEEL_SPEED_FL, system-signal=WHEEL_SPEEDS_WHEEL_SPEED_FL
        data-element=LdSda.SafetyMcuFirmware.SafetyLayer.VehicleContext.Rx_WHEEL_SPEEDS.WHEEL_SPEED_RR_FAULT, system-signal=WHEEL_SPEEDS_WHEEL_SPEED_RR_FAULT
        data-element=LdSda.SafetyMcuFirmware.SafetyLayer.VehicleContext.Rx_WHEEL_SPEEDS.WHEEL_SPEED_RR, system-signal=WHEEL_SPEEDS_WHEEL_SPEED_RR
        data-element=LdSda.SafetyMcuFirmware.SafetyLayer.VehicleContext.Rx_WHEEL_SPEEDS.WHEEL_SPEED_RL_FAULT, system-signal=WHEEL_SPEEDS_WHEEL_SPEED_RL_FAULT
        data-element=LdSda.SafetyMcuFirmware.SafetyLayer.VehicleContext.Rx_WHEEL_SPEEDS.WHEEL_SPEED_RL, system-signal=WHEEL_SPEEDS_WHEEL_SPEED_RL
      sw-mappings:
        7 x swc to ecu mapping:
          To_Ext_AbsVsc: component=VehicleContext.Ext_AbsVsc, ecu-instance=Ext_AbsVsc
          To_Ext_Cluster: component=VehicleContext.Ext_Cluster, ecu-instance=Ext_Cluster
          To_Ext_EPS: component=VehicleContext.Ext_EPS, ecu-instance=Ext_EPS
          To_Ext_ForwardCamera: component=VehicleContext.Ext_ForwardCamera, ecu-instance=Ext_ForwardCamera
          To_Ext_PCM: component=VehicleContext.Ext_PCM, ecu-instance=Ext_PCM
          To_LD_SafetyMcu: ecu-instance=LD_SafetyMcu
            component:
              VehicleContext.LdSda.SafetyMcuFirmware.PlatformFirmware
              VehicleContext.LdSda.SafetyMcuFirmware.SafetyLayer
          To_LD_SoC: ecu-instance=LD_SoC
            component:
              VehicleContext.LdSda.SocSoftware.Proc_card
              VehicleContext.LdSda.SocSoftware.Proc_cereal
              VehicleContext.LdSda.SocSoftware.Proc_controlsd
              VehicleContext.LdSda.SocSoftware.Proc_dm
              VehicleContext.LdSda.SocSoftware.Proc_estimators
              VehicleContext.LdSda.SocSoftware.Proc_hardwared
              VehicleContext.LdSda.SocSoftware.Proc_hmi
              VehicleContext.LdSda.SocSoftware.Proc_manager
              VehicleContext.LdSda.SocSoftware.Proc_modeld
              VehicleContext.LdSda.SocSoftware.Proc_pandad
              VehicleContext.LdSda.SocSoftware.Proc_plannerd
              VehicleContext.LdSda.SocSoftware.Proc_radard
              VehicleContext.LdSda.SocSoftware.Proc_remoteAndLogging
              VehicleContext.LdSda.SocSoftware.Proc_selfdrived
    root-software-compositions:
      root sw composition prototype VehicleContext: software-composition=VehicleContext
